VERSION "dbc-export 1 2025.20.8"

NS_ :

BS_:

BU_: ADSP APB APP APS APSB BB BMS CC CMP CMPD CP DAS DI DIF DIR DPB EPAS3P EPAS3S EPASTP EPASTS EPBL EPBR ESP GTW HVP IBST ICR IDB OCS1P ODIN PARK PCS PLG PM PMF PMR PTC RADC RCM RCM2 RCU SCCM SDCR TAS TCU TPMS TRCM UDS UI UIS UMC USM VC VCFRONT VCLEFT VCRIGHT VCSEC

BO_ 999 DPB_alertMatrix: 8 DPB
 SG_ DPB_matrixIndex M : 0|4@1+ (1,0) [0|15] "" Vector__XXX
 SG_ DPB_a001_pPlungerSensorOffsetHig m0 : 4|1@1+ (1,0) [0|1] "" Vector__XXX
 SG_ DPB_a002_pMC2SensorOffsetHigh m0 : 5|1@1+ (1,0) [0|1] "" Vector__XXX
 SG_ DPB_a003_AswEEPROMReadFailure m0 : 6|1@1+ (1,0) [0|1] "" Vector__XXX
 SG_ DPB_a004_assertionFault m0 : 7|1@1+ (1,0) [0|1] "" Vector__XXX
 SG_ DPB_a005_hardPedalChar m0 : 8|1@1+ (1,0) [0|1] "" Vector__XXX
 SG_ DPB_a006_hardPedalCharGoodCheck m0 : 9|1@1+ (1,0) [0|1] "" Vector__XXX
 SG_ DPB_a007_PMCLeakageDetected m0 : 10|1@1+ (1,0) [0|1] "" Vector__XXX
 SG_ DPB_a008_LiPSPts1Offset m0 : 11|1@1+ (1,0) [0|1] "" Vector__XXX
 SG_ DPB_a009_LiPSPts2Offset m0 : 12|1@1+ (1,0) [0|1] "" Vector__XXX
 SG_ DPB_a010_LiPSPtsConsistency m0 : 13|1@1+ (1,0) [0|1] "" Vector__XXX
 SG_ DPB_a011_PtsNonZeroStage1 m0 : 14|1@1+ (1,0) [0|1] "" Vector__XXX
 SG_ DPB_a012_PtsNonZeroStage2 m0 : 15|1@1+ (1,0) [0|1] "" Vector__XXX
 SG_ DPB_a013_softPedalChar m0 : 16|1@1+ (1,0) [0|1] "" Vector__XXX
 SG_ DPB_a014_CANControllerHWFault m0 : 17|1@1+ (1,0) [0|1] "" Vector__XXX
 SG_ DPB_a015_CAN1BusOff m0 : 18|1@1+ (1,0) [0|1] "" Vector__XXX
 SG_ DPB_a016_CAN2BusOff m0 : 19|1@1+ (1,0) [0|1] "" Vector__XXX
 SG_ DPB_a017_largeLeakageDetected m0 : 20|1@1+ (1,0) [0|1] "" Vector__XXX
 SG_ DPB_a018_largeLeakageDetectedGoo m0 : 21|1@1+ (1,0) [0|1] "" Vector__XXX
 SG_ DPB_a019_DETReportError m0 : 22|1@1+ (1,0) [0|1] "" Vector__XXX
 SG_ DPB_a020_ecuHuMismatch m0 : 23|1@1+ (1,0) [0|1] "" Vector__XXX
 SG_ DPB_a021_brakeSystemOverheatLvl1 m0 : 24|1@1+ (1,0) [0|1] "" Vector__XXX
 SG_ DPB_a022_brakeSystemOverheatLvl2 m0 : 25|1@1+ (1,0) [0|1] "" Vector__XXX
 SG_ DPB_a023_initialPlungerCheckFail m0 : 26|1@1+ (1,0) [0|1] "" Vector__XXX
 SG_ DPB_a024_ESPLDMFailure m0 : 27|1@1+ (1,0) [0|1] "" Vector__XXX
 SG_ DPB_a025_backupCircuitLeakage m0 : 28|1@1+ (1,0) [0|1] "" Vector__XXX
 SG_ DPB_a026_LiPSIDTimeout m0 : 29|1@1+ (1,0) [0|1] "" Vector__XXX
 SG_ DPB_a027_motorTempHighLevel1 m0 : 30|1@1+ (1,0) [0|1] "" Vector__XXX
 SG_ DPB_a028_motorTempHighLevel2 m0 : 31|1@1+ (1,0) [0|1] "" Vector__XXX
 SG_ DPB_a029_motorTestFault m0 : 32|1@1+ (1,0) [0|1] "" Vector__XXX
 SG_ DPB_a030_notShutDownRight m0 : 33|1@1+ (1,0) [0|1] "" Vector__XXX
 SG_ DPB_a031_HWParamReadFailed m0 : 34|1@1+ (1,0) [0|1] "" Vector__XXX
 SG_ DPB_a032_HWParamWriteFailed m0 : 35|1@1+ (1,0) [0|1] "" Vector__XXX
 SG_ DPB_a033_motorDynamicLimited m0 : 36|1@1+ (1,0) [0|1] "" Vector__XXX
 SG_ DPB_a034_lipsMemoryEmpty m0 : 37|1@1+ (1,0) [0|1] "" Vector__XXX
 SG_ DPB_a035_PDURouterinitialization m0 : 38|1@1+ (1,0) [0|1] "" Vector__XXX
 SG_ DPB_a036_lossOfPDUInstanceDetect m0 : 39|1@1+ (1,0) [0|1] "" Vector__XXX
 SG_ DPB_a037_plungerCircuitPressHigh m0 : 40|1@1+ (1,0) [0|1] "" Vector__XXX
 SG_ DPB_a038_plungerCircuitPressHigh m0 : 41|1@1+ (1,0) [0|1] "" Vector__XXX
 SG_ DPB_a039_plungerCircuitPressLow m0 : 42|1@1+ (1,0) [0|1] "" Vector__XXX
 SG_ DPB_a040_plungerCircuitPressLowG m0 : 43|1@1+ (1,0) [0|1] "" Vector__XXX
 SG_ DPB_a041_PSCGearRatioReadFault m0 : 44|1@1+ (1,0) [0|1] "" Vector__XXX
 SG_ DPB_a042_motorLoadPressImplausib m0 : 45|1@1+ (1,0) [0|1] "" Vector__XXX
 SG_ DPB_a043_PSCMotorSizeReadFault m0 : 46|1@1+ (1,0) [0|1] "" Vector__XXX
 SG_ DPB_a044_supplyOvervoltageLvl1 m0 : 47|1@1+ (1,0) [0|1] "" Vector__XXX
 SG_ DPB_a045_supplyOvervoltageLvl2 m0 : 48|1@1+ (1,0) [0|1] "" Vector__XXX
 SG_ DPB_a046_supplyOvervoltageLvl3 m0 : 49|1@1+ (1,0) [0|1] "" Vector__XXX
 SG_ DPB_a047_pPlungerPlausCheckFailu m0 : 50|1@1+ (1,0) [0|1] "" Vector__XXX
 SG_ DPB_a048_supplyUndervoltageLvl1 m0 : 51|1@1+ (1,0) [0|1] "" Vector__XXX
 SG_ DPB_a049_supplyUndervoltageLvl2 m0 : 52|1@1+ (1,0) [0|1] "" Vector__XXX
 SG_ DPB_a050_supplyUndervoltageLvl3 m0 : 53|1@1+ (1,0) [0|1] "" Vector__XXX
 SG_ DPB_a051_PSCVoltageImplausible m0 : 54|1@1+ (1,0) [0|1] "" Vector__XXX
 SG_ DPB_a052_PSIDTimeOut m0 : 55|1@1+ (1,0) [0|1] "" Vector__XXX
 SG_ DPB_a053_hydraulicAssemblyModeAc m0 : 56|1@1+ (1,0) [0|1] "" Vector__XXX
 SG_ DPB_a054_unsupportedHW m0 : 57|1@1+ (1,0) [0|1] "" Vector__XXX
 SG_ DPB_a055_unsupportedSeriesHWDete m0 : 58|1@1+ (1,0) [0|1] "" Vector__XXX
 SG_ DPB_a056_AdcPeripheralFault m0 : 59|1@1+ (1,0) [0|1] "" Vector__XXX
 SG_ DPB_a057_AdcPinTest m0 : 60|1@1+ (1,0) [0|1] "" Vector__XXX
 SG_ DPB_a058_AdcSelftestC5P m0 : 61|1@1+ (1,0) [0|1] "" Vector__XXX
 SG_ DPB_a059_factoryModeActive m0 : 62|1@1+ (1,0) [0|1] "" Vector__XXX
 SG_ DPB_a060_motorBridgeDriverFault m0 : 63|1@1+ (1,0) [0|1] "" Vector__XXX
 SG_ DPB_a061_bridgeSwitchInitError m1 : 4|1@1+ (1,0) [0|1] "" Vector__XXX
 SG_ DPB_a062_loadDumpOnFSLTest m1 : 5|1@1+ (1,0) [0|1] "" Vector__XXX
 SG_ DPB_a063_motorConfigMismatch m1 : 6|1@1+ (1,0) [0|1] "" Vector__XXX
 SG_ DPB_a064_current1OffsetHigh m1 : 7|1@1+ (1,0) [0|1] "" Vector__XXX
 SG_ DPB_a065_current1OffsetLow m1 : 8|1@1+ (1,0) [0|1] "" Vector__XXX
 SG_ DPB_a066_current2OffsetHigh m1 : 9|1@1+ (1,0) [0|1] "" Vector__XXX
 SG_ DPB_a067_current2OffsetLow m1 : 10|1@1+ (1,0) [0|1] "" Vector__XXX
 SG_ DPB_a068_BLMMuxerTimeoutError m1 : 11|1@1+ (1,0) [0|1] "" Vector__XXX
 SG_ DPB_a069_OBDCurrent1OORHigh m1 : 12|1@1+ (1,0) [0|1] "" Vector__XXX
 SG_ DPB_a070_OBDCurrent1OORLow m1 : 13|1@1+ (1,0) [0|1] "" Vector__XXX
 SG_ DPB_a071_OBDCurrent2OORHigh m1 : 14|1@1+ (1,0) [0|1] "" Vector__XXX
 SG_ DPB_a072_OBDCurrent2OORLow m1 : 15|1@1+ (1,0) [0|1] "" Vector__XXX
 SG_ DPB_a073_rotorCosOutOfRangeHigh m1 : 16|1@1+ (1,0) [0|1] "" Vector__XXX
 SG_ DPB_a074_rotorCosOutOfRangeLow m1 : 17|1@1+ (1,0) [0|1] "" Vector__XXX
 SG_ DPB_a075_rotorSinOutOfRangeHigh m1 : 18|1@1+ (1,0) [0|1] "" Vector__XXX
 SG_ DPB_a076_rotorSinOutOfRangeLow m1 : 19|1@1+ (1,0) [0|1] "" Vector__XXX
 SG_ DPB_a077_tempSens1ShortToSupply m1 : 20|1@1+ (1,0) [0|1] "" Vector__XXX
 SG_ DPB_a078_tempSens1ShortToGround m1 : 21|1@1+ (1,0) [0|1] "" Vector__XXX
 SG_ DPB_a079_tempSens2ShortToSupply m1 : 22|1@1+ (1,0) [0|1] "" Vector__XXX
 SG_ DPB_a080_tempSens2ShortToGround m1 : 23|1@1+ (1,0) [0|1] "" Vector__XXX
 SG_ DPB_a081_tempSensImplausVoltage m1 : 24|1@1+ (1,0) [0|1] "" Vector__XXX
 SG_ DPB_a082_chargePumpFault m1 : 25|1@1+ (1,0) [0|1] "" Vector__XXX
 SG_ DPB_a083_chargePumpUndervoltage m1 : 26|1@1+ (1,0) [0|1] "" Vector__XXX
 SG_ DPB_a084_RBCPUException m1 : 27|1@1+ (1,0) [0|1] "" Vector__XXX
 SG_ DPB_a085_infoFailureWrongCUBASHa m1 : 28|1@1+ (1,0) [0|1] "" Vector__XXX
 SG_ DPB_a086_diagHydProtectionPressF m1 : 29|1@1+ (1,0) [0|1] "" Vector__XXX
 SG_ DPB_a087_diagHydProtectionVlvFau m1 : 30|1@1+ (1,0) [0|1] "" Vector__XXX
 SG_ DPB_a088_DMATransferError m1 : 31|1@1+ (1,0) [0|1] "" Vector__XXX
 SG_ DPB_a089_ecuBandgap m1 : 32|1@1+ (1,0) [0|1] "" Vector__XXX
 SG_ DPB_a090_flashFault m1 : 33|1@1+ (1,0) [0|1] "" Vector__XXX
 SG_ DPB_a091_MRGPathTestFault m1 : 34|1@1+ (1,0) [0|1] "" Vector__XXX
 SG_ DPB_a092_decoupleBitTestFault m1 : 35|1@1+ (1,0) [0|1] "" Vector__XXX
 SG_ DPB_a093_ecuBistFaultCtrFault m1 : 36|1@1+ (1,0) [0|1] "" Vector__XXX
 SG_ DPB_a094_ecuClockTestFault m1 : 37|1@1+ (1,0) [0|1] "" Vector__XXX
 SG_ DPB_a095_ecuEnableElHighFault m1 : 38|1@1+ (1,0) [0|1] "" Vector__XXX
 SG_ DPB_a096_ecuEnableElLowFault m1 : 39|1@1+ (1,0) [0|1] "" Vector__XXX
 SG_ DPB_a097_ecuEnableHyHighFault m1 : 40|1@1+ (1,0) [0|1] "" Vector__XXX
 SG_ DPB_a098_ecuEnableHyLowFault m1 : 41|1@1+ (1,0) [0|1] "" Vector__XXX
 SG_ DPB_a099_ecuEnContinuousError m1 : 42|1@1+ (1,0) [0|1] "" Vector__XXX
 SG_ DPB_a100_ecuErrpinCounterFault m1 : 43|1@1+ (1,0) [0|1] "" Vector__XXX
 SG_ DPB_a101_ecuFastWdTestFault m1 : 44|1@1+ (1,0) [0|1] "" Vector__XXX
 SG_ DPB_a102_ecuVrOnWhileWdTimeout m1 : 45|1@1+ (1,0) [0|1] "" Vector__XXX
 SG_ DPB_a103_ecuVrViaSpiFails m1 : 46|1@1+ (1,0) [0|1] "" Vector__XXX
 SG_ DPB_a104_ecuWdStartuptestFault m1 : 47|1@1+ (1,0) [0|1] "" Vector__XXX
 SG_ DPB_a105_ecuWdSContinuousError m1 : 48|1@1+ (1,0) [0|1] "" Vector__XXX
 SG_ DPB_a106_ecuBistCmdTestFault m1 : 49|1@1+ (1,0) [0|1] "" Vector__XXX
 SG_ DPB_a107_vrOnFails m1 : 50|1@1+ (1,0) [0|1] "" Vector__XXX
 SG_ DPB_a108_GTMRefFrequencyError m1 : 51|1@1+ (1,0) [0|1] "" Vector__XXX
 SG_ DPB_a109_GTMTbuMonError m1 : 52|1@1+ (1,0) [0|1] "" Vector__XXX
 SG_ DPB_a110_HWBISTError m1 : 53|1@1+ (1,0) [0|1] "" Vector__XXX
 SG_ DPB_a111_hydraulicHardUndervolta m1 : 54|1@1+ (1,0) [0|1] "" Vector__XXX
 SG_ DPB_a112_hydraulicUndervoltage m1 : 55|1@1+ (1,0) [0|1] "" Vector__XXX
 SG_ DPB_a113_LiPS1SentLineHigh m1 : 56|1@1+ (1,0) [0|1] "" Vector__XXX
 SG_ DPB_a114_LiPS1SentLineLow m1 : 57|1@1+ (1,0) [0|1] "" Vector__XXX
 SG_ DPB_a115_LiPS1SentSensor m1 : 58|1@1+ (1,0) [0|1] "" Vector__XXX
 SG_ DPB_a116_LiPS1SentTransmission m1 : 59|1@1+ (1,0) [0|1] "" Vector__XXX
 SG_ DPB_a117_LiPS2PwmLineHigh m1 : 60|1@1+ (1,0) [0|1] "" Vector__XXX
 SG_ DPB_a118_LiPS2PwmLineLow m1 : 61|1@1+ (1,0) [0|1] "" Vector__XXX
 SG_ DPB_a119_LiPS2PwmTransmission m1 : 62|1@1+ (1,0) [0|1] "" Vector__XXX
 SG_ DPB_a120_LiPSOutOfRangeHigh m1 : 63|1@1+ (1,0) [0|1] "" Vector__XXX
 SG_ DPB_a121_LiPSOutOfRangeLow m2 : 4|1@1+ (1,0) [0|1] "" Vector__XXX
 SG_ DPB_a122_micAsicClkInError m2 : 5|1@1+ (1,0) [0|1] "" Vector__XXX
 SG_ DPB_a123_micAsicInitTestError m2 : 6|1@1+ (1,0) [0|1] "" Vector__XXX
 SG_ DPB_a124_asicOscillatorError m2 : 7|1@1+ (1,0) [0|1] "" Vector__XXX
 SG_ DPB_a125_B6AsicFault m2 : 8|1@1+ (1,0) [0|1] "" Vector__XXX
 SG_ DPB_a126_MICB6TransferError m2 : 9|1@1+ (1,0) [0|1] "" Vector__XXX
 SG_ DPB_a127_hydraulicAsicShortCircu m2 : 10|1@1+ (1,0) [0|1] "" Vector__XXX
 SG_ DPB_a128_micSpiTransferError m2 : 11|1@1+ (1,0) [0|1] "" Vector__XXX
 SG_ DPB_a129_AsicTrimmingNotComplete m2 : 12|1@1+ (1,0) [0|1] "" Vector__XXX
 SG_ DPB_a130_AsicMalfunctionDetected m2 : 13|1@1+ (1,0) [0|1] "" Vector__XXX
 SG_ DPB_a131_ASICOvercurrentOnGPIO25 m2 : 14|1@1+ (1,0) [0|1] "" Vector__XXX
 SG_ DPB_a132_ASICOvercurrentOnGPIO25 m2 : 15|1@1+ (1,0) [0|1] "" Vector__XXX
 SG_ DPB_a133_ASICOvercurrentOnGPIO50 m2 : 16|1@1+ (1,0) [0|1] "" Vector__XXX
 SG_ DPB_a134_ASICOvercurrentOnGPIO50 m2 : 17|1@1+ (1,0) [0|1] "" Vector__XXX
 SG_ DPB_a135_ASICOvercurrentOnGPIO50 m2 : 18|1@1+ (1,0) [0|1] "" Vector__XXX
 SG_ DPB_a136_ASICOvercurrentOnGPIO50 m2 : 19|1@1+ (1,0) [0|1] "" Vector__XXX
 SG_ DPB_a137_ASICOvercurrentOnWRHS m2 : 20|1@1+ (1,0) [0|1] "" Vector__XXX
 SG_ DPB_a138_DIchassisControlCounter m2 : 21|1@1+ (1,0) [0|1] "" Vector__XXX
 SG_ DPB_a139_DIchassisControlChecksu m2 : 22|1@1+ (1,0) [0|1] "" Vector__XXX
 SG_ DPB_a140_DIchassisControlDLC m2 : 23|1@1+ (1,0) [0|1] "" Vector__XXX
 SG_ DPB_a141_DIchassisControlTimeout m2 : 24|1@1+ (1,0) [0|1] "" Vector__XXX
 SG_ DPB_a142_DIsystemStatusCounter m2 : 25|1@1+ (1,0) [0|1] "" Vector__XXX
 SG_ DPB_a143_DIsystemStatusChecksum m2 : 26|1@1+ (1,0) [0|1] "" Vector__XXX
 SG_ DPB_a144_DIsystemStatusDLC m2 : 27|1@1+ (1,0) [0|1] "" Vector__XXX
 SG_ DPB_a145_DIsystemStatusTimeout m2 : 28|1@1+ (1,0) [0|1] "" Vector__XXX
 SG_ DPB_a146_DIFtorqueCounter m2 : 29|1@1+ (1,0) [0|1] "" Vector__XXX
 SG_ DPB_a147_DIFtorqueChecksum m2 : 30|1@1+ (1,0) [0|1] "" Vector__XXX
 SG_ DPB_a148_DIFtorqueDLC m2 : 31|1@1+ (1,0) [0|1] "" Vector__XXX
 SG_ DPB_a149_DIFtorqueTimeout m2 : 32|1@1+ (1,0) [0|1] "" Vector__XXX
 SG_ DPB_a150_DIRtorqueCounter m2 : 33|1@1+ (1,0) [0|1] "" Vector__XXX
 SG_ DPB_a151_DIRtorqueChecksum m2 : 34|1@1+ (1,0) [0|1] "" Vector__XXX
 SG_ DPB_a152_DIRtorqueDLC m2 : 35|1@1+ (1,0) [0|1] "" Vector__XXX
 SG_ DPB_a153_DIRtorqueTimeout m2 : 36|1@1+ (1,0) [0|1] "" Vector__XXX
 SG_ DPB_a154_EPBLstatusCounter m2 : 37|1@1+ (1,0) [0|1] "" Vector__XXX
 SG_ DPB_a155_EPBLstatusChecksum m2 : 38|1@1+ (1,0) [0|1] "" Vector__XXX
 SG_ DPB_a156_EPBLstatusDLC m2 : 39|1@1+ (1,0) [0|1] "" Vector__XXX
 SG_ DPB_a157_EPBLstatusTimeout m2 : 40|1@1+ (1,0) [0|1] "" Vector__XXX
 SG_ DPB_a158_EPBRstatusCounter m2 : 41|1@1+ (1,0) [0|1] "" Vector__XXX
 SG_ DPB_a159_EPBRstatusChecksum m2 : 42|1@1+ (1,0) [0|1] "" Vector__XXX
 SG_ DPB_a160_EPBRstatusDLC m2 : 43|1@1+ (1,0) [0|1] "" Vector__XXX
 SG_ DPB_a161_EPBRstatusTimeout m2 : 44|1@1+ (1,0) [0|1] "" Vector__XXX
 SG_ DPB_a162_ESP_modulator1Counter m2 : 45|1@1+ (1,0) [0|1] "" Vector__XXX
 SG_ DPB_a163_ESP_modulator1Checksum m2 : 46|1@1+ (1,0) [0|1] "" Vector__XXX
 SG_ DPB_a164_ESP_modulator1DLC m2 : 47|1@1+ (1,0) [0|1] "" Vector__XXX
 SG_ DPB_a165_ESP_modulator1Timeout m2 : 48|1@1+ (1,0) [0|1] "" Vector__XXX
 SG_ DPB_a166_ESP_chassis3Counter m2 : 49|1@1+ (1,0) [0|1] "" Vector__XXX
 SG_ DPB_a167_ESP_chassis3Checksum m2 : 50|1@1+ (1,0) [0|1] "" Vector__XXX
 SG_ DPB_a168_ESP_chassis3DLC m2 : 51|1@1+ (1,0) [0|1] "" Vector__XXX
 SG_ DPB_a169_ESP_chassis3Timeout m2 : 52|1@1+ (1,0) [0|1] "" Vector__XXX
 SG_ DPB_a170_ESP_modulator2Counter m2 : 53|1@1+ (1,0) [0|1] "" Vector__XXX
 SG_ DPB_a171_ESP_modulator2Checksum m2 : 54|1@1+ (1,0) [0|1] "" Vector__XXX
 SG_ DPB_a172_ESP_modulator2DLC m2 : 55|1@1+ (1,0) [0|1] "" Vector__XXX
 SG_ DPB_a173_ESP_modulator2Timeout m2 : 56|1@1+ (1,0) [0|1] "" Vector__XXX
 SG_ DPB_a174_ESP_modulator3Counter m2 : 57|1@1+ (1,0) [0|1] "" Vector__XXX
 SG_ DPB_a175_ESP_modulator3Checksum m2 : 58|1@1+ (1,0) [0|1] "" Vector__XXX
 SG_ DPB_a176_ESP_modulator3DLC m2 : 59|1@1+ (1,0) [0|1] "" Vector__XXX
 SG_ DPB_a177_ESP_modulator3Timeout m2 : 60|1@1+ (1,0) [0|1] "" Vector__XXX
 SG_ DPB_a178_PMstate2Counter m2 : 61|1@1+ (1,0) [0|1] "" Vector__XXX
 SG_ DPB_a179_PMstate2Checksum m2 : 62|1@1+ (1,0) [0|1] "" Vector__XXX
 SG_ DPB_a180_PMstate2DLC m2 : 63|1@1+ (1,0) [0|1] "" Vector__XXX
 SG_ DPB_a181_PMstate2Timeout m3 : 4|1@1+ (1,0) [0|1] "" Vector__XXX
 SG_ DPB_a182_RCMInertial2Counter m3 : 5|1@1+ (1,0) [0|1] "" Vector__XXX
 SG_ DPB_a183_RCMInertial2Checksum m3 : 6|1@1+ (1,0) [0|1] "" Vector__XXX
 SG_ DPB_a184_RCMInertial2DLC m3 : 7|1@1+ (1,0) [0|1] "" Vector__XXX
 SG_ DPB_a185_RCMInertial2Timeout m3 : 8|1@1+ (1,0) [0|1] "" Vector__XXX
 SG_ DPB_a186_LVPowerStateTimeout m3 : 9|1@1+ (1,0) [0|1] "" Vector__XXX
 SG_ DPB_a187_LVPowerStateChecksum m3 : 10|1@1+ (1,0) [0|1] "" Vector__XXX
 SG_ DPB_a188_LVPowerStateDLC m3 : 11|1@1+ (1,0) [0|1] "" Vector__XXX
 SG_ DPB_a189_LVPowerStateCounter m3 : 12|1@1+ (1,0) [0|1] "" Vector__XXX
 SG_ DPB_a190_VCLEFTepbmStatusCounter m3 : 13|1@1+ (1,0) [0|1] "" Vector__XXX
 SG_ DPB_a191_VCLEFTepbmStatusChecksu m3 : 14|1@1+ (1,0) [0|1] "" Vector__XXX
 SG_ DPB_a192_VCLEFTepbmStatusDLC m3 : 15|1@1+ (1,0) [0|1] "" Vector__XXX
 SG_ DPB_a193_VCLEFTepbmStatusTimeout m3 : 16|1@1+ (1,0) [0|1] "" Vector__XXX
 SG_ DPB_a194_VCRIGHTepbmStatusCounte m3 : 17|1@1+ (1,0) [0|1] "" Vector__XXX
 SG_ DPB_a195_VCRIGHTepbmStatusChecks m3 : 18|1@1+ (1,0) [0|1] "" Vector__XXX
 SG_ DPB_a196_VCRIGHTepbmStatusDLC m3 : 19|1@1+ (1,0) [0|1] "" Vector__XXX
 SG_ DPB_a197_VCRIGHTepbmStatusTimeou m3 : 20|1@1+ (1,0) [0|1] "" Vector__XXX
 SG_ DPB_a198_CANOvervoltage m3 : 21|1@1+ (1,0) [0|1] "" Vector__XXX
 SG_ DPB_a199_pMC1QFaulty m3 : 22|1@1+ (1,0) [0|1] "" Vector__XXX
 SG_ DPB_a200_ESPRunoutSupportNotAvai m3 : 23|1@1+ (1,0) [0|1] "" Vector__XXX
 SG_ DPB_a201_vehicleSpeedQFaulty m3 : 24|1@1+ (1,0) [0|1] "" Vector__XXX
 SG_ DPB_a202_vehicleStandstillQFault m3 : 25|1@1+ (1,0) [0|1] "" Vector__XXX
 SG_ DPB_a203_ABSNotAvailable m3 : 26|1@1+ (1,0) [0|1] "" Vector__XXX
 SG_ DPB_a204_CANUndervoltage m3 : 27|1@1+ (1,0) [0|1] "" Vector__XXX
 SG_ DPB_a205_NvMWriteCycleExceed m3 : 28|1@1+ (1,0) [0|1] "" Vector__XXX
 SG_ DPB_a206_OSTaskSchemeError m3 : 29|1@1+ (1,0) [0|1] "" Vector__XXX
 SG_ DPB_a207_hydraulicOvervoltage m3 : 30|1@1+ (1,0) [0|1] "" Vector__XXX
 SG_ DPB_a208_pressureSensor1Short m3 : 31|1@1+ (1,0) [0|1] "" Vector__XXX
 SG_ DPB_a209_pressureSensor1High m3 : 32|1@1+ (1,0) [0|1] "" Vector__XXX
 SG_ DPB_a210_pressureSensor1Low m3 : 33|1@1+ (1,0) [0|1] "" Vector__XXX
 SG_ DPB_a211_pressureSensor1Fault m3 : 34|1@1+ (1,0) [0|1] "" Vector__XXX
 SG_ DPB_a212_pressureSensor1Temp m3 : 35|1@1+ (1,0) [0|1] "" Vector__XXX
 SG_ DPB_a213_pressureSensor1Fault m3 : 36|1@1+ (1,0) [0|1] "" Vector__XXX
 SG_ DPB_a214_pressureSensor2Short m3 : 37|1@1+ (1,0) [0|1] "" Vector__XXX
 SG_ DPB_a215_pressureSensor2High m3 : 38|1@1+ (1,0) [0|1] "" Vector__XXX
 SG_ DPB_a216_pressureSensor2Low m3 : 39|1@1+ (1,0) [0|1] "" Vector__XXX
 SG_ DPB_a217_pressureSensor2Fault m3 : 40|1@1+ (1,0) [0|1] "" Vector__XXX
 SG_ DPB_a218_pressureSensor2Temp m3 : 41|1@1+ (1,0) [0|1] "" Vector__XXX
 SG_ DPB_a219_pressureSensor2Fault m3 : 42|1@1+ (1,0) [0|1] "" Vector__XXX
 SG_ DPB_a220_excessiveBoostWakeupsDe m3 : 43|1@1+ (1,0) [0|1] "" Vector__XXX
 SG_ DPB_a221_notShutdownRight m3 : 44|1@1+ (1,0) [0|1] "" Vector__XXX
 SG_ DPB_a222_excessiveEcuResetsDetec m3 : 45|1@1+ (1,0) [0|1] "" Vector__XXX
 SG_ DPB_a223_RAMFault m3 : 46|1@1+ (1,0) [0|1] "" Vector__XXX
 SG_ DPB_a224_brakeBoostLost m3 : 47|1@1+ (1,0) [0|1] "" Vector__XXX
 SG_ DPB_a225_U5VOutOfRange m3 : 48|1@1+ (1,0) [0|1] "" Vector__XXX
 SG_ DPB_a226_U5VTestFault m3 : 49|1@1+ (1,0) [0|1] "" Vector__XXX
 SG_ DPB_a227_brakeFluidLoss m3 : 50|1@1+ (1,0) [0|1] "" Vector__XXX
 SG_ DPB_a228_supplyASICInitFault m3 : 51|1@1+ (1,0) [0|1] "" Vector__XXX
 SG_ DPB_a229_IREFOutOfRange m3 : 52|1@1+ (1,0) [0|1] "" Vector__XXX
 SG_ DPB_a230_OSErrorHook m3 : 53|1@1+ (1,0) [0|1] "" Vector__XXX
 SG_ DPB_a231_stackOverUnderFlow m3 : 54|1@1+ (1,0) [0|1] "" Vector__XXX
 SG_ DPB_a232_systemErrorHook m3 : 55|1@1+ (1,0) [0|1] "" Vector__XXX
 SG_ DPB_a233_systemTaskJitter m3 : 56|1@1+ (1,0) [0|1] "" Vector__XXX
 SG_ DPB_a234_systemTaskOverRun m3 : 57|1@1+ (1,0) [0|1] "" Vector__XXX
 SG_ DPB_a235_UB6PlausiMonFault m3 : 58|1@1+ (1,0) [0|1] "" Vector__XXX
 SG_ DPB_a236_UB6SupplyPathFault m3 : 59|1@1+ (1,0) [0|1] "" Vector__XXX
 SG_ DPB_a237_uCVoltageDividerDrift m3 : 60|1@1+ (1,0) [0|1] "" Vector__XXX
 SG_ DPB_a238_microRegisterFault m3 : 61|1@1+ (1,0) [0|1] "" Vector__XXX
 SG_ DPB_a239_microSafetyFault m3 : 62|1@1+ (1,0) [0|1] "" Vector__XXX
 SG_ DPB_a240_microSafetyLogicFault m3 : 63|1@1+ (1,0) [0|1] "" Vector__XXX
 SG_ DPB_a241_uCSafetyNotification m4 : 4|1@1+ (1,0) [0|1] "" Vector__XXX
 SG_ DPB_a242_uCSafetyNotificationGRA m4 : 5|1@1+ (1,0) [0|1] "" Vector__XXX
 SG_ DPB_a243_microSupplyError m4 : 6|1@1+ (1,0) [0|1] "" Vector__XXX
 SG_ DPB_a244_valvesGenericFault m4 : 7|1@1+ (1,0) [0|1] "" Vector__XXX
 SG_ DPB_a245_valveMV0Fault m4 : 8|1@1+ (1,0) [0|1] "" Vector__XXX
 SG_ DPB_a246_valveMV5Fault m4 : 9|1@1+ (1,0) [0|1] "" Vector__XXX
 SG_ DPB_a247_valveMV6Fault m4 : 10|1@1+ (1,0) [0|1] "" Vector__XXX
 SG_ DPB_a248_valveMV61Fault m4 : 11|1@1+ (1,0) [0|1] "" Vector__XXX
 SG_ DPB_a249_valveMV62Fault m4 : 12|1@1+ (1,0) [0|1] "" Vector__XXX
 SG_ DPB_a250_valveMV7Fault m4 : 13|1@1+ (1,0) [0|1] "" Vector__XXX
 SG_ DPB_a251_valveMV8Fault m4 : 14|1@1+ (1,0) [0|1] "" Vector__XXX
 SG_ DPB_a252_valveMV81Fault m4 : 15|1@1+ (1,0) [0|1] "" Vector__XXX
 SG_ DPB_a253_valveMV82Fault m4 : 16|1@1+ (1,0) [0|1] "" Vector__XXX
 SG_ DPB_a254_valveMV9Fault m4 : 17|1@1+ (1,0) [0|1] "" Vector__XXX
 SG_ DPB_a255_valveRelayShort m4 : 18|1@1+ (1,0) [0|1] "" Vector__XXX
 SG_ DPB_a256_valveRelayActuationFaul m4 : 19|1@1+ (1,0) [0|1] "" Vector__XXX
 SG_ DPB_a257_valveRelayOnContinuous m4 : 20|1@1+ (1,0) [0|1] "" Vector__XXX
 SG_ DPB_a258_valveRelayOffContinuous m4 : 21|1@1+ (1,0) [0|1] "" Vector__XXX
 SG_ DPB_a259_valveRelayTestUndervolt m4 : 22|1@1+ (1,0) [0|1] "" Vector__XXX
 SG_ DPB_a260_valveRelaySafetySwitchF m4 : 23|1@1+ (1,0) [0|1] "" Vector__XXX
 SG_ DPB_a261_WdhAsicWdCmdMissing m4 : 24|1@1+ (1,0) [0|1] "" Vector__XXX
 SG_ DPB_a262_WdhAsicWdErrorCntLimit m4 : 25|1@1+ (1,0) [0|1] "" Vector__XXX
 SG_ DPB_a263_WdhAsicWdErrorCntStuck m4 : 26|1@1+ (1,0) [0|1] "" Vector__XXX
 SG_ DPB_a264_WdhSwBistConCnt m4 : 27|1@1+ (1,0) [0|1] "" Vector__XXX
 SG_ DPB_a265_WdhTaskMonConCnt m4 : 28|1@1+ (1,0) [0|1] "" Vector__XXX
 SG_ DPB_a266_RPSNvMReadFault m4 : 29|1@1+ (1,0) [0|1] "" Vector__XXX
 SG_ DPB_a267_RpsAngleImplausible m4 : 30|1@1+ (1,0) [0|1] "" Vector__XXX
 SG_ DPB_a268_RPSVectorOscillating m4 : 31|1@1+ (1,0) [0|1] "" Vector__XXX
 SG_ DPB_a269_RPSVectorRangeHigh m4 : 32|1@1+ (1,0) [0|1] "" Vector__XXX
 SG_ DPB_a270_RPSVectorRangeLow m4 : 33|1@1+ (1,0) [0|1] "" Vector__XXX
 SG_ DPB_a271_RPSWrongCalibData m4 : 34|1@1+ (1,0) [0|1] "" Vector__XXX
 SG_ DPB_a272_runtimeAssertionFault m4 : 35|1@1+ (1,0) [0|1] "" Vector__XXX
 SG_ DPB_a273_SMMOneRequestsInit m4 : 36|1@1+ (1,0) [0|1] "" Vector__XXX
 SG_ DPB_a274_AswSystemTimeOut m4 : 37|1@1+ (1,0) [0|1] "" Vector__XXX
 SG_ DPB_a275_Ps1Ps2PlausibilityFault m4 : 38|1@1+ (1,0) [0|1] "" Vector__XXX
 SG_ DPB_a276_VCFRONTsensorsCounter m4 : 39|1@1+ (1,0) [0|1] "" Vector__XXX
 SG_ DPB_a277_VCFRONTsensorsChecksum m4 : 40|1@1+ (1,0) [0|1] "" Vector__XXX
 SG_ DPB_a278_VCFRONTsensorsDLC m4 : 41|1@1+ (1,0) [0|1] "" Vector__XXX
 SG_ DPB_a279_VCFRONTsensorsTimeout m4 : 42|1@1+ (1,0) [0|1] "" Vector__XXX
 SG_ DPB_a280_LowBrakeFluid m4 : 43|1@1+ (1,0) [0|1] "" Vector__XXX
 SG_ DPB_a281_brakeFluidOORHigh m4 : 44|1@1+ (1,0) [0|1] "" Vector__XXX
 SG_ DPB_a282_DIbrakeCommandCounter m4 : 45|1@1+ (1,0) [0|1] "" Vector__XXX
 SG_ DPB_a283_DIbrakeCommandChecksum m4 : 46|1@1+ (1,0) [0|1] "" Vector__XXX
 SG_ DPB_a284_DIbrakeCommandDLC m4 : 47|1@1+ (1,0) [0|1] "" Vector__XXX
 SG_ DPB_a285_DIbrakeCommandTimeout m4 : 48|1@1+ (1,0) [0|1] "" Vector__XXX
 SG_ DPB_a286_ebrCmdStateInvalid m4 : 49|1@1+ (1,0) [0|1] "" Vector__XXX
 SG_ DPB_a287_brakeCmdStateInvalid m4 : 50|1@1+ (1,0) [0|1] "" Vector__XXX
 SG_ DPB_a288_PlantDegradedSW m4 : 51|1@1+ (1,0) [0|1] "" Vector__XXX
 SG_ DPB_a289_evacFillNotComplete m4 : 52|1@1+ (1,0) [0|1] "" Vector__XXX
 SG_ DPB_a290_securityInfo m4 : 53|1@1+ (1,0) [0|1] "" Vector__XXX
 SG_ DPB_a291_extDBRRequestTooLow m4 : 54|1@1+ (1,0) [0|1] "" Vector__XXX
 SG_ DPB_a292_CBDS_fillBufferThreshol m4 : 55|1@1+ (1,0) [0|1] "" Vector__XXX
 SG_ DPB_a293_CBDS_fmeInternalEvent m4 : 56|1@1+ (1,0) [0|1] "" Vector__XXX
 SG_ DPB_a294_hbaNormalModeActive m4 : 57|1@1+ (1,0) [0|1] "" Vector__XXX
 SG_ DPB_a295_hbaTrackModeActive m4 : 58|1@1+ (1,0) [0|1] "" Vector__XXX
 SG_ DPB_a296_StatInvalid_DI_FullSNA m4 : 59|1@1+ (1,0) [0|1] "" Vector__XXX
 SG_ DPB_a297_undefinedAlertDetected m4 : 60|1@1+ (1,0) [0|1] "" Vector__XXX
 SG_ DPB_a298_RunningActiveSystemTest m4 : 61|1@1+ (1,0) [0|1] "" Vector__XXX
 SG_ DPB_a299_PM_locStateCounter m4 : 62|1@1+ (1,0) [0|1] "" Vector__XXX
 SG_ DPB_a300_PM_locStateChecksum m4 : 63|1@1+ (1,0) [0|1] "" Vector__XXX
 SG_ DPB_a301_PM_locStateDLC m5 : 4|1@1+ (1,0) [0|1] "" Vector__XXX
 SG_ DPB_a302_PM_locStateTimeout m5 : 5|1@1+ (1,0) [0|1] "" Vector__XXX
 SG_ DPB_a303_actuatingDIFullTorqueCm m5 : 6|1@1+ (1,0) [0|1] "" Vector__XXX
 SG_ DPB_a304_actuatingDITorqueCmd m5 : 7|1@1+ (1,0) [0|1] "" Vector__XXX
 SG_ DPB_a305_DIbrakeTorqueCommandAnd m5 : 8|1@1+ (1,0) [0|1] "" Vector__XXX
 SG_ DPB_a306_actuatorFallbackBasicMa m5 : 9|1@1+ (1,0) [0|1] "" Vector__XXX
 SG_ DPB_a307_actuatorDegradedMap m5 : 10|1@1+ (1,0) [0|1] "" Vector__XXX
 SG_ DPB_a308_hydraulicPushthroughAct m5 : 11|1@1+ (1,0) [0|1] "" Vector__XXX
 SG_ DPB_a309_DIFAxleTorqueInvalid m5 : 12|1@1+ (1,0) [0|1] "" Vector__XXX
 SG_ DPB_a310_DIRAxleTorqueInvalid m5 : 13|1@1+ (1,0) [0|1] "" Vector__XXX
 SG_ DPB_a311_postrunDurationTooLong m5 : 14|1@1+ (1,0) [0|1] "" Vector__XXX
 SG_ DPB_a312_cyclicVolumeCheckDisabl m5 : 15|1@1+ (1,0) [0|1] "" Vector__XXX
 SG_ DPB_a313_qualifiedBrakeEventDete m5 : 16|1@1+ (1,0) [0|1] "" Vector__XXX

BO_ 1426 EPAS3P_alertLog: 8 EPAS3P
 SG_ EPAS3P_alertID M : 0|8@1+ (1,0) [0|255] "" Vector__XXX
 SG_ EPAS3P_alertState : 15|1@1+ (1,0) [0|1] "" Vector__XXX
 SG_ EPAS3P_a147_transitionReason m147 : 16|2@1+ (1,0) [0|3] "" Vector__XXX
 SG_ EPAS3P_a148_vehicleSpeed m148 : 16|10@1+ (0.5,0) [0|511.5] "kph" Vector__XXX
 SG_ EPAS3P_a149_pcbTemp m149 : 16|8@1- (1,60) [-68|187] "degC" Vector__XXX
 SG_ EPAS3P_a150_pcbTemp m150 : 16|8@1- (1,60) [-68|187] "degC" Vector__XXX
 SG_ EPAS3P_a150_phaUMainPathCalcDiff m150 : 24|15@1+ (1,0) [0|32767] "Counts" Vector__XXX
 SG_ EPAS3P_a150_phaVMainPathCalcDiff m150 : 39|15@1+ (1,0) [0|32767] "Counts" Vector__XXX
 SG_ EPAS3P_a150_otherECUAssistStatus m150 : 54|1@1+ (1,0) [0|1] "" Vector__XXX
 SG_ EPAS3P_a151_dcsVBridge m151 : 16|6@1+ (0.328,0) [0|20.664] "Volts" Vector__XXX
 SG_ EPAS3P_a151_dcsMainChannelA m151 : 22|10@1- (0.41,0) [-209.92|209.51] "Amps" Vector__XXX
 SG_ EPAS3P_a151_dcsMainChannelB m151 : 32|10@1- (0.41,0) [-209.92|209.51] "Amps" Vector__XXX
 SG_ EPAS3P_a151_dcsOffsetA m151 : 42|10@1- (1,0) [-512|511] "Counts" Vector__XXX
 SG_ EPAS3P_a151_dcsOffsetB m151 : 52|10@1- (1,0) [-512|511] "Counts" Vector__XXX
 SG_ EPAS3P_a151_dcsCBootA m151 : 62|1@1+ (1,0) [0|1] "" Vector__XXX
 SG_ EPAS3P_a151_dcsCBootB m151 : 63|1@1+ (1,0) [0|1] "" Vector__XXX
 SG_ EPAS3P_a152_dcsVBridge m152 : 16|6@1+ (0.328,0) [0|20.664] "Volts" Vector__XXX
 SG_ EPAS3P_a152_dcsModIndex m152 : 23|7@1+ (1,0) [0|127] "Counts" Vector__XXX
 SG_ EPAS3P_a152_dcsMainPathErrReg m152 : 30|11@1+ (1,0) [0|2047] "Counts" Vector__XXX
 SG_ EPAS3P_a152_dcsTubErrReg m152 : 41|6@1+ (1,0) [0|63] "Counts" Vector__XXX
 SG_ EPAS3P_a152_dcsErrSumReg m152 : 47|10@1+ (1,0) [0|1023] "Counts" Vector__XXX
 SG_ EPAS3P_a152_dcsVbusDiagPathErrRe m152 : 57|7@1+ (1,0) [0|127] "Counts" Vector__XXX
 SG_ EPAS3P_a154_vehicleSpeed m154 : 16|10@1+ (0.5,0) [0|511.5] "kph" Vector__XXX
 SG_ EPAS3P_a155_vehicleSpeed m155 : 16|10@1+ (0.5,0) [0|511.5] "kph" Vector__XXX
 SG_ EPAS3P_a156_vehicleSpeed m156 : 16|10@1+ (0.5,0) [0|511.5] "kph" Vector__XXX

BO_ 2036 EPAS3P_alertMatrix: 8 EPAS3P
 SG_ EPAS3P_matrixIndex M : 0|4@1+ (1,0) [0|15] "" Vector__XXX
 SG_ EPAS3P_a001_sent1Mia m0 : 4|1@1+ (1,0) [0|1] "" Vector__XXX
 SG_ EPAS3P_a002_sent1Error m0 : 5|1@1+ (1,0) [0|1] "" Vector__XXX
 SG_ EPAS3P_a003_trqSens1Supply m0 : 6|1@1+ (1,0) [0|1] "" Vector__XXX
 SG_ EPAS3P_a004_trqSens1Eeprom m0 : 7|1@1+ (1,0) [0|1] "" Vector__XXX
 SG_ EPAS3P_a005_sent2Mia m0 : 8|1@1+ (1,0) [0|1] "" Vector__XXX
 SG_ EPAS3P_a006_sent2Error m0 : 9|1@1+ (1,0) [0|1] "" Vector__XXX
 SG_ EPAS3P_a007_trqSens2Supply m0 : 10|1@1+ (1,0) [0|1] "" Vector__XXX
 SG_ EPAS3P_a008_trqSens2Eeprom m0 : 11|1@1+ (1,0) [0|1] "" Vector__XXX
 SG_ EPAS3P_a009_sentDiff m0 : 12|1@1+ (1,0) [0|1] "" Vector__XXX
 SG_ EPAS3P_a010_trqSensCalError m0 : 13|1@1+ (1,0) [0|1] "" Vector__XXX
 SG_ EPAS3P_a011_currentSensError m0 : 14|1@1+ (1,0) [0|1] "" Vector__XXX
 SG_ EPAS3P_a012_currentSensCalError m0 : 15|1@1+ (1,0) [0|1] "" Vector__XXX
 SG_ EPAS3P_a013_gateDriveError m0 : 16|1@1+ (1,0) [0|1] "" Vector__XXX
 SG_ EPAS3P_a014_gateDriveTxError m0 : 17|1@1+ (1,0) [0|1] "" Vector__XXX
 SG_ EPAS3P_a015_gateDriveEeprom m0 : 18|1@1+ (1,0) [0|1] "" Vector__XXX
 SG_ EPAS3P_a016_phaseUhighUv m0 : 19|1@1+ (1,0) [0|1] "" Vector__XXX
 SG_ EPAS3P_a017_phaseUlowUv m0 : 20|1@1+ (1,0) [0|1] "" Vector__XXX
 SG_ EPAS3P_a018_phaseVhighUv m0 : 21|1@1+ (1,0) [0|1] "" Vector__XXX
 SG_ EPAS3P_a019_phaseVlowUv m0 : 22|1@1+ (1,0) [0|1] "" Vector__XXX
 SG_ EPAS3P_a020_phaseWhighUv m0 : 23|1@1+ (1,0) [0|1] "" Vector__XXX
 SG_ EPAS3P_a021_phaseWlowUv m0 : 24|1@1+ (1,0) [0|1] "" Vector__XXX
 SG_ EPAS3P_a022_phaseUhighOv m0 : 25|1@1+ (1,0) [0|1] "" Vector__XXX
 SG_ EPAS3P_a023_phaseUlowOv m0 : 26|1@1+ (1,0) [0|1] "" Vector__XXX
 SG_ EPAS3P_a024_phaseVhighOv m0 : 27|1@1+ (1,0) [0|1] "" Vector__XXX
 SG_ EPAS3P_a025_phaseVlowOv m0 : 28|1@1+ (1,0) [0|1] "" Vector__XXX
 SG_ EPAS3P_a026_phaseWhighOv m0 : 29|1@1+ (1,0) [0|1] "" Vector__XXX
 SG_ EPAS3P_a027_phaseWlowOv m0 : 30|1@1+ (1,0) [0|1] "" Vector__XXX
 SG_ EPAS3P_a028_phaseUbootUv m0 : 31|1@1+ (1,0) [0|1] "" Vector__XXX
 SG_ EPAS3P_a029_phaseVbootUv m0 : 32|1@1+ (1,0) [0|1] "" Vector__XXX
 SG_ EPAS3P_a030_phaseWbootUv m0 : 33|1@1+ (1,0) [0|1] "" Vector__XXX
 SG_ EPAS3P_a031_abnormalShutdown m0 : 34|1@1+ (1,0) [0|1] "" Vector__XXX
 SG_ EPAS3P_a032_vRegOutputUv m0 : 35|1@1+ (1,0) [0|1] "" Vector__XXX
 SG_ EPAS3P_a033_vRegOutputOv m0 : 36|1@1+ (1,0) [0|1] "" Vector__XXX
 SG_ EPAS3P_a034_vRegError m0 : 37|1@1+ (1,0) [0|1] "" Vector__XXX
 SG_ EPAS3P_a035_vbbSupplyUv m0 : 38|1@1+ (1,0) [0|1] "" Vector__XXX
 SG_ EPAS3P_a036_vbbSupplyOv m0 : 39|1@1+ (1,0) [0|1] "" Vector__XXX
 SG_ EPAS3P_a037_motPos1ParityError m0 : 40|1@1+ (1,0) [0|1] "" Vector__XXX
 SG_ EPAS3P_a038_motPos1Uv m0 : 41|1@1+ (1,0) [0|1] "" Vector__XXX
 SG_ EPAS3P_a039_motPos1MagnetMia m0 : 42|1@1+ (1,0) [0|1] "" Vector__XXX
 SG_ EPAS3P_a040_motPos1LogicError m0 : 43|1@1+ (1,0) [0|1] "" Vector__XXX
 SG_ EPAS3P_a041_motPos1tempError m0 : 44|1@1+ (1,0) [0|1] "" Vector__XXX
 SG_ EPAS3P_a042_motPos2ParityError m0 : 45|1@1+ (1,0) [0|1] "" Vector__XXX
 SG_ EPAS3P_a043_motPos2Uv m0 : 46|1@1+ (1,0) [0|1] "" Vector__XXX
 SG_ EPAS3P_a044_motPos2MagnetMia m0 : 47|1@1+ (1,0) [0|1] "" Vector__XXX
 SG_ EPAS3P_a045_motPos2LogicError m0 : 48|1@1+ (1,0) [0|1] "" Vector__XXX
 SG_ EPAS3P_a046_motPos2tempError m0 : 49|1@1+ (1,0) [0|1] "" Vector__XXX
 SG_ EPAS3P_a047_motPosCorrError m0 : 50|1@1+ (1,0) [0|1] "" Vector__XXX
 SG_ EPAS3P_a048_motPosCalError m0 : 51|1@1+ (1,0) [0|1] "" Vector__XXX
 SG_ EPAS3P_a049_piCtrlError m0 : 52|1@1+ (1,0) [0|1] "" Vector__XXX
 SG_ EPAS3P_a050_mcuSmuError m0 : 53|1@1+ (1,0) [0|1] "" Vector__XXX
 SG_ EPAS3P_a051_mcuSupError m0 : 54|1@1+ (1,0) [0|1] "" Vector__XXX
 SG_ EPAS3P_a052_intWatchdogError m0 : 55|1@1+ (1,0) [0|1] "" Vector__XXX
 SG_ EPAS3P_a053_extWatchdogError m0 : 56|1@1+ (1,0) [0|1] "" Vector__XXX
 SG_ EPAS3P_a054_memoryProtectError m0 : 57|1@1+ (1,0) [0|1] "" Vector__XXX
 SG_ EPAS3P_a055_floatPointError m0 : 58|1@1+ (1,0) [0|1] "" Vector__XXX
 SG_ EPAS3P_a056_battUv m0 : 59|1@1+ (1,0) [0|1] "" Vector__XXX
 SG_ EPAS3P_a057_battUvReduced m0 : 60|1@1+ (1,0) [0|1] "" Vector__XXX
 SG_ EPAS3P_a058_battOv m0 : 61|1@1+ (1,0) [0|1] "" Vector__XXX
 SG_ EPAS3P_a059_battOvReduced m0 : 62|1@1+ (1,0) [0|1] "" Vector__XXX
 SG_ EPAS3P_a060_battBridgeDiff m0 : 63|1@1+ (1,0) [0|1] "" Vector__XXX
 SG_ EPAS3P_a061_bridgeUv m1 : 4|1@1+ (1,0) [0|1] "" Vector__XXX
 SG_ EPAS3P_a062_assistCorrError m1 : 5|1@1+ (1,0) [0|1] "" Vector__XXX
 SG_ EPAS3P_a063_dampCorrError m1 : 6|1@1+ (1,0) [0|1] "" Vector__XXX
 SG_ EPAS3P_a064_phaseCompCorrError m1 : 7|1@1+ (1,0) [0|1] "" Vector__XXX
 SG_ EPAS3P_a065_trqTarCorrError m1 : 8|1@1+ (1,0) [0|1] "" Vector__XXX
 SG_ EPAS3P_a066_returnCorrError m1 : 9|1@1+ (1,0) [0|1] "" Vector__XXX
 SG_ EPAS3P_a067_yawDampCorrError m1 : 10|1@1+ (1,0) [0|1] "" Vector__XXX
 SG_ EPAS3P_a068_hystCorrError m1 : 11|1@1+ (1,0) [0|1] "" Vector__XXX
 SG_ EPAS3P_a069_eacCorrError m1 : 12|1@1+ (1,0) [0|1] "" Vector__XXX
 SG_ EPAS3P_a070_hodCorrError m1 : 13|1@1+ (1,0) [0|1] "" Vector__XXX
 SG_ EPAS3P_a071_vehSpdCorrError m1 : 14|1@1+ (1,0) [0|1] "" Vector__XXX
 SG_ EPAS3P_a072_motFeedFwdError m1 : 15|1@1+ (1,0) [0|1] "" Vector__XXX
 SG_ EPAS3P_a073_motParEstError m1 : 16|1@1+ (1,0) [0|1] "" Vector__XXX
 SG_ EPAS3P_a074_overHeatProtect m1 : 17|1@1+ (1,0) [0|1] "" Vector__XXX
 SG_ EPAS3P_a075_fspPwrCut m1 : 18|1@1+ (1,0) [0|1] "" Vector__XXX
 SG_ EPAS3P_a076_tempSensOutofRange m1 : 19|1@1+ (1,0) [0|1] "" Vector__XXX
 SG_ EPAS3P_a077_highSideFetError m1 : 20|1@1+ (1,0) [0|1] "" Vector__XXX
 SG_ EPAS3P_a078_phaseDisconnectError m1 : 21|1@1+ (1,0) [0|1] "" Vector__XXX
 SG_ EPAS3P_a079_backupCurrentPlaus m1 : 22|1@1+ (1,0) [0|1] "" Vector__XXX
 SG_ EPAS3P_a080_ecuInitArbError m1 : 23|1@1+ (1,0) [0|1] "" Vector__XXX
 SG_ EPAS3P_a081_coggCompError m1 : 24|1@1+ (1,0) [0|1] "" Vector__XXX
 SG_ EPAS3P_a082_polarityCalError m1 : 25|1@1+ (1,0) [0|1] "" Vector__XXX
 SG_ EPAS3P_a083_crcMismatch m1 : 26|1@1+ (1,0) [0|1] "" Vector__XXX
 SG_ EPAS3P_a084_eacCancelled m1 : 27|1@1+ (1,0) [0|1] "" Vector__XXX
 SG_ EPAS3P_a085_canBusOff m1 : 28|1@1+ (1,0) [0|1] "" Vector__XXX
 SG_ EPAS3P_a086_dasMia m1 : 29|1@1+ (1,0) [0|1] "" Vector__XXX
 SG_ EPAS3P_a087_dasCntError m1 : 30|1@1+ (1,0) [0|1] "" Vector__XXX
 SG_ EPAS3P_a088_dasCsError m1 : 31|1@1+ (1,0) [0|1] "" Vector__XXX
 SG_ EPAS3P_a089_espWsMia m1 : 32|1@1+ (1,0) [0|1] "" Vector__XXX
 SG_ EPAS3P_a090_espWsCntError m1 : 33|1@1+ (1,0) [0|1] "" Vector__XXX
 SG_ EPAS3P_a091_espWsCsError m1 : 34|1@1+ (1,0) [0|1] "" Vector__XXX
 SG_ EPAS3P_a092_espWrMia m1 : 35|1@1+ (1,0) [0|1] "" Vector__XXX
 SG_ EPAS3P_a093_espWrCntError m1 : 36|1@1+ (1,0) [0|1] "" Vector__XXX
 SG_ EPAS3P_a094_espWrCsError m1 : 37|1@1+ (1,0) [0|1] "" Vector__XXX
 SG_ EPAS3P_a095_espWsStatus m1 : 38|1@1+ (1,0) [0|1] "" Vector__XXX
 SG_ EPAS3P_a096_rcmMia m1 : 39|1@1+ (1,0) [0|1] "" Vector__XXX
 SG_ EPAS3P_a097_rcmCntError m1 : 40|1@1+ (1,0) [0|1] "" Vector__XXX
 SG_ EPAS3P_a098_rcmCsError m1 : 41|1@1+ (1,0) [0|1] "" Vector__XXX
 SG_ EPAS3P_a099_yawRateStatus m1 : 42|1@1+ (1,0) [0|1] "" Vector__XXX
 SG_ EPAS3P_a100_diMia m1 : 43|1@1+ (1,0) [0|1] "" Vector__XXX
 SG_ EPAS3P_a101_diCntError m1 : 44|1@1+ (1,0) [0|1] "" Vector__XXX
 SG_ EPAS3P_a102_diCsError m1 : 45|1@1+ (1,0) [0|1] "" Vector__XXX
 SG_ EPAS3P_a103_vcFrontMia m1 : 46|1@1+ (1,0) [0|1] "" Vector__XXX
 SG_ EPAS3P_a104_vcFrontCntError m1 : 47|1@1+ (1,0) [0|1] "" Vector__XXX
 SG_ EPAS3P_a105_vcFrontCsError m1 : 48|1@1+ (1,0) [0|1] "" Vector__XXX
 SG_ EPAS3P_a106_vcFrontTempMia m1 : 49|1@1+ (1,0) [0|1] "" Vector__XXX
 SG_ EPAS3P_a107_uiTuneReqMia m1 : 50|1@1+ (1,0) [0|1] "" Vector__XXX
 SG_ EPAS3P_a108_uiTuneReqCntError m1 : 51|1@1+ (1,0) [0|1] "" Vector__XXX
 SG_ EPAS3P_a109_uiTuneReqCsError m1 : 52|1@1+ (1,0) [0|1] "" Vector__XXX
 SG_ EPAS3P_a110_sasMia m1 : 53|1@1+ (1,0) [0|1] "" Vector__XXX
 SG_ EPAS3P_a111_sasCntError m1 : 54|1@1+ (1,0) [0|1] "" Vector__XXX
 SG_ EPAS3P_a112_sasCsError m1 : 55|1@1+ (1,0) [0|1] "" Vector__XXX
 SG_ EPAS3P_a113_sasStatusError m1 : 56|1@1+ (1,0) [0|1] "" Vector__XXX
 SG_ EPAS3P_a114_gtwConfigMia m1 : 57|1@1+ (1,0) [0|1] "" Vector__XXX
 SG_ EPAS3P_a115_ecuStatMia m1 : 58|1@1+ (1,0) [0|1] "" Vector__XXX
 SG_ EPAS3P_a116_ecuStatCntError m1 : 59|1@1+ (1,0) [0|1] "" Vector__XXX
 SG_ EPAS3P_a117_ecuStatCrcError m1 : 60|1@1+ (1,0) [0|1] "" Vector__XXX
 SG_ EPAS3P_a118_privateBusOff m1 : 61|1@1+ (1,0) [0|1] "" Vector__XXX
 SG_ EPAS3P_a119_pvtEcuStatMia m1 : 62|1@1+ (1,0) [0|1] "" Vector__XXX
 SG_ EPAS3P_a120_pvtEcuStatCntError m1 : 63|1@1+ (1,0) [0|1] "" Vector__XXX
 SG_ EPAS3P_a121_pvtEcuStatCrcError m2 : 4|1@1+ (1,0) [0|1] "" Vector__XXX
 SG_ EPAS3P_a122_olpActive m2 : 5|1@1+ (1,0) [0|1] "" Vector__XXX
 SG_ EPAS3P_a123_combEcu2StatFail m2 : 6|1@1+ (1,0) [0|1] "" Vector__XXX
 SG_ EPAS3P_a124_tempSensStuckInRange m2 : 7|1@1+ (1,0) [0|1] "" Vector__XXX
 SG_ EPAS3P_a125_trqSensTrimOutRange m2 : 8|1@1+ (1,0) [0|1] "" Vector__XXX
 SG_ EPAS3P_a126_apsMia m2 : 9|1@1+ (1,0) [0|1] "" Vector__XXX
 SG_ EPAS3P_a127_apsCntError m2 : 10|1@1+ (1,0) [0|1] "" Vector__XXX
 SG_ EPAS3P_a128_apsCsError m2 : 11|1@1+ (1,0) [0|1] "" Vector__XXX
 SG_ EPAS3P_a129_combEcu1StatFail m2 : 12|1@1+ (1,0) [0|1] "" Vector__XXX
 SG_ EPAS3P_a130_sasOffsetNotCal m2 : 13|1@1+ (1,0) [0|1] "" Vector__XXX
 SG_ EPAS3P_a131_phaseFeedbackError m2 : 14|1@1+ (1,0) [0|1] "" Vector__XXX
 SG_ EPAS3P_a132_motFeedFwdCounter25 m2 : 15|1@1+ (1,0) [0|1] "" Vector__XXX
 SG_ EPAS3P_a133_motFeedFwdCounter50 m2 : 16|1@1+ (1,0) [0|1] "" Vector__XXX
 SG_ EPAS3P_a134_motFeedFwdCounter85 m2 : 17|1@1+ (1,0) [0|1] "" Vector__XXX
 SG_ EPAS3P_a135_piCtrlCounter25 m2 : 18|1@1+ (1,0) [0|1] "" Vector__XXX
 SG_ EPAS3P_a136_piCtrlCounter50 m2 : 19|1@1+ (1,0) [0|1] "" Vector__XXX
 SG_ EPAS3P_a137_piCtrlCounter85 m2 : 20|1@1+ (1,0) [0|1] "" Vector__XXX
 SG_ EPAS3P_a144_diSpdMia m2 : 21|1@1+ (1,0) [0|1] "" Vector__XXX
 SG_ EPAS3P_a145_diSpdCntError m2 : 22|1@1+ (1,0) [0|1] "" Vector__XXX
 SG_ EPAS3P_a146_diSpdCsError m2 : 23|1@1+ (1,0) [0|1] "" Vector__XXX
 SG_ EPAS3P_a147_backupVehSpeed m2 : 24|1@1+ (1,0) [0|1] "" Vector__XXX
 SG_ EPAS3P_a148_vMaxAssist m2 : 25|1@1+ (1,0) [0|1] "" Vector__XXX
 SG_ EPAS3P_a149_currentSensPathSwitc m2 : 26|1@1+ (1,0) [0|1] "" Vector__XXX
 SG_ EPAS3P_a150_currentSensOffsetDet m2 : 27|1@1+ (1,0) [0|1] "" Vector__XXX
 SG_ EPAS3P_a151_dcsCboot m2 : 28|1@1+ (1,0) [0|1] "" Vector__XXX
 SG_ EPAS3P_a152_dcsDiagReg m2 : 29|1@1+ (1,0) [0|1] "" Vector__XXX
 SG_ EPAS3P_a153_dcsInitOffset m2 : 30|1@1+ (1,0) [0|1] "" Vector__XXX
 SG_ EPAS3P_a154_assistTorqueDisabled m2 : 31|1@1+ (1,0) [0|1] "" Vector__XXX
 SG_ EPAS3P_a155_backupEacActive m2 : 32|1@1+ (1,0) [0|1] "" Vector__XXX
 SG_ EPAS3P_a156_angleSensorDivergenc m2 : 33|1@1+ (1,0) [0|1] "" Vector__XXX

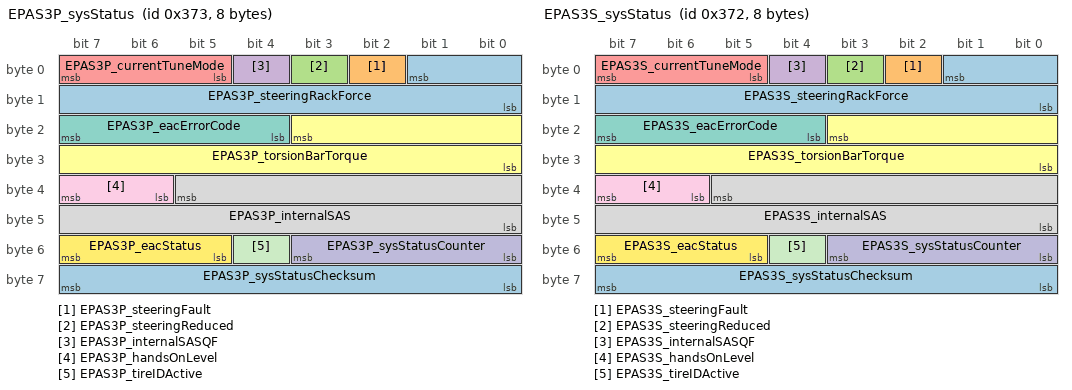
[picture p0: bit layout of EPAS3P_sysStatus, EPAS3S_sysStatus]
BO_ 883 EPAS3P_sysStatus: 8 EPAS3P
 SG_ EPAS3P_steeringRackForce : 1|10@0+ (50,-25575) [-25575|25525] "N" Vector__XXX
 SG_ EPAS3P_steeringFault : 2|1@1+ (1,0) [0|1] "" Vector__XXX
 SG_ EPAS3P_steeringReduced : 3|1@1+ (1,0) [0|1] "" Vector__XXX
 SG_ EPAS3P_internalSASQF : 4|1@1+ (1,0) [0|1] "" Vector__XXX
 SG_ EPAS3P_currentTuneMode : 5|3@1+ (1,0) [0|7] "" Vector__XXX
 SG_ EPAS3P_torsionBarTorque : 19|12@0+ (0.01,-20.5) [-20.5|20.44] "Nm" Vector__XXX
 SG_ EPAS3P_eacErrorCode : 20|4@1+ (1,0) [0|14] "" Vector__XXX
 SG_ EPAS3P_internalSAS : 37|14@0+ (0.1,-819.2) [-819.2|819] "deg" Vector__XXX
 SG_ EPAS3P_handsOnLevel : 38|2@1+ (1,0) [0|3] "" Vector__XXX
 SG_ EPAS3P_sysStatusCounter : 48|4@1+ (1,0) [0|15] "" Vector__XXX
 SG_ EPAS3P_tireIDActive : 52|1@1+ (1,0) [0|1] "" Vector__XXX
 SG_ EPAS3P_eacStatus : 53|3@1+ (1,0) [0|7] "" Vector__XXX
 SG_ EPAS3P_sysStatusChecksum : 56|8@1+ (1,0) [0|255] "" Vector__XXX

BO_ 1592 EPAS3P_udsResponseCH: 8 EPAS3P
 SG_ EPAS3P_udsResponseDataCH : 7|64@0+ (1,0) [0|1.84467440737e+19] "" Vector__XXX

BO_ 1425 EPAS3S_alertLog: 8 EPAS3S
 SG_ EPAS3S_alertID M : 0|8@1+ (1,0) [0|255] "" Vector__XXX
 SG_ EPAS3S_alertState : 15|1@1+ (1,0) [0|1] "" Vector__XXX
 SG_ EPAS3S_a147_transitionReason m147 : 16|2@1+ (1,0) [0|3] "" Vector__XXX
 SG_ EPAS3S_a148_vehicleSpeed m148 : 16|10@1+ (0.5,0) [0|511.5] "kph" Vector__XXX
 SG_ EPAS3S_a149_pcbTemp m149 : 16|8@1- (1,60) [-68|187] "degC" Vector__XXX
 SG_ EPAS3S_a150_pcbTemp m150 : 16|8@1- (1,60) [-68|187] "degC" Vector__XXX
 SG_ EPAS3S_a150_phaUMainPathCalcDiff m150 : 24|15@1+ (1,0) [0|32767] "Counts" Vector__XXX
 SG_ EPAS3S_a150_phaVMainPathCalcDiff m150 : 39|15@1+ (1,0) [0|32767] "Counts" Vector__XXX
 SG_ EPAS3S_a150_otherECUAssistStatus m150 : 54|1@1+ (1,0) [0|1] "" Vector__XXX
 SG_ EPAS3S_a151_dcsVBridge m151 : 16|6@1+ (0.328,0) [0|20.664] "Volts" Vector__XXX
 SG_ EPAS3S_a151_dcsMainChannelA m151 : 22|10@1- (0.41,0) [-209.92|209.51] "Amps" Vector__XXX
 SG_ EPAS3S_a151_dcsMainChannelB m151 : 32|10@1- (0.41,0) [-209.92|209.51] "Amps" Vector__XXX
 SG_ EPAS3S_a151_dcsOffsetA m151 : 42|10@1- (1,0) [-512|511] "Counts" Vector__XXX
 SG_ EPAS3S_a151_dcsOffsetB m151 : 52|10@1- (1,0) [-512|511] "Counts" Vector__XXX
 SG_ EPAS3S_a151_dcsCBootA m151 : 62|1@1+ (1,0) [0|1] "" Vector__XXX
 SG_ EPAS3S_a151_dcsCBootB m151 : 63|1@1+ (1,0) [0|1] "" Vector__XXX
 SG_ EPAS3S_a152_dcsVBridge m152 : 16|6@1+ (0.328,0) [0|20.664] "Volts" Vector__XXX
 SG_ EPAS3S_a152_dcsModIndex m152 : 23|7@1+ (1,0) [0|127] "Counts" Vector__XXX
 SG_ EPAS3S_a152_dcsMainPathErrReg m152 : 30|11@1+ (1,0) [0|2047] "Counts" Vector__XXX
 SG_ EPAS3S_a152_dcsTubErrReg m152 : 41|6@1+ (1,0) [0|63] "Counts" Vector__XXX
 SG_ EPAS3S_a152_dcsErrSumReg m152 : 47|10@1+ (1,0) [0|1023] "Counts" Vector__XXX
 SG_ EPAS3S_a152_dcsVbusDiagPathErrRe m152 : 57|7@1+ (1,0) [0|127] "Counts" Vector__XXX
 SG_ EPAS3S_a154_vehicleSpeed m154 : 16|10@1+ (0.5,0) [0|511.5] "kph" Vector__XXX
 SG_ EPAS3S_a155_vehicleSpeed m155 : 16|10@1+ (0.5,0) [0|511.5] "kph" Vector__XXX
 SG_ EPAS3S_a156_vehicleSpeed m156 : 16|10@1+ (0.5,0) [0|511.5] "kph" Vector__XXX

BO_ 913 EPAS3S_alertMatrix: 8 EPAS3S
 SG_ EPAS3S_matrixIndex M : 0|4@1+ (1,0) [0|15] "" Vector__XXX
 SG_ EPAS3S_a001_sent1Mia m0 : 4|1@1+ (1,0) [0|1] "" Vector__XXX
 SG_ EPAS3S_a002_sent1Error m0 : 5|1@1+ (1,0) [0|1] "" Vector__XXX
 SG_ EPAS3S_a003_trqSens1Supply m0 : 6|1@1+ (1,0) [0|1] "" Vector__XXX
 SG_ EPAS3S_a004_trqSens1Eeprom m0 : 7|1@1+ (1,0) [0|1] "" Vector__XXX
 SG_ EPAS3S_a005_sent2Mia m0 : 8|1@1+ (1,0) [0|1] "" Vector__XXX
 SG_ EPAS3S_a006_sent2Error m0 : 9|1@1+ (1,0) [0|1] "" Vector__XXX
 SG_ EPAS3S_a007_trqSens2Supply m0 : 10|1@1+ (1,0) [0|1] "" Vector__XXX
 SG_ EPAS3S_a008_trqSens2Eeprom m0 : 11|1@1+ (1,0) [0|1] "" Vector__XXX
 SG_ EPAS3S_a009_sentDiff m0 : 12|1@1+ (1,0) [0|1] "" Vector__XXX
 SG_ EPAS3S_a010_trqSensCalError m0 : 13|1@1+ (1,0) [0|1] "" Vector__XXX
 SG_ EPAS3S_a011_currentSensError m0 : 14|1@1+ (1,0) [0|1] "" Vector__XXX
 SG_ EPAS3S_a012_currentSensCalError m0 : 15|1@1+ (1,0) [0|1] "" Vector__XXX
 SG_ EPAS3S_a013_gateDriveError m0 : 16|1@1+ (1,0) [0|1] "" Vector__XXX
 SG_ EPAS3S_a014_gateDriveTxError m0 : 17|1@1+ (1,0) [0|1] "" Vector__XXX
 SG_ EPAS3S_a015_gateDriveEeprom m0 : 18|1@1+ (1,0) [0|1] "" Vector__XXX
 SG_ EPAS3S_a016_phaseUhighUv m0 : 19|1@1+ (1,0) [0|1] "" Vector__XXX
 SG_ EPAS3S_a017_phaseUlowUv m0 : 20|1@1+ (1,0) [0|1] "" Vector__XXX
 SG_ EPAS3S_a018_phaseVhighUv m0 : 21|1@1+ (1,0) [0|1] "" Vector__XXX
 SG_ EPAS3S_a019_phaseVlowUv m0 : 22|1@1+ (1,0) [0|1] "" Vector__XXX
 SG_ EPAS3S_a020_phaseWhighUv m0 : 23|1@1+ (1,0) [0|1] "" Vector__XXX
 SG_ EPAS3S_a021_phaseWlowUv m0 : 24|1@1+ (1,0) [0|1] "" Vector__XXX
 SG_ EPAS3S_a022_phaseUhighOv m0 : 25|1@1+ (1,0) [0|1] "" Vector__XXX
 SG_ EPAS3S_a023_phaseUlowOv m0 : 26|1@1+ (1,0) [0|1] "" Vector__XXX
 SG_ EPAS3S_a024_phaseVhighOv m0 : 27|1@1+ (1,0) [0|1] "" Vector__XXX
 SG_ EPAS3S_a025_phaseVlowOv m0 : 28|1@1+ (1,0) [0|1] "" Vector__XXX
 SG_ EPAS3S_a026_phaseWhighOv m0 : 29|1@1+ (1,0) [0|1] "" Vector__XXX
 SG_ EPAS3S_a027_phaseWlowOv m0 : 30|1@1+ (1,0) [0|1] "" Vector__XXX
 SG_ EPAS3S_a028_phaseUbootUv m0 : 31|1@1+ (1,0) [0|1] "" Vector__XXX
 SG_ EPAS3S_a029_phaseVbootUv m0 : 32|1@1+ (1,0) [0|1] "" Vector__XXX
 SG_ EPAS3S_a030_phaseWbootUv m0 : 33|1@1+ (1,0) [0|1] "" Vector__XXX
 SG_ EPAS3S_a031_abnormalShutdown m0 : 34|1@1+ (1,0) [0|1] "" Vector__XXX
 SG_ EPAS3S_a032_vRegOutputUv m0 : 35|1@1+ (1,0) [0|1] "" Vector__XXX
 SG_ EPAS3S_a033_vRegOutputOv m0 : 36|1@1+ (1,0) [0|1] "" Vector__XXX
 SG_ EPAS3S_a034_vRegError m0 : 37|1@1+ (1,0) [0|1] "" Vector__XXX
 SG_ EPAS3S_a035_vbbSupplyUv m0 : 38|1@1+ (1,0) [0|1] "" Vector__XXX
 SG_ EPAS3S_a036_vbbSupplyOv m0 : 39|1@1+ (1,0) [0|1] "" Vector__XXX
 SG_ EPAS3S_a037_motPos1ParityError m0 : 40|1@1+ (1,0) [0|1] "" Vector__XXX
 SG_ EPAS3S_a038_motPos1Uv m0 : 41|1@1+ (1,0) [0|1] "" Vector__XXX
 SG_ EPAS3S_a039_motPos1MagnetMia m0 : 42|1@1+ (1,0) [0|1] "" Vector__XXX
 SG_ EPAS3S_a040_motPos1LogicError m0 : 43|1@1+ (1,0) [0|1] "" Vector__XXX
 SG_ EPAS3S_a041_motPos1tempError m0 : 44|1@1+ (1,0) [0|1] "" Vector__XXX
 SG_ EPAS3S_a042_motPos2ParityError m0 : 45|1@1+ (1,0) [0|1] "" Vector__XXX
 SG_ EPAS3S_a043_motPos2Uv m0 : 46|1@1+ (1,0) [0|1] "" Vector__XXX
 SG_ EPAS3S_a044_motPos2MagnetMia m0 : 47|1@1+ (1,0) [0|1] "" Vector__XXX
 SG_ EPAS3S_a045_motPos2LogicError m0 : 48|1@1+ (1,0) [0|1] "" Vector__XXX
 SG_ EPAS3S_a046_motPos2tempError m0 : 49|1@1+ (1,0) [0|1] "" Vector__XXX
 SG_ EPAS3S_a047_motPosCorrError m0 : 50|1@1+ (1,0) [0|1] "" Vector__XXX
 SG_ EPAS3S_a048_motPosCalError m0 : 51|1@1+ (1,0) [0|1] "" Vector__XXX
 SG_ EPAS3S_a049_piCtrlError m0 : 52|1@1+ (1,0) [0|1] "" Vector__XXX
 SG_ EPAS3S_a050_mcuSmuError m0 : 53|1@1+ (1,0) [0|1] "" Vector__XXX
 SG_ EPAS3S_a051_mcuSupError m0 : 54|1@1+ (1,0) [0|1] "" Vector__XXX
 SG_ EPAS3S_a052_intWatchdogError m0 : 55|1@1+ (1,0) [0|1] "" Vector__XXX
 SG_ EPAS3S_a053_extWatchdogError m0 : 56|1@1+ (1,0) [0|1] "" Vector__XXX
 SG_ EPAS3S_a054_memoryProtectError m0 : 57|1@1+ (1,0) [0|1] "" Vector__XXX
 SG_ EPAS3S_a055_floatPointError m0 : 58|1@1+ (1,0) [0|1] "" Vector__XXX
 SG_ EPAS3S_a056_battUv m0 : 59|1@1+ (1,0) [0|1] "" Vector__XXX
 SG_ EPAS3S_a057_battUvReduced m0 : 60|1@1+ (1,0) [0|1] "" Vector__XXX
 SG_ EPAS3S_a058_battOv m0 : 61|1@1+ (1,0) [0|1] "" Vector__XXX
 SG_ EPAS3S_a059_battOvReduced m0 : 62|1@1+ (1,0) [0|1] "" Vector__XXX
 SG_ EPAS3S_a060_battBridgeDiff m0 : 63|1@1+ (1,0) [0|1] "" Vector__XXX
 SG_ EPAS3S_a061_bridgeUv m1 : 4|1@1+ (1,0) [0|1] "" Vector__XXX
 SG_ EPAS3S_a062_assistCorrError m1 : 5|1@1+ (1,0) [0|1] "" Vector__XXX
 SG_ EPAS3S_a063_dampCorrError m1 : 6|1@1+ (1,0) [0|1] "" Vector__XXX
 SG_ EPAS3S_a064_phaseCompCorrError m1 : 7|1@1+ (1,0) [0|1] "" Vector__XXX
 SG_ EPAS3S_a065_trqTarCorrError m1 : 8|1@1+ (1,0) [0|1] "" Vector__XXX
 SG_ EPAS3S_a066_returnCorrError m1 : 9|1@1+ (1,0) [0|1] "" Vector__XXX
 SG_ EPAS3S_a067_yawDampCorrError m1 : 10|1@1+ (1,0) [0|1] "" Vector__XXX
 SG_ EPAS3S_a068_hystCorrError m1 : 11|1@1+ (1,0) [0|1] "" Vector__XXX
 SG_ EPAS3S_a069_eacCorrError m1 : 12|1@1+ (1,0) [0|1] "" Vector__XXX
 SG_ EPAS3S_a070_hodCorrError m1 : 13|1@1+ (1,0) [0|1] "" Vector__XXX
 SG_ EPAS3S_a071_vehSpdCorrError m1 : 14|1@1+ (1,0) [0|1] "" Vector__XXX
 SG_ EPAS3S_a072_motFeedFwdError m1 : 15|1@1+ (1,0) [0|1] "" Vector__XXX
 SG_ EPAS3S_a073_motParEstError m1 : 16|1@1+ (1,0) [0|1] "" Vector__XXX
 SG_ EPAS3S_a074_overHeatProtect m1 : 17|1@1+ (1,0) [0|1] "" Vector__XXX
 SG_ EPAS3S_a075_fspPwrCut m1 : 18|1@1+ (1,0) [0|1] "" Vector__XXX
 SG_ EPAS3S_a076_tempSensOutofRange m1 : 19|1@1+ (1,0) [0|1] "" Vector__XXX
 SG_ EPAS3S_a077_highSideFetError m1 : 20|1@1+ (1,0) [0|1] "" Vector__XXX
 SG_ EPAS3S_a078_phaseDisconnectError m1 : 21|1@1+ (1,0) [0|1] "" Vector__XXX
 SG_ EPAS3S_a079_backupCurrentPlaus m1 : 22|1@1+ (1,0) [0|1] "" Vector__XXX
 SG_ EPAS3S_a080_ecuInitArbError m1 : 23|1@1+ (1,0) [0|1] "" Vector__XXX
 SG_ EPAS3S_a081_coggCompError m1 : 24|1@1+ (1,0) [0|1] "" Vector__XXX
 SG_ EPAS3S_a082_polarityCalError m1 : 25|1@1+ (1,0) [0|1] "" Vector__XXX
 SG_ EPAS3S_a083_crcMismatch m1 : 26|1@1+ (1,0) [0|1] "" Vector__XXX
 SG_ EPAS3S_a084_eacCancelled m1 : 27|1@1+ (1,0) [0|1] "" Vector__XXX
 SG_ EPAS3S_a085_canBusOff m1 : 28|1@1+ (1,0) [0|1] "" Vector__XXX
 SG_ EPAS3S_a086_dasMia m1 : 29|1@1+ (1,0) [0|1] "" Vector__XXX
 SG_ EPAS3S_a087_dasCntError m1 : 30|1@1+ (1,0) [0|1] "" Vector__XXX
 SG_ EPAS3S_a088_dasCsError m1 : 31|1@1+ (1,0) [0|1] "" Vector__XXX
 SG_ EPAS3S_a089_espWsMia m1 : 32|1@1+ (1,0) [0|1] "" Vector__XXX
 SG_ EPAS3S_a090_espWsCntError m1 : 33|1@1+ (1,0) [0|1] "" Vector__XXX
 SG_ EPAS3S_a091_espWsCsError m1 : 34|1@1+ (1,0) [0|1] "" Vector__XXX
 SG_ EPAS3S_a092_espWrMia m1 : 35|1@1+ (1,0) [0|1] "" Vector__XXX
 SG_ EPAS3S_a093_espWrCntError m1 : 36|1@1+ (1,0) [0|1] "" Vector__XXX
 SG_ EPAS3S_a094_espWrCsError m1 : 37|1@1+ (1,0) [0|1] "" Vector__XXX
 SG_ EPAS3S_a095_espWsStatus m1 : 38|1@1+ (1,0) [0|1] "" Vector__XXX
 SG_ EPAS3S_a096_rcmMia m1 : 39|1@1+ (1,0) [0|1] "" Vector__XXX
 SG_ EPAS3S_a097_rcmCntError m1 : 40|1@1+ (1,0) [0|1] "" Vector__XXX
 SG_ EPAS3S_a098_rcmCsError m1 : 41|1@1+ (1,0) [0|1] "" Vector__XXX
 SG_ EPAS3S_a099_yawRateStatus m1 : 42|1@1+ (1,0) [0|1] "" Vector__XXX
 SG_ EPAS3S_a100_diMia m1 : 43|1@1+ (1,0) [0|1] "" Vector__XXX
 SG_ EPAS3S_a101_diCntError m1 : 44|1@1+ (1,0) [0|1] "" Vector__XXX
 SG_ EPAS3S_a102_diCsError m1 : 45|1@1+ (1,0) [0|1] "" Vector__XXX
 SG_ EPAS3S_a103_vcFrontMia m1 : 46|1@1+ (1,0) [0|1] "" Vector__XXX
 SG_ EPAS3S_a104_vcFrontCntError m1 : 47|1@1+ (1,0) [0|1] "" Vector__XXX
 SG_ EPAS3S_a105_vcFrontCsError m1 : 48|1@1+ (1,0) [0|1] "" Vector__XXX
 SG_ EPAS3S_a106_vcFrontTempMia m1 : 49|1@1+ (1,0) [0|1] "" Vector__XXX
 SG_ EPAS3S_a107_uiTuneReqMia m1 : 50|1@1+ (1,0) [0|1] "" Vector__XXX
 SG_ EPAS3S_a108_uiTuneReqCntError m1 : 51|1@1+ (1,0) [0|1] "" Vector__XXX
 SG_ EPAS3S_a109_uiTuneReqCsError m1 : 52|1@1+ (1,0) [0|1] "" Vector__XXX
 SG_ EPAS3S_a110_sasMia m1 : 53|1@1+ (1,0) [0|1] "" Vector__XXX
 SG_ EPAS3S_a111_sasCntError m1 : 54|1@1+ (1,0) [0|1] "" Vector__XXX
 SG_ EPAS3S_a112_sasCsError m1 : 55|1@1+ (1,0) [0|1] "" Vector__XXX
 SG_ EPAS3S_a113_sasStatusError m1 : 56|1@1+ (1,0) [0|1] "" Vector__XXX
 SG_ EPAS3S_a114_gtwConfigMia m1 : 57|1@1+ (1,0) [0|1] "" Vector__XXX
 SG_ EPAS3S_a115_ecuStatMia m1 : 58|1@1+ (1,0) [0|1] "" Vector__XXX
 SG_ EPAS3S_a116_ecuStatCntError m1 : 59|1@1+ (1,0) [0|1] "" Vector__XXX
 SG_ EPAS3S_a117_ecuStatCrcError m1 : 60|1@1+ (1,0) [0|1] "" Vector__XXX
 SG_ EPAS3S_a118_privateBusOff m1 : 61|1@1+ (1,0) [0|1] "" Vector__XXX
 SG_ EPAS3S_a119_pvtEcuStatMia m1 : 62|1@1+ (1,0) [0|1] "" Vector__XXX
 SG_ EPAS3S_a120_pvtEcuStatCntError m1 : 63|1@1+ (1,0) [0|1] "" Vector__XXX
 SG_ EPAS3S_a121_pvtEcuStatCrcError m2 : 4|1@1+ (1,0) [0|1] "" Vector__XXX
 SG_ EPAS3S_a122_olpActive m2 : 5|1@1+ (1,0) [0|1] "" Vector__XXX
 SG_ EPAS3S_a123_combEcu2StatFail m2 : 6|1@1+ (1,0) [0|1] "" Vector__XXX
 SG_ EPAS3S_a124_tempSensStuckInRange m2 : 7|1@1+ (1,0) [0|1] "" Vector__XXX
 SG_ EPAS3S_a125_trqSensTrimOutRange m2 : 8|1@1+ (1,0) [0|1] "" Vector__XXX
 SG_ EPAS3S_a126_apsMia m2 : 9|1@1+ (1,0) [0|1] "" Vector__XXX
 SG_ EPAS3S_a127_apsCntError m2 : 10|1@1+ (1,0) [0|1] "" Vector__XXX
 SG_ EPAS3S_a128_apsCsError m2 : 11|1@1+ (1,0) [0|1] "" Vector__XXX
 SG_ EPAS3S_a129_combEcu1StatFail m2 : 12|1@1+ (1,0) [0|1] "" Vector__XXX
 SG_ EPAS3S_a130_sasOffsetNotCal m2 : 13|1@1+ (1,0) [0|1] "" Vector__XXX
 SG_ EPAS3S_a131_phaseFeedbackError m2 : 14|1@1+ (1,0) [0|1] "" Vector__XXX
 SG_ EPAS3S_a132_motFeedFwdCounter25 m2 : 15|1@1+ (1,0) [0|1] "" Vector__XXX
 SG_ EPAS3S_a133_motFeedFwdCounter50 m2 : 16|1@1+ (1,0) [0|1] "" Vector__XXX
 SG_ EPAS3S_a134_motFeedFwdCounter85 m2 : 17|1@1+ (1,0) [0|1] "" Vector__XXX
 SG_ EPAS3S_a135_piCtrlCounter25 m2 : 18|1@1+ (1,0) [0|1] "" Vector__XXX
 SG_ EPAS3S_a136_piCtrlCounter50 m2 : 19|1@1+ (1,0) [0|1] "" Vector__XXX
 SG_ EPAS3S_a137_piCtrlCounter85 m2 : 20|1@1+ (1,0) [0|1] "" Vector__XXX
 SG_ EPAS3S_a144_diSpdMia m2 : 21|1@1+ (1,0) [0|1] "" Vector__XXX
 SG_ EPAS3S_a145_diSpdCntError m2 : 22|1@1+ (1,0) [0|1] "" Vector__XXX
 SG_ EPAS3S_a146_diSpdCsError m2 : 23|1@1+ (1,0) [0|1] "" Vector__XXX
 SG_ EPAS3S_a147_backupVehSpeed m2 : 24|1@1+ (1,0) [0|1] "" Vector__XXX
 SG_ EPAS3S_a148_vMaxAssist m2 : 25|1@1+ (1,0) [0|1] "" Vector__XXX
 SG_ EPAS3S_a149_currentSensPathSwitc m2 : 26|1@1+ (1,0) [0|1] "" Vector__XXX
 SG_ EPAS3S_a150_currentSensOffsetDet m2 : 27|1@1+ (1,0) [0|1] "" Vector__XXX
 SG_ EPAS3S_a151_dcsCboot m2 : 28|1@1+ (1,0) [0|1] "" Vector__XXX
 SG_ EPAS3S_a152_dcsDiagReg m2 : 29|1@1+ (1,0) [0|1] "" Vector__XXX
 SG_ EPAS3S_a153_dcsInitOffset m2 : 30|1@1+ (1,0) [0|1] "" Vector__XXX
 SG_ EPAS3S_a154_assistTorqueDisabled m2 : 31|1@1+ (1,0) [0|1] "" Vector__XXX
 SG_ EPAS3S_a155_backupEacActive m2 : 32|1@1+ (1,0) [0|1] "" Vector__XXX
 SG_ EPAS3S_a156_angleSensorDivergenc m2 : 33|1@1+ (1,0) [0|1] "" Vector__XXX

BO_ 882 EPAS3S_sysStatus: 8 EPAS3S
 SG_ EPAS3S_steeringRackForce : 1|10@0+ (50,-25575) [-25575|25525] "N" Vector__XXX
 SG_ EPAS3S_steeringFault : 2|1@1+ (1,0) [0|1] "" Vector__XXX
 SG_ EPAS3S_steeringReduced : 3|1@1+ (1,0) [0|1] "" Vector__XXX
 SG_ EPAS3S_internalSASQF : 4|1@1+ (1,0) [0|1] "" Vector__XXX
 SG_ EPAS3S_currentTuneMode : 5|3@1+ (1,0) [0|7] "" Vector__XXX
 SG_ EPAS3S_torsionBarTorque : 19|12@0+ (0.01,-20.5) [-20.5|20.44] "Nm" Vector__XXX
 SG_ EPAS3S_eacErrorCode : 20|4@1+ (1,0) [0|14] "" Vector__XXX
 SG_ EPAS3S_internalSAS : 37|14@0+ (0.1,-819.2) [-819.2|819] "deg" Vector__XXX
 SG_ EPAS3S_handsOnLevel : 38|2@1+ (1,0) [0|3] "" Vector__XXX
 SG_ EPAS3S_sysStatusCounter : 48|4@1+ (1,0) [0|15] "" Vector__XXX
 SG_ EPAS3S_tireIDActive : 52|1@1+ (1,0) [0|1] "" Vector__XXX
 SG_ EPAS3S_eacStatus : 53|3@1+ (1,0) [0|7] "" Vector__XXX
 SG_ EPAS3S_sysStatusChecksum : 56|8@1+ (1,0) [0|255] "" Vector__XXX

BO_ 1848 EPAS3S_udsResponse: 8 EPAS3S
 SG_ EPAS3S_udsResponseData : 7|64@0+ (1,0) [0|1.84467440737e+19] "" Vector__XXX

BO_ 1427 EPASTP_alertLog: 8 EPASTP
 SG_ EPASTP_alertID M : 0|9@1+ (1,0) [0|511] "" Vector__XXX
 SG_ EPASTP_alertState : 15|1@1+ (1,0) [0|1] "" Vector__XXX
 SG_ EPASTP_a001_debugInfo m1 : 16|48@1+ (1,0) [0|281474976710655] "" Vector__XXX
 SG_ EPASTP_a002_debugInfo m2 : 16|48@1+ (1,0) [0|281474976710655] "" Vector__XXX
 SG_ EPASTP_a003_debugInfo m3 : 16|48@1+ (1,0) [0|281474976710655] "" Vector__XXX
 SG_ EPASTP_a004_debugInfo m4 : 16|48@1+ (1,0) [0|281474976710655] "" Vector__XXX
 SG_ EPASTP_a005_debugInfo m5 : 16|48@1+ (1,0) [0|281474976710655] "" Vector__XXX
 SG_ EPASTP_a006_debugInfo m6 : 16|48@1+ (1,0) [0|281474976710655] "" Vector__XXX
 SG_ EPASTP_a007_debugInfo m7 : 16|48@1+ (1,0) [0|281474976710655] "" Vector__XXX
 SG_ EPASTP_a009_debugInfo m9 : 16|48@1+ (1,0) [0|281474976710655] "" Vector__XXX
 SG_ EPASTP_a010_debugInfo m10 : 16|48@1+ (1,0) [0|281474976710655] "" Vector__XXX
 SG_ EPASTP_a011_debugInfo m11 : 16|48@1+ (1,0) [0|281474976710655] "" Vector__XXX
 SG_ EPASTP_a012_debugInfo m12 : 16|48@1+ (1,0) [0|281474976710655] "" Vector__XXX
 SG_ EPASTP_a013_debugInfo m13 : 16|48@1+ (1,0) [0|281474976710655] "" Vector__XXX
 SG_ EPASTP_a014_debugInfo m14 : 16|48@1+ (1,0) [0|281474976710655] "" Vector__XXX
 SG_ EPASTP_a015_debugInfo m15 : 16|48@1+ (1,0) [0|281474976710655] "" Vector__XXX
 SG_ EPASTP_a016_debugInfo m16 : 16|48@1+ (1,0) [0|281474976710655] "" Vector__XXX
 SG_ EPASTP_a017_debugInfo m17 : 16|48@1+ (1,0) [0|281474976710655] "" Vector__XXX
 SG_ EPASTP_a018_debugInfo m18 : 16|48@1+ (1,0) [0|281474976710655] "" Vector__XXX
 SG_ EPASTP_a019_debugInfo m19 : 16|48@1+ (1,0) [0|281474976710655] "" Vector__XXX
 SG_ EPASTP_a020_debugInfo m20 : 16|48@1+ (1,0) [0|281474976710655] "" Vector__XXX
 SG_ EPASTP_a021_debugInfo m21 : 16|48@1+ (1,0) [0|281474976710655] "" Vector__XXX
 SG_ EPASTP_a022_debugInfo m22 : 16|48@1+ (1,0) [0|281474976710655] "" Vector__XXX
 SG_ EPASTP_a023_debugInfo m23 : 16|48@1+ (1,0) [0|281474976710655] "" Vector__XXX
 SG_ EPASTP_a024_debugInfo m24 : 16|48@1+ (1,0) [0|281474976710655] "" Vector__XXX
 SG_ EPASTP_a025_debugInfo m25 : 16|48@1+ (1,0) [0|281474976710655] "" Vector__XXX
 SG_ EPASTP_a026_debugInfo m26 : 16|48@1+ (1,0) [0|281474976710655] "" Vector__XXX
 SG_ EPASTP_a027_debugInfo m27 : 16|48@1+ (1,0) [0|281474976710655] "" Vector__XXX
 SG_ EPASTP_a028_debugInfo m28 : 16|48@1+ (1,0) [0|281474976710655] "" Vector__XXX
 SG_ EPASTP_a029_debugInfo m29 : 16|48@1+ (1,0) [0|281474976710655] "" Vector__XXX
 SG_ EPASTP_a030_debugInfo m30 : 16|48@1+ (1,0) [0|281474976710655] "" Vector__XXX
 SG_ EPASTP_a031_debugInfo m31 : 16|48@1+ (1,0) [0|281474976710655] "" Vector__XXX
 SG_ EPASTP_a032_debugInfo m32 : 16|48@1+ (1,0) [0|281474976710655] "" Vector__XXX
 SG_ EPASTP_a033_debugInfo m33 : 16|48@1+ (1,0) [0|281474976710655] "" Vector__XXX
 SG_ EPASTP_a034_debugInfo m34 : 16|48@1+ (1,0) [0|281474976710655] "" Vector__XXX
 SG_ EPASTP_a035_debugInfo m35 : 16|48@1+ (1,0) [0|281474976710655] "" Vector__XXX
 SG_ EPASTP_a036_debugInfo m36 : 16|48@1+ (1,0) [0|281474976710655] "" Vector__XXX
 SG_ EPASTP_a037_debugInfo m37 : 16|48@1+ (1,0) [0|281474976710655] "" Vector__XXX
 SG_ EPASTP_a038_debugInfo m38 : 16|48@1+ (1,0) [0|281474976710655] "" Vector__XXX
 SG_ EPASTP_a039_debugInfo m39 : 16|48@1+ (1,0) [0|281474976710655] "" Vector__XXX
 SG_ EPASTP_a040_debugInfo m40 : 16|48@1+ (1,0) [0|281474976710655] "" Vector__XXX
 SG_ EPASTP_a041_debugInfo m41 : 16|48@1+ (1,0) [0|281474976710655] "" Vector__XXX
 SG_ EPASTP_a042_debugInfo m42 : 16|48@1+ (1,0) [0|281474976710655] "" Vector__XXX
 SG_ EPASTP_a043_debugInfo m43 : 16|48@1+ (1,0) [0|281474976710655] "" Vector__XXX
 SG_ EPASTP_a044_debugInfo m44 : 16|48@1+ (1,0) [0|281474976710655] "" Vector__XXX
 SG_ EPASTP_a045_debugInfo m45 : 16|48@1+ (1,0) [0|281474976710655] "" Vector__XXX
 SG_ EPASTP_a046_debugInfo m46 : 16|48@1+ (1,0) [0|281474976710655] "" Vector__XXX
 SG_ EPASTP_a047_debugInfo m47 : 16|48@1+ (1,0) [0|281474976710655] "" Vector__XXX
 SG_ EPASTP_a048_debugInfo m48 : 16|48@1+ (1,0) [0|281474976710655] "" Vector__XXX
 SG_ EPASTP_a049_debugInfo m49 : 16|48@1+ (1,0) [0|281474976710655] "" Vector__XXX
 SG_ EPASTP_a050_debugInfo m50 : 16|48@1+ (1,0) [0|281474976710655] "" Vector__XXX
 SG_ EPASTP_a051_debugInfo m51 : 16|48@1+ (1,0) [0|281474976710655] "" Vector__XXX
 SG_ EPASTP_a052_debugInfo m52 : 16|48@1+ (1,0) [0|281474976710655] "" Vector__XXX
 SG_ EPASTP_a053_debugInfo m53 : 16|48@1+ (1,0) [0|281474976710655] "" Vector__XXX
 SG_ EPASTP_a054_debugInfo m54 : 16|48@1+ (1,0) [0|281474976710655] "" Vector__XXX
 SG_ EPASTP_a055_debugInfo m55 : 16|48@1+ (1,0) [0|281474976710655] "" Vector__XXX
 SG_ EPASTP_a056_debugInfo m56 : 16|48@1+ (1,0) [0|281474976710655] "" Vector__XXX
 SG_ EPASTP_a057_debugInfo m57 : 16|48@1+ (1,0) [0|281474976710655] "" Vector__XXX
 SG_ EPASTP_a058_debugInfo m58 : 16|48@1+ (1,0) [0|281474976710655] "" Vector__XXX
 SG_ EPASTP_a059_debugInfo m59 : 16|48@1+ (1,0) [0|281474976710655] "" Vector__XXX
 SG_ EPASTP_a060_debugInfo m60 : 16|48@1+ (1,0) [0|281474976710655] "" Vector__XXX
 SG_ EPASTP_a061_debugInfo m61 : 16|48@1+ (1,0) [0|281474976710655] "" Vector__XXX
 SG_ EPASTP_a062_debugInfo m62 : 16|48@1+ (1,0) [0|281474976710655] "" Vector__XXX
 SG_ EPASTP_a063_debugInfo m63 : 16|48@1+ (1,0) [0|281474976710655] "" Vector__XXX
 SG_ EPASTP_a064_debugInfo m64 : 16|48@1+ (1,0) [0|281474976710655] "" Vector__XXX
 SG_ EPASTP_a065_debugInfo m65 : 16|48@1+ (1,0) [0|281474976710655] "" Vector__XXX
 SG_ EPASTP_a066_debugInfo m66 : 16|48@1+ (1,0) [0|281474976710655] "" Vector__XXX
 SG_ EPASTP_a067_debugInfo m67 : 16|48@1+ (1,0) [0|281474976710655] "" Vector__XXX
 SG_ EPASTP_a068_debugInfo m68 : 16|48@1+ (1,0) [0|281474976710655] "" Vector__XXX
 SG_ EPASTP_a069_debugInfo m69 : 16|48@1+ (1,0) [0|281474976710655] "" Vector__XXX
 SG_ EPASTP_a070_debugInfo m70 : 16|48@1+ (1,0) [0|281474976710655] "" Vector__XXX
 SG_ EPASTP_a071_debugInfo m71 : 16|48@1+ (1,0) [0|281474976710655] "" Vector__XXX
 SG_ EPASTP_a072_debugInfo m72 : 16|48@1+ (1,0) [0|281474976710655] "" Vector__XXX
 SG_ EPASTP_a073_debugInfo m73 : 16|48@1+ (1,0) [0|281474976710655] "" Vector__XXX
 SG_ EPASTP_a074_debugInfo m74 : 16|48@1+ (1,0) [0|281474976710655] "" Vector__XXX
 SG_ EPASTP_a075_debugInfo m75 : 16|48@1+ (1,0) [0|281474976710655] "" Vector__XXX
 SG_ EPASTP_a076_debugInfo m76 : 16|48@1+ (1,0) [0|281474976710655] "" Vector__XXX
 SG_ EPASTP_a077_debugInfo m77 : 16|48@1+ (1,0) [0|281474976710655] "" Vector__XXX
 SG_ EPASTP_a078_debugInfo m78 : 16|48@1+ (1,0) [0|281474976710655] "" Vector__XXX
 SG_ EPASTP_a079_debugInfo m79 : 16|48@1+ (1,0) [0|281474976710655] "" Vector__XXX
 SG_ EPASTP_a080_debugInfo m80 : 16|48@1+ (1,0) [0|281474976710655] "" Vector__XXX
 SG_ EPASTP_a081_debugInfo m81 : 16|48@1+ (1,0) [0|281474976710655] "" Vector__XXX
 SG_ EPASTP_a082_debugInfo m82 : 16|48@1+ (1,0) [0|281474976710655] "" Vector__XXX
 SG_ EPASTP_a083_debugInfo m83 : 16|48@1+ (1,0) [0|281474976710655] "" Vector__XXX
 SG_ EPASTP_a084_debugInfo m84 : 16|48@1+ (1,0) [0|281474976710655] "" Vector__XXX
 SG_ EPASTP_a085_debugInfo m85 : 16|48@1+ (1,0) [0|281474976710655] "" Vector__XXX
 SG_ EPASTP_a086_debugInfo m86 : 16|48@1+ (1,0) [0|281474976710655] "" Vector__XXX
 SG_ EPASTP_a087_debugInfo m87 : 16|48@1+ (1,0) [0|281474976710655] "" Vector__XXX
 SG_ EPASTP_a088_debugInfo m88 : 16|48@1+ (1,0) [0|281474976710655] "" Vector__XXX
 SG_ EPASTP_a089_debugInfo m89 : 16|48@1+ (1,0) [0|281474976710655] "" Vector__XXX
 SG_ EPASTP_a090_debugInfo m90 : 16|48@1+ (1,0) [0|281474976710655] "" Vector__XXX
 SG_ EPASTP_a091_debugInfo m91 : 16|48@1+ (1,0) [0|281474976710655] "" Vector__XXX
 SG_ EPASTP_a092_debugInfo m92 : 16|48@1+ (1,0) [0|281474976710655] "" Vector__XXX
 SG_ EPASTP_a093_debugInfo m93 : 16|48@1+ (1,0) [0|281474976710655] "" Vector__XXX
 SG_ EPASTP_a094_debugInfo m94 : 16|48@1+ (1,0) [0|281474976710655] "" Vector__XXX
 SG_ EPASTP_a095_debugInfo m95 : 16|48@1+ (1,0) [0|281474976710655] "" Vector__XXX
 SG_ EPASTP_a096_debugInfo m96 : 16|48@1+ (1,0) [0|281474976710655] "" Vector__XXX
 SG_ EPASTP_a097_debugInfo m97 : 16|48@1+ (1,0) [0|281474976710655] "" Vector__XXX
 SG_ EPASTP_a098_debugInfo m98 : 16|48@1+ (1,0) [0|281474976710655] "" Vector__XXX
 SG_ EPASTP_a099_debugInfo m99 : 16|48@1+ (1,0) [0|281474976710655] "" Vector__XXX
 SG_ EPASTP_a100_debugInfo m100 : 16|48@1+ (1,0) [0|281474976710655] "" Vector__XXX
 SG_ EPASTP_a101_debugInfo m101 : 16|48@1+ (1,0) [0|281474976710655] "" Vector__XXX
 SG_ EPASTP_a102_debugInfo m102 : 16|48@1+ (1,0) [0|281474976710655] "" Vector__XXX
 SG_ EPASTP_a103_debugInfo m103 : 16|48@1+ (1,0) [0|281474976710655] "" Vector__XXX
 SG_ EPASTP_a104_debugInfo m104 : 16|48@1+ (1,0) [0|281474976710655] "" Vector__XXX
 SG_ EPASTP_a105_debugInfo m105 : 16|48@1+ (1,0) [0|281474976710655] "" Vector__XXX
 SG_ EPASTP_a106_debugInfo m106 : 16|48@1+ (1,0) [0|281474976710655] "" Vector__XXX
 SG_ EPASTP_a107_debugInfo m107 : 16|48@1+ (1,0) [0|281474976710655] "" Vector__XXX
 SG_ EPASTP_a108_debugInfo m108 : 16|48@1+ (1,0) [0|281474976710655] "" Vector__XXX
 SG_ EPASTP_a109_debugInfo m109 : 16|48@1+ (1,0) [0|281474976710655] "" Vector__XXX
 SG_ EPASTP_a110_debugInfo m110 : 16|48@1+ (1,0) [0|281474976710655] "" Vector__XXX
 SG_ EPASTP_a111_debugInfo m111 : 16|48@1+ (1,0) [0|281474976710655] "" Vector__XXX
 SG_ EPASTP_a112_debugInfo m112 : 16|48@1+ (1,0) [0|281474976710655] "" Vector__XXX
 SG_ EPASTP_a113_debugInfo m113 : 16|48@1+ (1,0) [0|281474976710655] "" Vector__XXX
 SG_ EPASTP_a114_debugInfo m114 : 16|48@1+ (1,0) [0|281474976710655] "" Vector__XXX
 SG_ EPASTP_a115_debugInfo m115 : 16|48@1+ (1,0) [0|281474976710655] "" Vector__XXX
 SG_ EPASTP_a116_debugInfo m116 : 16|48@1+ (1,0) [0|281474976710655] "" Vector__XXX
 SG_ EPASTP_a117_debugInfo m117 : 16|48@1+ (1,0) [0|281474976710655] "" Vector__XXX
 SG_ EPASTP_a118_debugInfo m118 : 16|48@1+ (1,0) [0|281474976710655] "" Vector__XXX
 SG_ EPASTP_a119_debugInfo m119 : 16|48@1+ (1,0) [0|281474976710655] "" Vector__XXX
 SG_ EPASTP_a120_debugInfo m120 : 16|48@1+ (1,0) [0|281474976710655] "" Vector__XXX
 SG_ EPASTP_a121_debugInfo m121 : 16|48@1+ (1,0) [0|281474976710655] "" Vector__XXX
 SG_ EPASTP_a122_debugInfo m122 : 16|48@1+ (1,0) [0|281474976710655] "" Vector__XXX
 SG_ EPASTP_a123_debugInfo m123 : 16|48@1+ (1,0) [0|281474976710655] "" Vector__XXX
 SG_ EPASTP_a124_debugInfo m124 : 16|48@1+ (1,0) [0|281474976710655] "" Vector__XXX
 SG_ EPASTP_a125_debugInfo m125 : 16|48@1+ (1,0) [0|281474976710655] "" Vector__XXX
 SG_ EPASTP_a126_debugInfo m126 : 16|48@1+ (1,0) [0|281474976710655] "" Vector__XXX
 SG_ EPASTP_a127_debugInfo m127 : 16|48@1+ (1,0) [0|281474976710655] "" Vector__XXX
 SG_ EPASTP_a128_debugInfo m128 : 16|48@1+ (1,0) [0|281474976710655] "" Vector__XXX
 SG_ EPASTP_a129_debugInfo m129 : 16|48@1+ (1,0) [0|281474976710655] "" Vector__XXX
 SG_ EPASTP_a130_debugInfo m130 : 16|48@1+ (1,0) [0|281474976710655] "" Vector__XXX
 SG_ EPASTP_a131_debugInfo m131 : 16|48@1+ (1,0) [0|281474976710655] "" Vector__XXX
 SG_ EPASTP_a132_debugInfo m132 : 16|48@1+ (1,0) [0|281474976710655] "" Vector__XXX
 SG_ EPASTP_a133_debugInfo m133 : 16|48@1+ (1,0) [0|281474976710655] "" Vector__XXX
 SG_ EPASTP_a134_debugInfo m134 : 16|48@1+ (1,0) [0|281474976710655] "" Vector__XXX
 SG_ EPASTP_a135_debugInfo m135 : 16|48@1+ (1,0) [0|281474976710655] "" Vector__XXX
 SG_ EPASTP_a136_debugInfo m136 : 16|48@1+ (1,0) [0|281474976710655] "" Vector__XXX
 SG_ EPASTP_a137_debugInfo m137 : 16|48@1+ (1,0) [0|281474976710655] "" Vector__XXX
 SG_ EPASTP_a138_debugInfo m138 : 16|48@1+ (1,0) [0|281474976710655] "" Vector__XXX
 SG_ EPASTP_a139_debugInfo m139 : 16|48@1+ (1,0) [0|281474976710655] "" Vector__XXX
 SG_ EPASTP_a140_debugInfo m140 : 16|48@1+ (1,0) [0|281474976710655] "" Vector__XXX
 SG_ EPASTP_a141_debugInfo m141 : 16|48@1+ (1,0) [0|281474976710655] "" Vector__XXX
 SG_ EPASTP_a142_debugInfo m142 : 16|48@1+ (1,0) [0|281474976710655] "" Vector__XXX
 SG_ EPASTP_a143_debugInfo m143 : 16|48@1+ (1,0) [0|281474976710655] "" Vector__XXX
 SG_ EPASTP_a144_debugInfo m144 : 16|48@1+ (1,0) [0|281474976710655] "" Vector__XXX
 SG_ EPASTP_a145_debugInfo m145 : 16|48@1+ (1,0) [0|281474976710655] "" Vector__XXX
 SG_ EPASTP_a146_debugInfo m146 : 16|48@1+ (1,0) [0|281474976710655] "" Vector__XXX
 SG_ EPASTP_a147_debugInfo m147 : 16|48@1+ (1,0) [0|281474976710655] "" Vector__XXX
 SG_ EPASTP_a148_debugInfo m148 : 16|48@1+ (1,0) [0|281474976710655] "" Vector__XXX
 SG_ EPASTP_a149_debugInfo m149 : 16|48@1+ (1,0) [0|281474976710655] "" Vector__XXX
 SG_ EPASTP_a150_debugInfo m150 : 16|48@1+ (1,0) [0|281474976710655] "" Vector__XXX
 SG_ EPASTP_a152_debugInfo m152 : 16|48@1+ (1,0) [0|281474976710655] "" Vector__XXX
 SG_ EPASTP_a153_debugInfo m153 : 16|48@1+ (1,0) [0|281474976710655] "" Vector__XXX
 SG_ EPASTP_a154_debugInfo m154 : 16|48@1+ (1,0) [0|281474976710655] "" Vector__XXX
 SG_ EPASTP_a155_debugInfo m155 : 16|48@1+ (1,0) [0|281474976710655] "" Vector__XXX
 SG_ EPASTP_a156_debugInfo m156 : 16|48@1+ (1,0) [0|281474976710655] "" Vector__XXX
 SG_ EPASTP_a157_debugInfo m157 : 16|48@1+ (1,0) [0|281474976710655] "" Vector__XXX
 SG_ EPASTP_a158_debugInfo m158 : 16|48@1+ (1,0) [0|281474976710655] "" Vector__XXX
 SG_ EPASTP_a159_debugInfo m159 : 16|48@1+ (1,0) [0|281474976710655] "" Vector__XXX
 SG_ EPASTP_a160_debugInfo m160 : 16|48@1+ (1,0) [0|281474976710655] "" Vector__XXX
 SG_ EPASTP_a161_debugInfo m161 : 16|48@1+ (1,0) [0|281474976710655] "" Vector__XXX
 SG_ EPASTP_a162_debugInfo m162 : 16|48@1+ (1,0) [0|281474976710655] "" Vector__XXX
 SG_ EPASTP_a163_debugInfo m163 : 16|48@1+ (1,0) [0|281474976710655] "" Vector__XXX
 SG_ EPASTP_a164_debugInfo m164 : 16|48@1+ (1,0) [0|281474976710655] "" Vector__XXX
 SG_ EPASTP_a165_debugInfo m165 : 16|48@1+ (1,0) [0|281474976710655] "" Vector__XXX
 SG_ EPASTP_a166_debugInfo m166 : 16|48@1+ (1,0) [0|281474976710655] "" Vector__XXX
 SG_ EPASTP_a167_debugInfo m167 : 16|48@1+ (1,0) [0|281474976710655] "" Vector__XXX
 SG_ EPASTP_a168_debugInfo m168 : 16|48@1+ (1,0) [0|281474976710655] "" Vector__XXX
 SG_ EPASTP_a169_debugInfo m169 : 16|48@1+ (1,0) [0|281474976710655] "" Vector__XXX
 SG_ EPASTP_a170_debugInfo m170 : 16|48@1+ (1,0) [0|281474976710655] "" Vector__XXX
 SG_ EPASTP_a171_debugInfo m171 : 16|48@1+ (1,0) [0|281474976710655] "" Vector__XXX
 SG_ EPASTP_a172_debugInfo m172 : 16|48@1+ (1,0) [0|281474976710655] "" Vector__XXX
 SG_ EPASTP_a173_debugInfo m173 : 16|48@1+ (1,0) [0|281474976710655] "" Vector__XXX
 SG_ EPASTP_a174_debugInfo m174 : 16|48@1+ (1,0) [0|281474976710655] "" Vector__XXX
 SG_ EPASTP_a175_debugInfo m175 : 16|48@1+ (1,0) [0|281474976710655] "" Vector__XXX
 SG_ EPASTP_a176_debugInfo m176 : 16|48@1+ (1,0) [0|281474976710655] "" Vector__XXX
 SG_ EPASTP_a177_debugInfo m177 : 16|48@1+ (1,0) [0|281474976710655] "" Vector__XXX
 SG_ EPASTP_a178_debugInfo m178 : 16|48@1+ (1,0) [0|281474976710655] "" Vector__XXX
 SG_ EPASTP_a179_debugInfo m179 : 16|48@1+ (1,0) [0|281474976710655] "" Vector__XXX
 SG_ EPASTP_a180_debugInfo m180 : 16|48@1+ (1,0) [0|281474976710655] "" Vector__XXX
 SG_ EPASTP_a181_debugInfo m181 : 16|48@1+ (1,0) [0|281474976710655] "" Vector__XXX
 SG_ EPASTP_a182_debugInfo m182 : 16|48@1+ (1,0) [0|281474976710655] "" Vector__XXX
 SG_ EPASTP_a183_debugInfo m183 : 16|48@1+ (1,0) [0|281474976710655] "" Vector__XXX
 SG_ EPASTP_a184_debugInfo m184 : 16|48@1+ (1,0) [0|281474976710655] "" Vector__XXX
 SG_ EPASTP_a185_debugInfo m185 : 16|48@1+ (1,0) [0|281474976710655] "" Vector__XXX
 SG_ EPASTP_a186_debugInfo m186 : 16|48@1+ (1,0) [0|281474976710655] "" Vector__XXX
 SG_ EPASTP_a188_debugInfo m188 : 16|48@1+ (1,0) [0|281474976710655] "" Vector__XXX
 SG_ EPASTP_a189_debugInfo m189 : 16|48@1+ (1,0) [0|281474976710655] "" Vector__XXX
 SG_ EPASTP_a190_debugInfo m190 : 16|48@1+ (1,0) [0|281474976710655] "" Vector__XXX
 SG_ EPASTP_a191_debugInfo m191 : 16|48@1+ (1,0) [0|281474976710655] "" Vector__XXX
 SG_ EPASTP_a192_debugInfo m192 : 16|48@1+ (1,0) [0|281474976710655] "" Vector__XXX
 SG_ EPASTP_a193_debugInfo m193 : 16|48@1+ (1,0) [0|281474976710655] "" Vector__XXX
 SG_ EPASTP_a194_debugInfo m194 : 16|48@1+ (1,0) [0|281474976710655] "" Vector__XXX
 SG_ EPASTP_a195_debugInfo m195 : 16|48@1+ (1,0) [0|281474976710655] "" Vector__XXX
 SG_ EPASTP_a196_debugInfo m196 : 16|48@1+ (1,0) [0|281474976710655] "" Vector__XXX
 SG_ EPASTP_a197_debugInfo m197 : 16|48@1+ (1,0) [0|281474976710655] "" Vector__XXX
 SG_ EPASTP_a198_debugInfo m198 : 16|48@1+ (1,0) [0|281474976710655] "" Vector__XXX
 SG_ EPASTP_a199_debugInfo m199 : 16|48@1+ (1,0) [0|281474976710655] "" Vector__XXX
 SG_ EPASTP_a200_debugInfo m200 : 16|48@1+ (1,0) [0|281474976710655] "" Vector__XXX
 SG_ EPASTP_a201_debugInfo m201 : 16|48@1+ (1,0) [0|281474976710655] "" Vector__XXX
 SG_ EPASTP_a202_debugInfo m202 : 16|48@1+ (1,0) [0|281474976710655] "" Vector__XXX
 SG_ EPASTP_a203_debugInfo m203 : 16|48@1+ (1,0) [0|281474976710655] "" Vector__XXX
 SG_ EPASTP_a204_debugInfo m204 : 16|48@1+ (1,0) [0|281474976710655] "" Vector__XXX
 SG_ EPASTP_a205_debugInfo m205 : 16|48@1+ (1,0) [0|281474976710655] "" Vector__XXX
 SG_ EPASTP_a206_debugInfo m206 : 16|48@1+ (1,0) [0|281474976710655] "" Vector__XXX
 SG_ EPASTP_a207_debugInfo m207 : 16|48@1+ (1,0) [0|281474976710655] "" Vector__XXX
 SG_ EPASTP_a208_debugInfo m208 : 16|48@1+ (1,0) [0|281474976710655] "" Vector__XXX
 SG_ EPASTP_a209_debugInfo m209 : 16|48@1+ (1,0) [0|281474976710655] "" Vector__XXX
 SG_ EPASTP_a210_debugInfo m210 : 16|48@1+ (1,0) [0|281474976710655] "" Vector__XXX
 SG_ EPASTP_a211_debugInfo m211 : 16|48@1+ (1,0) [0|281474976710655] "" Vector__XXX
 SG_ EPASTP_a212_debugInfo m212 : 16|48@1+ (1,0) [0|281474976710655] "" Vector__XXX
 SG_ EPASTP_a213_debugInfo m213 : 16|48@1+ (1,0) [0|281474976710655] "" Vector__XXX
 SG_ EPASTP_a214_debugInfo m214 : 16|48@1+ (1,0) [0|281474976710655] "" Vector__XXX
 SG_ EPASTP_a215_debugInfo m215 : 16|48@1+ (1,0) [0|281474976710655] "" Vector__XXX
 SG_ EPASTP_a216_debugInfo m216 : 16|48@1+ (1,0) [0|281474976710655] "" Vector__XXX
 SG_ EPASTP_a217_debugInfo m217 : 16|48@1+ (1,0) [0|281474976710655] "" Vector__XXX
 SG_ EPASTP_a218_debugInfo m218 : 16|48@1+ (1,0) [0|281474976710655] "" Vector__XXX
 SG_ EPASTP_a219_debugInfo m219 : 16|48@1+ (1,0) [0|281474976710655] "" Vector__XXX
 SG_ EPASTP_a221_debugInfo m221 : 16|48@1+ (1,0) [0|281474976710655] "" Vector__XXX
 SG_ EPASTP_a222_debugInfo m222 : 16|48@1+ (1,0) [0|281474976710655] "" Vector__XXX
 SG_ EPASTP_a223_debugInfo m223 : 16|48@1+ (1,0) [0|281474976710655] "" Vector__XXX
 SG_ EPASTP_a224_debugInfo m224 : 16|48@1+ (1,0) [0|281474976710655] "" Vector__XXX
 SG_ EPASTP_a225_debugInfo m225 : 16|48@1+ (1,0) [0|281474976710655] "" Vector__XXX
 SG_ EPASTP_a226_debugInfo m226 : 16|48@1+ (1,0) [0|281474976710655] "" Vector__XXX
 SG_ EPASTP_a227_debugInfo m227 : 16|48@1+ (1,0) [0|281474976710655] "" Vector__XXX
 SG_ EPASTP_a228_debugInfo m228 : 16|48@1+ (1,0) [0|281474976710655] "" Vector__XXX
 SG_ EPASTP_a229_debugInfo m229 : 16|48@1+ (1,0) [0|281474976710655] "" Vector__XXX
 SG_ EPASTP_a230_debugInfo m230 : 16|48@1+ (1,0) [0|281474976710655] "" Vector__XXX
 SG_ EPASTP_a231_debugInfo m231 : 16|48@1+ (1,0) [0|281474976710655] "" Vector__XXX
 SG_ EPASTP_a232_debugInfo m232 : 16|48@1+ (1,0) [0|281474976710655] "" Vector__XXX
 SG_ EPASTP_a233_debugInfo m233 : 16|48@1+ (1,0) [0|281474976710655] "" Vector__XXX
 SG_ EPASTP_a234_debugInfo m234 : 16|48@1+ (1,0) [0|281474976710655] "" Vector__XXX
 SG_ EPASTP_a235_debugInfo m235 : 16|48@1+ (1,0) [0|281474976710655] "" Vector__XXX
 SG_ EPASTP_a236_debugInfo m236 : 16|48@1+ (1,0) [0|281474976710655] "" Vector__XXX
 SG_ EPASTP_a237_debugInfo m237 : 16|48@1+ (1,0) [0|281474976710655] "" Vector__XXX
 SG_ EPASTP_a238_debugInfo m238 : 16|48@1+ (1,0) [0|281474976710655] "" Vector__XXX
 SG_ EPASTP_a239_debugInfo m239 : 16|48@1+ (1,0) [0|281474976710655] "" Vector__XXX
 SG_ EPASTP_a240_debugInfo m240 : 16|48@1+ (1,0) [0|281474976710655] "" Vector__XXX
 SG_ EPASTP_a241_debugInfo m241 : 16|48@1+ (1,0) [0|281474976710655] "" Vector__XXX
 SG_ EPASTP_a242_debugInfo m242 : 16|48@1+ (1,0) [0|281474976710655] "" Vector__XXX
 SG_ EPASTP_a243_debugInfo m243 : 16|48@1+ (1,0) [0|281474976710655] "" Vector__XXX
 SG_ EPASTP_a244_debugInfo m244 : 16|48@1+ (1,0) [0|281474976710655] "" Vector__XXX
 SG_ EPASTP_a245_debugInfo m245 : 16|48@1+ (1,0) [0|281474976710655] "" Vector__XXX
 SG_ EPASTP_a246_debugInfo m246 : 16|48@1+ (1,0) [0|281474976710655] "" Vector__XXX
 SG_ EPASTP_a247_debugInfo m247 : 16|48@1+ (1,0) [0|281474976710655] "" Vector__XXX
 SG_ EPASTP_a248_debugInfo m248 : 16|48@1+ (1,0) [0|281474976710655] "" Vector__XXX
 SG_ EPASTP_a249_debugInfo m249 : 16|48@1+ (1,0) [0|281474976710655] "" Vector__XXX
 SG_ EPASTP_a250_debugInfo m250 : 16|48@1+ (1,0) [0|281474976710655] "" Vector__XXX
 SG_ EPASTP_a251_debugInfo m251 : 16|48@1+ (1,0) [0|281474976710655] "" Vector__XXX
 SG_ EPASTP_a252_debugInfo m252 : 16|48@1+ (1,0) [0|281474976710655] "" Vector__XXX
 SG_ EPASTP_a253_debugInfo m253 : 16|48@1+ (1,0) [0|281474976710655] "" Vector__XXX
 SG_ EPASTP_a254_debugInfo m254 : 16|48@1+ (1,0) [0|281474976710655] "" Vector__XXX
 SG_ EPASTP_a255_debugInfo m255 : 16|48@1+ (1,0) [0|281474976710655] "" Vector__XXX
 SG_ EPASTP_a256_debugInfo m256 : 16|48@1+ (1,0) [0|281474976710655] "" Vector__XXX
 SG_ EPASTP_a257_debugInfo m257 : 16|48@1+ (1,0) [0|281474976710655] "" Vector__XXX
 SG_ EPASTP_a258_debugInfo m258 : 16|48@1+ (1,0) [0|281474976710655] "" Vector__XXX
 SG_ EPASTP_a259_debugInfo m259 : 16|48@1+ (1,0) [0|281474976710655] "" Vector__XXX
 SG_ EPASTP_a260_debugInfo m260 : 16|48@1+ (1,0) [0|281474976710655] "" Vector__XXX
 SG_ EPASTP_a261_debugInfo m261 : 16|48@1+ (1,0) [0|281474976710655] "" Vector__XXX
 SG_ EPASTP_a262_debugInfo m262 : 16|48@1+ (1,0) [0|281474976710655] "" Vector__XXX
 SG_ EPASTP_a263_debugInfo m263 : 16|48@1+ (1,0) [0|281474976710655] "" Vector__XXX
 SG_ EPASTP_a264_degradedECU m264 : 16|8@1+ (1,0) [0|255] "" Vector__XXX
 SG_ EPASTP_a264_vehicleSpeed m264 : 24|16@1+ (0.1,0) [0|6553.5] "kph" Vector__XXX
 SG_ EPASTP_a264_powerRatio m264 : 40|8@1+ (1,0) [0|255] "percent" Vector__XXX
 SG_ EPASTP_a264_ownSideDegradationRe m264 : 48|8@1+ (1,0) [0|255] "" Vector__XXX
 SG_ EPASTP_a264_otherSideDegradation m264 : 56|8@1+ (1,0) [0|255] "" Vector__XXX
 SG_ EPASTP_a265_degradedECU m265 : 16|8@1+ (1,0) [0|255] "" Vector__XXX
 SG_ EPASTP_a265_vehicleSpeed m265 : 24|16@1+ (0.1,0) [0|6553.5] "kph" Vector__XXX
 SG_ EPASTP_a265_rawMcuTemperature m265 : 40|16@1+ (1,-100) [-100|65435] "C" Vector__XXX
 SG_ EPASTP_a265_degradedCurrentLimit m265 : 56|8@1+ (1,0) [0|255] "A" Vector__XXX
 SG_ EPASTP_a266_cdpAssistFactor m266 : 16|8@1+ (1,0) [0|255] "percent" Vector__XXX
 SG_ EPASTP_a266_vehicleSpeed m266 : 24|16@1+ (0.1,0) [0|6553.5] "kph" Vector__XXX
 SG_ EPASTP_a267_vehicleSpeed m267 : 16|16@1+ (0.1,0) [0|6553.5] "kph" Vector__XXX
 SG_ EPASTP_a267_velocityEstimatorSta m267 : 32|8@1+ (1,0) [0|255] "" Vector__XXX
 SG_ EPASTP_a269_vehicleSpeed m269 : 16|16@1+ (0.1,0) [0|6553.5] "kph" Vector__XXX
 SG_ EPASTP_a270_debugInfo m270 : 16|48@1+ (1,0) [0|281474976710655] "" Vector__XXX

BO_TX_BU_ 999 : DPB;
BO_TX_BU_ 1426 : EPAS3P;
BO_TX_BU_ 2036 : EPAS3P;
BO_TX_BU_ 883 : EPAS3P;
BO_TX_BU_ 1592 : EPAS3P;
BO_TX_BU_ 1425 : EPAS3S;
BO_TX_BU_ 913 : EPAS3S;
BO_TX_BU_ 882 : EPAS3S;
BO_TX_BU_ 1848 : EPAS3S;
BO_TX_BU_ 1427 : EPASTP;
CM_ BO_ 999 "DPB ECU message: alert matrix";
CM_ SG_ 999 DPB_matrixIndex "DPB ECU: matrix index";
CM_ SG_ 999 DPB_a001_pPlungerSensorOffsetHig "DPB ECU: a001 p plunger sensor offset high";
CM_ SG_ 999 DPB_a002_pMC2SensorOffsetHigh "DPB ECU: a002 p MC2 sensor offset high";
CM_ SG_ 999 DPB_a003_AswEEPROMReadFailure "DPB ECU: a003 asw EEPROM read failure";
CM_ SG_ 999 DPB_a004_assertionFault "DPB ECU: a004 assertion fault";
CM_ SG_ 999 DPB_a005_hardPedalChar "DPB ECU: a005 hard pedal char";
CM_ SG_ 999 DPB_a006_hardPedalCharGoodCheck "DPB ECU: a006 hard pedal char good check";
CM_ SG_ 999 DPB_a007_PMCLeakageDetected "DPB ECU: a007 PMC leakage detected";
CM_ SG_ 999 DPB_a008_LiPSPts1Offset "DPB ECU: a008 li PS pts1 offset";
CM_ SG_ 999 DPB_a009_LiPSPts2Offset "DPB ECU: a009 li PS pts2 offset";
CM_ SG_ 999 DPB_a010_LiPSPtsConsistency "DPB ECU: a010 li PS pts consistency";
CM_ SG_ 999 DPB_a011_PtsNonZeroStage1 "DPB ECU: a011 pts non zero stage1";
CM_ SG_ 999 DPB_a012_PtsNonZeroStage2 "DPB ECU: a012 pts non zero stage2";
CM_ SG_ 999 DPB_a013_softPedalChar "DPB ECU: a013 soft pedal char";
CM_ SG_ 999 DPB_a014_CANControllerHWFault "DPB ECU: a014 CAN controller HW fault";
CM_ SG_ 999 DPB_a015_CAN1BusOff "DPB ECU: a015 CAN1 bus off";
CM_ SG_ 999 DPB_a016_CAN2BusOff "DPB ECU: a016 CAN2 bus off";
CM_ SG_ 999 DPB_a017_largeLeakageDetected "DPB ECU: a017 large leakage detected";
CM_ SG_ 999 DPB_a018_largeLeakageDetectedGoo "DPB ECU: a018 large leakage detected good check";
CM_ SG_ 999 DPB_a019_DETReportError "DPB ECU: a019 DET report error";
CM_ SG_ 999 DPB_a020_ecuHuMismatch "DPB ECU: a020 ecu hu mismatch";
CM_ SG_ 999 DPB_a021_brakeSystemOverheatLvl1 "DPB ECU: a021 brake system overheat lvl1";
CM_ SG_ 999 DPB_a022_brakeSystemOverheatLvl2 "DPB ECU: a022 brake system overheat lvl2";
CM_ SG_ 999 DPB_a023_initialPlungerCheckFail "DPB ECU: a023 initial plunger check failed";
CM_ SG_ 999 DPB_a024_ESPLDMFailure "DPB ECU: a024 ESPLDM failure";
CM_ SG_ 999 DPB_a025_backupCircuitLeakage "DPB ECU: a025 backup circuit leakage";
CM_ SG_ 999 DPB_a026_LiPSIDTimeout "DPB ECU: a026 li PSID timeout";
CM_ SG_ 999 DPB_a027_motorTempHighLevel1 "DPB ECU: a027 motor temp high level1";
CM_ SG_ 999 DPB_a028_motorTempHighLevel2 "DPB ECU: a028 motor temp high level2";
CM_ SG_ 999 DPB_a029_motorTestFault "DPB ECU: a029 motor test fault";
CM_ SG_ 999 DPB_a030_notShutDownRight "DPB ECU: a030 not shut down right";
CM_ SG_ 999 DPB_a031_HWParamReadFailed "DPB ECU: a031 HW param read failed";
CM_ SG_ 999 DPB_a032_HWParamWriteFailed "DPB ECU: a032 HW param write failed";
CM_ SG_ 999 DPB_a033_motorDynamicLimited "DPB ECU: a033 motor dynamic limited";
CM_ SG_ 999 DPB_a034_lipsMemoryEmpty "DPB ECU: a034 lips memory empty";
CM_ SG_ 999 DPB_a035_PDURouterinitialization "DPB ECU: a035 PDU routerinitialization failed";
CM_ SG_ 999 DPB_a036_lossOfPDUInstanceDetect "DPB ECU: a036 loss of PDU instance detected";
CM_ SG_ 999 DPB_a037_plungerCircuitPressHigh "DPB ECU: a037 plunger circuit press high";
CM_ SG_ 999 DPB_a038_plungerCircuitPressHigh "DPB ECU: a038 plunger circuit press high good check";
CM_ SG_ 999 DPB_a039_plungerCircuitPressLow "DPB ECU: a039 plunger circuit press low";
CM_ SG_ 999 DPB_a040_plungerCircuitPressLowG "DPB ECU: a040 plunger circuit press low good check";
CM_ SG_ 999 DPB_a041_PSCGearRatioReadFault "DPB ECU: a041 PSC gear ratio read fault";
CM_ SG_ 999 DPB_a042_motorLoadPressImplausib "DPB ECU: a042 motor load press implausible";
CM_ SG_ 999 DPB_a043_PSCMotorSizeReadFault "DPB ECU: a043 PSC motor size read fault";
CM_ SG_ 999 DPB_a044_supplyOvervoltageLvl1 "DPB ECU: a044 supply overvoltage lvl1";
CM_ SG_ 999 DPB_a045_supplyOvervoltageLvl2 "DPB ECU: a045 supply overvoltage lvl2";
CM_ SG_ 999 DPB_a046_supplyOvervoltageLvl3 "DPB ECU: a046 supply overvoltage lvl3";
CM_ SG_ 999 DPB_a047_pPlungerPlausCheckFailu "DPB ECU: a047 p plunger plaus check failure";
CM_ SG_ 999 DPB_a048_supplyUndervoltageLvl1 "DPB ECU: a048 supply undervoltage lvl1";
CM_ SG_ 999 DPB_a049_supplyUndervoltageLvl2 "DPB ECU: a049 supply undervoltage lvl2";
CM_ SG_ 999 DPB_a050_supplyUndervoltageLvl3 "DPB ECU: a050 supply undervoltage lvl3";
CM_ SG_ 999 DPB_a051_PSCVoltageImplausible "DPB ECU: a051 PSC voltage implausible";
CM_ SG_ 999 DPB_a052_PSIDTimeOut "DPB ECU: a052 PSID time out";
CM_ SG_ 999 DPB_a053_hydraulicAssemblyModeAc "DPB ECU: a053 hydraulic assembly mode active";
CM_ SG_ 999 DPB_a054_unsupportedHW "DPB ECU: a054 unsupported HW";
CM_ SG_ 999 DPB_a055_unsupportedSeriesHWDete "DPB ECU: a055 unsupported series HW detected";
CM_ SG_ 999 DPB_a056_AdcPeripheralFault "DPB ECU: a056 adc peripheral fault";
CM_ SG_ 999 DPB_a057_AdcPinTest "DPB ECU: a057 adc pin test";
CM_ SG_ 999 DPB_a058_AdcSelftestC5P "DPB ECU: a058 adc selftest C5 p";
CM_ SG_ 999 DPB_a059_factoryModeActive "DPB ECU: a059 factory mode active";
CM_ SG_ 999 DPB_a060_motorBridgeDriverFault "DPB ECU: a060 motor bridge driver fault";
CM_ SG_ 999 DPB_a061_bridgeSwitchInitError "DPB ECU: a061 bridge switch init error";
CM_ SG_ 999 DPB_a062_loadDumpOnFSLTest "DPB ECU: a062 load dump on FSL test";
CM_ SG_ 999 DPB_a063_motorConfigMismatch "DPB ECU: a063 motor config mismatch";
CM_ SG_ 999 DPB_a064_current1OffsetHigh "DPB ECU: a064 current1 offset high";
CM_ SG_ 999 DPB_a065_current1OffsetLow "DPB ECU: a065 current1 offset low";
CM_ SG_ 999 DPB_a066_current2OffsetHigh "DPB ECU: a066 current2 offset high";
CM_ SG_ 999 DPB_a067_current2OffsetLow "DPB ECU: a067 current2 offset low";
CM_ SG_ 999 DPB_a068_BLMMuxerTimeoutError "DPB ECU: a068 BLM muxer timeout error";
CM_ SG_ 999 DPB_a069_OBDCurrent1OORHigh "DPB ECU: a069 OBD current1 OOR high";
CM_ SG_ 999 DPB_a070_OBDCurrent1OORLow "DPB ECU: a070 OBD current1 OOR low";
CM_ SG_ 999 DPB_a071_OBDCurrent2OORHigh "DPB ECU: a071 OBD current2 OOR high";
CM_ SG_ 999 DPB_a072_OBDCurrent2OORLow "DPB ECU: a072 OBD current2 OOR low";
CM_ SG_ 999 DPB_a073_rotorCosOutOfRangeHigh "DPB ECU: a073 rotor cos out of range high";
CM_ SG_ 999 DPB_a074_rotorCosOutOfRangeLow "DPB ECU: a074 rotor cos out of range low";
CM_ SG_ 999 DPB_a075_rotorSinOutOfRangeHigh "DPB ECU: a075 rotor sin out of range high";
CM_ SG_ 999 DPB_a076_rotorSinOutOfRangeLow "DPB ECU: a076 rotor sin out of range low";
CM_ SG_ 999 DPB_a077_tempSens1ShortToSupply "DPB ECU: a077 temp sens1 short to supply";
CM_ SG_ 999 DPB_a078_tempSens1ShortToGround "DPB ECU: a078 temp sens1 short to ground";
CM_ SG_ 999 DPB_a079_tempSens2ShortToSupply "DPB ECU: a079 temp sens2 short to supply";
CM_ SG_ 999 DPB_a080_tempSens2ShortToGround "DPB ECU: a080 temp sens2 short to ground";
CM_ SG_ 999 DPB_a081_tempSensImplausVoltage "DPB ECU: a081 temp sens implaus voltage";
CM_ SG_ 999 DPB_a082_chargePumpFault "DPB ECU: a082 charge pump fault";
CM_ SG_ 999 DPB_a083_chargePumpUndervoltage "DPB ECU: a083 charge pump undervoltage";
CM_ SG_ 999 DPB_a084_RBCPUException "DPB ECU: a084 RBCPU exception";
CM_ SG_ 999 DPB_a085_infoFailureWrongCUBASHa "DPB ECU: a085 info failure wrong CUBAS handling detected";
CM_ SG_ 999 DPB_a086_diagHydProtectionPressF "DPB ECU: a086 diag hyd protection press fault";
CM_ SG_ 999 DPB_a087_diagHydProtectionVlvFau "DPB ECU: a087 diag hyd protection vlv fault";
CM_ SG_ 999 DPB_a088_DMATransferError "DPB ECU: a088 DMA transfer error";
CM_ SG_ 999 DPB_a089_ecuBandgap "DPB ECU: a089 ecu bandgap";
CM_ SG_ 999 DPB_a090_flashFault "DPB ECU: a090 flash fault";
CM_ SG_ 999 DPB_a091_MRGPathTestFault "DPB ECU: a091 MRG path test fault";
CM_ SG_ 999 DPB_a092_decoupleBitTestFault "DPB ECU: a092 decouple bit test fault";
CM_ SG_ 999 DPB_a093_ecuBistFaultCtrFault "DPB ECU: a093 ecu bist fault ctr fault";
CM_ SG_ 999 DPB_a094_ecuClockTestFault "DPB ECU: a094 ecu clock test fault";
CM_ SG_ 999 DPB_a095_ecuEnableElHighFault "DPB ECU: a095 ecu enable el high fault";
CM_ SG_ 999 DPB_a096_ecuEnableElLowFault "DPB ECU: a096 ecu enable el low fault";
CM_ SG_ 999 DPB_a097_ecuEnableHyHighFault "DPB ECU: a097 ecu enable hy high fault";
CM_ SG_ 999 DPB_a098_ecuEnableHyLowFault "DPB ECU: a098 ecu enable hy low fault";
CM_ SG_ 999 DPB_a099_ecuEnContinuousError "DPB ECU: a099 ecu en continuous error";
CM_ SG_ 999 DPB_a100_ecuErrpinCounterFault "DPB ECU: a100 ecu errpin counter fault";
CM_ SG_ 999 DPB_a101_ecuFastWdTestFault "DPB ECU: a101 ecu fast wd test fault";
CM_ SG_ 999 DPB_a102_ecuVrOnWhileWdTimeout "DPB ECU: a102 ecu vr on while wd timeout";
CM_ SG_ 999 DPB_a103_ecuVrViaSpiFails "DPB ECU: a103 ecu vr via spi fails";
CM_ SG_ 999 DPB_a104_ecuWdStartuptestFault "DPB ECU: a104 ecu wd startuptest fault";
CM_ SG_ 999 DPB_a105_ecuWdSContinuousError "DPB ECU: a105 ecu wd s continuous error";
CM_ SG_ 999 DPB_a106_ecuBistCmdTestFault "DPB ECU: a106 ecu bist cmd test fault";
CM_ SG_ 999 DPB_a107_vrOnFails "DPB ECU: a107 vr on fails";
CM_ SG_ 999 DPB_a108_GTMRefFrequencyError "DPB ECU: a108 GTM ref frequency error";
CM_ SG_ 999 DPB_a109_GTMTbuMonError "DPB ECU: a109 GTM tbu mon error";
CM_ SG_ 999 DPB_a110_HWBISTError "DPB ECU: a110 HWBIST error";
CM_ SG_ 999 DPB_a111_hydraulicHardUndervolta "DPB ECU: a111 hydraulic hard undervoltage";
CM_ SG_ 999 DPB_a112_hydraulicUndervoltage "DPB ECU: a112 hydraulic undervoltage";
CM_ SG_ 999 DPB_a113_LiPS1SentLineHigh "DPB ECU: a113 li PS1 sent line high";
CM_ SG_ 999 DPB_a114_LiPS1SentLineLow "DPB ECU: a114 li PS1 sent line low";
CM_ SG_ 999 DPB_a115_LiPS1SentSensor "DPB ECU: a115 li PS1 sent sensor";
CM_ SG_ 999 DPB_a116_LiPS1SentTransmission "DPB ECU: a116 li PS1 sent transmission";
CM_ SG_ 999 DPB_a117_LiPS2PwmLineHigh "DPB ECU: a117 li PS2 pwm line high";
CM_ SG_ 999 DPB_a118_LiPS2PwmLineLow "DPB ECU: a118 li PS2 pwm line low";
CM_ SG_ 999 DPB_a119_LiPS2PwmTransmission "DPB ECU: a119 li PS2 pwm transmission";
CM_ SG_ 999 DPB_a120_LiPSOutOfRangeHigh "DPB ECU: a120 li PS out of range high";
CM_ SG_ 999 DPB_a121_LiPSOutOfRangeLow "DPB ECU: a121 li PS out of range low";
CM_ SG_ 999 DPB_a122_micAsicClkInError "DPB ECU: a122 mic asic clk in error";
CM_ SG_ 999 DPB_a123_micAsicInitTestError "DPB ECU: a123 mic asic init test error";
CM_ SG_ 999 DPB_a124_asicOscillatorError "DPB ECU: a124 asic oscillator error";
CM_ SG_ 999 DPB_a125_B6AsicFault "DPB ECU: a125 B6 asic fault";
CM_ SG_ 999 DPB_a126_MICB6TransferError "DPB ECU: a126 MICB6 transfer error";
CM_ SG_ 999 DPB_a127_hydraulicAsicShortCircu "DPB ECU: a127 hydraulic asic short circuit";
CM_ SG_ 999 DPB_a128_micSpiTransferError "DPB ECU: a128 mic spi transfer error";
CM_ SG_ 999 DPB_a129_AsicTrimmingNotComplete "DPB ECU: a129 asic trimming not completed";
CM_ SG_ 999 DPB_a130_AsicMalfunctionDetected "DPB ECU: a130 asic malfunction detected";
CM_ SG_ 999 DPB_a131_ASICOvercurrentOnGPIO25 "DPB ECU: a131 ASIC overcurrent on GPIO250 1";
CM_ SG_ 999 DPB_a132_ASICOvercurrentOnGPIO25 "DPB ECU: a132 ASIC overcurrent on GPIO250 2";
CM_ SG_ 999 DPB_a133_ASICOvercurrentOnGPIO50 "DPB ECU: a133 ASIC overcurrent on GPIO50 1";
CM_ SG_ 999 DPB_a134_ASICOvercurrentOnGPIO50 "DPB ECU: a134 ASIC overcurrent on GPIO50 2";
CM_ SG_ 999 DPB_a135_ASICOvercurrentOnGPIO50 "DPB ECU: a135 ASIC overcurrent on GPIO50 3";
CM_ SG_ 999 DPB_a136_ASICOvercurrentOnGPIO50 "DPB ECU: a136 ASIC overcurrent on GPIO50 4";
CM_ SG_ 999 DPB_a137_ASICOvercurrentOnWRHS "DPB ECU: a137 ASIC overcurrent on WRHS";
CM_ SG_ 999 DPB_a138_DIchassisControlCounter "DPB ECU: a138 d ichassis control counter";
CM_ SG_ 999 DPB_a139_DIchassisControlChecksu "DPB ECU: a139 d ichassis control checksum";
CM_ SG_ 999 DPB_a140_DIchassisControlDLC "DPB ECU: a140 d ichassis control DLC";
CM_ SG_ 999 DPB_a141_DIchassisControlTimeout "DPB ECU: a141 d ichassis control timeout";
CM_ SG_ 999 DPB_a142_DIsystemStatusCounter "DPB ECU: a142 d isystem status counter";
CM_ SG_ 999 DPB_a143_DIsystemStatusChecksum "DPB ECU: a143 d isystem status checksum";
CM_ SG_ 999 DPB_a144_DIsystemStatusDLC "DPB ECU: a144 d isystem status DLC";
CM_ SG_ 999 DPB_a145_DIsystemStatusTimeout "DPB ECU: a145 d isystem status timeout";
CM_ SG_ 999 DPB_a146_DIFtorqueCounter "DPB ECU: a146 DI ftorque counter";
CM_ SG_ 999 DPB_a147_DIFtorqueChecksum "DPB ECU: a147 DI ftorque checksum";
CM_ SG_ 999 DPB_a148_DIFtorqueDLC "DPB ECU: a148 DI ftorque DLC";
CM_ SG_ 999 DPB_a149_DIFtorqueTimeout "DPB ECU: a149 DI ftorque timeout";
CM_ SG_ 999 DPB_a150_DIRtorqueCounter "DPB ECU: a150 DI rtorque counter";
CM_ SG_ 999 DPB_a151_DIRtorqueChecksum "DPB ECU: a151 DI rtorque checksum";
CM_ SG_ 999 DPB_a152_DIRtorqueDLC "DPB ECU: a152 DI rtorque DLC";
CM_ SG_ 999 DPB_a153_DIRtorqueTimeout "DPB ECU: a153 DI rtorque timeout";
CM_ SG_ 999 DPB_a154_EPBLstatusCounter "DPB ECU: a154 EPB lstatus counter";
CM_ SG_ 999 DPB_a155_EPBLstatusChecksum "DPB ECU: a155 EPB lstatus checksum";
CM_ SG_ 999 DPB_a156_EPBLstatusDLC "DPB ECU: a156 EPB lstatus DLC";
CM_ SG_ 999 DPB_a157_EPBLstatusTimeout "DPB ECU: a157 EPB lstatus timeout";
CM_ SG_ 999 DPB_a158_EPBRstatusCounter "DPB ECU: a158 EPB rstatus counter";
CM_ SG_ 999 DPB_a159_EPBRstatusChecksum "DPB ECU: a159 EPB rstatus checksum";
CM_ SG_ 999 DPB_a160_EPBRstatusDLC "DPB ECU: a160 EPB rstatus DLC";
CM_ SG_ 999 DPB_a161_EPBRstatusTimeout "DPB ECU: a161 EPB rstatus timeout";
CM_ SG_ 999 DPB_a162_ESP_modulator1Counter "DPB ECU: a162 ESP modulator1 counter";
CM_ SG_ 999 DPB_a163_ESP_modulator1Checksum "DPB ECU: a163 ESP modulator1 checksum";
CM_ SG_ 999 DPB_a164_ESP_modulator1DLC "DPB ECU: a164 ESP modulator1 DLC";
CM_ SG_ 999 DPB_a165_ESP_modulator1Timeout "DPB ECU: a165 ESP modulator1 timeout";
CM_ SG_ 999 DPB_a166_ESP_chassis3Counter "DPB ECU: a166 ESP chassis3 counter";
CM_ SG_ 999 DPB_a167_ESP_chassis3Checksum "DPB ECU: a167 ESP chassis3 checksum";
CM_ SG_ 999 DPB_a168_ESP_chassis3DLC "DPB ECU: a168 ESP chassis3 DLC";
CM_ SG_ 999 DPB_a169_ESP_chassis3Timeout "DPB ECU: a169 ESP chassis3 timeout";
CM_ SG_ 999 DPB_a170_ESP_modulator2Counter "DPB ECU: a170 ESP modulator2 counter";
CM_ SG_ 999 DPB_a171_ESP_modulator2Checksum "DPB ECU: a171 ESP modulator2 checksum";
CM_ SG_ 999 DPB_a172_ESP_modulator2DLC "DPB ECU: a172 ESP modulator2 DLC";
CM_ SG_ 999 DPB_a173_ESP_modulator2Timeout "DPB ECU: a173 ESP modulator2 timeout";
CM_ SG_ 999 DPB_a174_ESP_modulator3Counter "DPB ECU: a174 ESP modulator3 counter";
CM_ SG_ 999 DPB_a175_ESP_modulator3Checksum "DPB ECU: a175 ESP modulator3 checksum";
CM_ SG_ 999 DPB_a176_ESP_modulator3DLC "DPB ECU: a176 ESP modulator3 DLC";
CM_ SG_ 999 DPB_a177_ESP_modulator3Timeout "DPB ECU: a177 ESP modulator3 timeout";
CM_ SG_ 999 DPB_a178_PMstate2Counter "DPB ECU: a178 p mstate2 counter";
CM_ SG_ 999 DPB_a179_PMstate2Checksum "DPB ECU: a179 p mstate2 checksum";
CM_ SG_ 999 DPB_a180_PMstate2DLC "DPB ECU: a180 p mstate2 DLC";
CM_ SG_ 999 DPB_a181_PMstate2Timeout "DPB ECU: a181 p mstate2 timeout";
CM_ SG_ 999 DPB_a182_RCMInertial2Counter "DPB ECU: a182 RCM inertial2 counter";
CM_ SG_ 999 DPB_a183_RCMInertial2Checksum "DPB ECU: a183 RCM inertial2 checksum";
CM_ SG_ 999 DPB_a184_RCMInertial2DLC "DPB ECU: a184 RCM inertial2 DLC";
CM_ SG_ 999 DPB_a185_RCMInertial2Timeout "DPB ECU: a185 RCM inertial2 timeout";
CM_ SG_ 999 DPB_a186_LVPowerStateTimeout "DPB ECU: a186 LV power state timeout";
CM_ SG_ 999 DPB_a187_LVPowerStateChecksum "DPB ECU: a187 LV power state checksum";
CM_ SG_ 999 DPB_a188_LVPowerStateDLC "DPB ECU: a188 LV power state DLC";
CM_ SG_ 999 DPB_a189_LVPowerStateCounter "DPB ECU: a189 LV power state counter";
CM_ SG_ 999 DPB_a190_VCLEFTepbmStatusCounter "DPB ECU: a190 VCLEF tepbm status counter";
CM_ SG_ 999 DPB_a191_VCLEFTepbmStatusChecksu "DPB ECU: a191 VCLEF tepbm status checksum";
CM_ SG_ 999 DPB_a192_VCLEFTepbmStatusDLC "DPB ECU: a192 VCLEF tepbm status DLC";
CM_ SG_ 999 DPB_a193_VCLEFTepbmStatusTimeout "DPB ECU: a193 VCLEF tepbm status timeout";
CM_ SG_ 999 DPB_a194_VCRIGHTepbmStatusCounte "DPB ECU: a194 VCRIGH tepbm status counter";
CM_ SG_ 999 DPB_a195_VCRIGHTepbmStatusChecks "DPB ECU: a195 VCRIGH tepbm status checksum";
CM_ SG_ 999 DPB_a196_VCRIGHTepbmStatusDLC "DPB ECU: a196 VCRIGH tepbm status DLC";
CM_ SG_ 999 DPB_a197_VCRIGHTepbmStatusTimeou "DPB ECU: a197 VCRIGH tepbm status timeout";
CM_ SG_ 999 DPB_a198_CANOvervoltage "DPB ECU: a198 CAN overvoltage";
CM_ SG_ 999 DPB_a199_pMC1QFaulty "DPB ECU: a199 p MC1 q faulty";
CM_ SG_ 999 DPB_a200_ESPRunoutSupportNotAvai "DPB ECU: a200 ESP runout support not available";
CM_ SG_ 999 DPB_a201_vehicleSpeedQFaulty "DPB ECU: a201 vehicle speed q faulty";
CM_ SG_ 999 DPB_a202_vehicleStandstillQFault "DPB ECU: a202 vehicle standstill q faulty";
CM_ SG_ 999 DPB_a203_ABSNotAvailable "DPB ECU: a203 ABS not available";
CM_ SG_ 999 DPB_a204_CANUndervoltage "DPB ECU: a204 CAN undervoltage";
CM_ SG_ 999 DPB_a205_NvMWriteCycleExceed "DPB ECU: a205 nv m write cycle exceed";
CM_ SG_ 999 DPB_a206_OSTaskSchemeError "DPB ECU: a206 OS task scheme error";
CM_ SG_ 999 DPB_a207_hydraulicOvervoltage "DPB ECU: a207 hydraulic overvoltage";
CM_ SG_ 999 DPB_a208_pressureSensor1Short "DPB ECU: a208 pressure sensor1 short";
CM_ SG_ 999 DPB_a209_pressureSensor1High "DPB ECU: a209 pressure sensor1 high";
CM_ SG_ 999 DPB_a210_pressureSensor1Low "DPB ECU: a210 pressure sensor1 low";
CM_ SG_ 999 DPB_a211_pressureSensor1Fault "DPB ECU: a211 pressure sensor1 fault";
CM_ SG_ 999 DPB_a212_pressureSensor1Temp "DPB ECU: a212 pressure sensor1 temp";
CM_ SG_ 999 DPB_a213_pressureSensor1Fault "DPB ECU: a213 pressure sensor1 fault";
CM_ SG_ 999 DPB_a214_pressureSensor2Short "DPB ECU: a214 pressure sensor2 short";
CM_ SG_ 999 DPB_a215_pressureSensor2High "DPB ECU: a215 pressure sensor2 high";
CM_ SG_ 999 DPB_a216_pressureSensor2Low "DPB ECU: a216 pressure sensor2 low";
CM_ SG_ 999 DPB_a217_pressureSensor2Fault "DPB ECU: a217 pressure sensor2 fault";
CM_ SG_ 999 DPB_a218_pressureSensor2Temp "DPB ECU: a218 pressure sensor2 temp";
CM_ SG_ 999 DPB_a219_pressureSensor2Fault "DPB ECU: a219 pressure sensor2 fault";
CM_ SG_ 999 DPB_a220_excessiveBoostWakeupsDe "DPB ECU: a220 excessive boost wakeups detected";
CM_ SG_ 999 DPB_a221_notShutdownRight "DPB ECU: a221 not shutdown right";
CM_ SG_ 999 DPB_a222_excessiveEcuResetsDetec "DPB ECU: a222 excessive ecu resets detected";
CM_ SG_ 999 DPB_a223_RAMFault "DPB ECU: a223 RAM fault";
CM_ SG_ 999 DPB_a224_brakeBoostLost "DPB ECU: a224 brake boost lost";
CM_ SG_ 999 DPB_a225_U5VOutOfRange "DPB ECU: a225 U5 v out of range";
CM_ SG_ 999 DPB_a226_U5VTestFault "DPB ECU: a226 U5 v test fault";
CM_ SG_ 999 DPB_a227_brakeFluidLoss "DPB ECU: a227 brake fluid loss";
CM_ SG_ 999 DPB_a228_supplyASICInitFault "DPB ECU: a228 supply ASIC init fault";
CM_ SG_ 999 DPB_a229_IREFOutOfRange "DPB ECU: a229 IREF out of range";
CM_ SG_ 999 DPB_a230_OSErrorHook "DPB ECU: a230 OS error hook";
CM_ SG_ 999 DPB_a231_stackOverUnderFlow "DPB ECU: a231 stack over under flow";
CM_ SG_ 999 DPB_a232_systemErrorHook "DPB ECU: a232 system error hook";
CM_ SG_ 999 DPB_a233_systemTaskJitter "DPB ECU: a233 system task jitter";
CM_ SG_ 999 DPB_a234_systemTaskOverRun "DPB ECU: a234 system task over run";
CM_ SG_ 999 DPB_a235_UB6PlausiMonFault "DPB ECU: a235 UB6 plausi mon fault";
CM_ SG_ 999 DPB_a236_UB6SupplyPathFault "DPB ECU: a236 UB6 supply path fault";
CM_ SG_ 999 DPB_a237_uCVoltageDividerDrift "DPB ECU: a237 u c voltage divider drift";
CM_ SG_ 999 DPB_a238_microRegisterFault "DPB ECU: a238 micro register fault";
CM_ SG_ 999 DPB_a239_microSafetyFault "DPB ECU: a239 micro safety fault";
CM_ SG_ 999 DPB_a240_microSafetyLogicFault "DPB ECU: a240 micro safety logic fault";
CM_ SG_ 999 DPB_a241_uCSafetyNotification "DPB ECU: a241 u c safety notification";
CM_ SG_ 999 DPB_a242_uCSafetyNotificationGRA "DPB ECU: a242 u c safety notification GRAM";
CM_ SG_ 999 DPB_a243_microSupplyError "DPB ECU: a243 micro supply error";
CM_ SG_ 999 DPB_a244_valvesGenericFault "DPB ECU: a244 valves generic fault";
CM_ SG_ 999 DPB_a245_valveMV0Fault "DPB ECU: a245 valve MV0 fault";
CM_ SG_ 999 DPB_a246_valveMV5Fault "DPB ECU: a246 valve MV5 fault";
CM_ SG_ 999 DPB_a247_valveMV6Fault "DPB ECU: a247 valve MV6 fault";
CM_ SG_ 999 DPB_a248_valveMV61Fault "DPB ECU: a248 valve MV61 fault";
CM_ SG_ 999 DPB_a249_valveMV62Fault "DPB ECU: a249 valve MV62 fault";
CM_ SG_ 999 DPB_a250_valveMV7Fault "DPB ECU: a250 valve MV7 fault";
CM_ SG_ 999 DPB_a251_valveMV8Fault "DPB ECU: a251 valve MV8 fault";
CM_ SG_ 999 DPB_a252_valveMV81Fault "DPB ECU: a252 valve MV81 fault";
CM_ SG_ 999 DPB_a253_valveMV82Fault "DPB ECU: a253 valve MV82 fault";
CM_ SG_ 999 DPB_a254_valveMV9Fault "DPB ECU: a254 valve MV9 fault";
CM_ SG_ 999 DPB_a255_valveRelayShort "DPB ECU: a255 valve relay short";
CM_ SG_ 999 DPB_a256_valveRelayActuationFaul "DPB ECU: a256 valve relay actuation fault";
CM_ SG_ 999 DPB_a257_valveRelayOnContinuous "DPB ECU: a257 valve relay on continuous";
CM_ SG_ 999 DPB_a258_valveRelayOffContinuous "DPB ECU: a258 valve relay off continuous";
CM_ SG_ 999 DPB_a259_valveRelayTestUndervolt "DPB ECU: a259 valve relay test undervoltage";
CM_ SG_ 999 DPB_a260_valveRelaySafetySwitchF "DPB ECU: a260 valve relay safety switch fault";
CM_ SG_ 999 DPB_a261_WdhAsicWdCmdMissing "DPB ECU: a261 wdh asic wd cmd missing";
CM_ SG_ 999 DPB_a262_WdhAsicWdErrorCntLimit "DPB ECU: a262 wdh asic wd error cnt limit";
CM_ SG_ 999 DPB_a263_WdhAsicWdErrorCntStuck "DPB ECU: a263 wdh asic wd error cnt stuck";
CM_ SG_ 999 DPB_a264_WdhSwBistConCnt "DPB ECU: a264 wdh sw bist con cnt";
CM_ SG_ 999 DPB_a265_WdhTaskMonConCnt "DPB ECU: a265 wdh task mon con cnt";
CM_ SG_ 999 DPB_a266_RPSNvMReadFault "DPB ECU: a266 RPS nv m read fault";
CM_ SG_ 999 DPB_a267_RpsAngleImplausible "DPB ECU: a267 rps angle implausible";
CM_ SG_ 999 DPB_a268_RPSVectorOscillating "DPB ECU: a268 RPS vector oscillating";
CM_ SG_ 999 DPB_a269_RPSVectorRangeHigh "DPB ECU: a269 RPS vector range high";
CM_ SG_ 999 DPB_a270_RPSVectorRangeLow "DPB ECU: a270 RPS vector range low";
CM_ SG_ 999 DPB_a271_RPSWrongCalibData "DPB ECU: a271 RPS wrong calib data";
CM_ SG_ 999 DPB_a272_runtimeAssertionFault "DPB ECU: a272 runtime assertion fault";
CM_ SG_ 999 DPB_a273_SMMOneRequestsInit "DPB ECU: a273 SMM one requests init";
CM_ SG_ 999 DPB_a274_AswSystemTimeOut "DPB ECU: a274 asw system time out";
CM_ SG_ 999 DPB_a275_Ps1Ps2PlausibilityFault "DPB ECU: a275 ps1 ps2 plausibility fault";
CM_ SG_ 999 DPB_a276_VCFRONTsensorsCounter "DPB ECU: a276 VCFRON tsensors counter";
CM_ SG_ 999 DPB_a277_VCFRONTsensorsChecksum "DPB ECU: a277 VCFRON tsensors checksum";
CM_ SG_ 999 DPB_a278_VCFRONTsensorsDLC "DPB ECU: a278 VCFRON tsensors DLC";
CM_ SG_ 999 DPB_a279_VCFRONTsensorsTimeout "DPB ECU: a279 VCFRON tsensors timeout";
CM_ SG_ 999 DPB_a280_LowBrakeFluid "DPB ECU: a280 low brake fluid";
CM_ SG_ 999 DPB_a281_brakeFluidOORHigh "DPB ECU: a281 brake fluid OOR high";
CM_ SG_ 999 DPB_a282_DIbrakeCommandCounter "DPB ECU: a282 d ibrake command counter";
CM_ SG_ 999 DPB_a283_DIbrakeCommandChecksum "DPB ECU: a283 d ibrake command checksum";
CM_ SG_ 999 DPB_a284_DIbrakeCommandDLC "DPB ECU: a284 d ibrake command DLC";
CM_ SG_ 999 DPB_a285_DIbrakeCommandTimeout "DPB ECU: a285 d ibrake command timeout";
CM_ SG_ 999 DPB_a286_ebrCmdStateInvalid "DPB ECU: a286 ebr cmd state invalid";
CM_ SG_ 999 DPB_a287_brakeCmdStateInvalid "DPB ECU: a287 brake cmd state invalid";
CM_ SG_ 999 DPB_a288_PlantDegradedSW "DPB ECU: a288 plant degraded SW";
CM_ SG_ 999 DPB_a289_evacFillNotComplete "DPB ECU: a289 evac fill not complete";
CM_ SG_ 999 DPB_a290_securityInfo "DPB ECU: a290 security info";
CM_ SG_ 999 DPB_a291_extDBRRequestTooLow "DPB ECU: a291 ext DBR request too low";
CM_ SG_ 999 DPB_a292_CBDS_fillBufferThreshol "DPB ECU: a292 CBDS fill buffer threshold";
CM_ SG_ 999 DPB_a293_CBDS_fmeInternalEvent "DPB ECU: a293 CBDS fme internal event";
CM_ SG_ 999 DPB_a294_hbaNormalModeActive "DPB ECU: a294 hba normal mode active";
CM_ SG_ 999 DPB_a295_hbaTrackModeActive "DPB ECU: a295 hba track mode active";
CM_ SG_ 999 DPB_a296_StatInvalid_DI_FullSNA "DPB ECU: a296 stat invalid DI full SNA";
CM_ SG_ 999 DPB_a297_undefinedAlertDetected "DPB ECU: a297 undefined alert detected";
CM_ SG_ 999 DPB_a298_RunningActiveSystemTest "DPB ECU: a298 running active system tests";
CM_ SG_ 999 DPB_a299_PM_locStateCounter "DPB ECU: a299 PM loc state counter";
CM_ SG_ 999 DPB_a300_PM_locStateChecksum "DPB ECU: a300 PM loc state checksum";
CM_ SG_ 999 DPB_a301_PM_locStateDLC "DPB ECU: a301 PM loc state DLC";
CM_ SG_ 999 DPB_a302_PM_locStateTimeout "DPB ECU: a302 PM loc state timeout";
CM_ SG_ 999 DPB_a303_actuatingDIFullTorqueCm "DPB ECU: a303 actuating DI full torque cmd";
CM_ SG_ 999 DPB_a304_actuatingDITorqueCmd "DPB ECU: a304 actuating DI torque cmd";
CM_ SG_ 999 DPB_a305_DIbrakeTorqueCommandAnd "DPB ECU: a305 d ibrake torque command and flag mismatch";
CM_ SG_ 999 DPB_a306_actuatorFallbackBasicMa "DPB ECU: a306 actuator fallback basic map";
CM_ SG_ 999 DPB_a307_actuatorDegradedMap "DPB ECU: a307 actuator degraded map";
CM_ SG_ 999 DPB_a308_hydraulicPushthroughAct "DPB ECU: a308 hydraulic pushthrough active";
CM_ SG_ 999 DPB_a309_DIFAxleTorqueInvalid "DPB ECU: a309 DIF axle torque invalid";
CM_ SG_ 999 DPB_a310_DIRAxleTorqueInvalid "DPB ECU: a310 DIR axle torque invalid";
CM_ SG_ 999 DPB_a311_postrunDurationTooLong "DPB ECU: a311 postrun duration too long";
CM_ SG_ 999 DPB_a312_cyclicVolumeCheckDisabl "DPB ECU: a312 cyclic volume check disabled";
CM_ SG_ 999 DPB_a313_qualifiedBrakeEventDete "DPB ECU: a313 qualified brake event detected";
CM_ BO_ 1426 "Electric power steering (primary) message: alert log";
CM_ SG_ 1426 EPAS3P_alertID "Electric power steering (primary): alert ID";
CM_ SG_ 1426 EPAS3P_alertState "Electric power steering (primary): alert state";
CM_ SG_ 1426 EPAS3P_a147_transitionReason "Electric power steering (primary): a147 transition reason";
CM_ SG_ 1426 EPAS3P_a148_vehicleSpeed "Electric power steering (primary): a148 vehicle speed";
CM_ SG_ 1426 EPAS3P_a149_pcbTemp "Electric power steering (primary): a149 pcb temp";
CM_ SG_ 1426 EPAS3P_a150_pcbTemp "Electric power steering (primary): a150 pcb temp";
CM_ SG_ 1426 EPAS3P_a150_phaUMainPathCalcDiff "Electric power steering (primary): a150 pha u main path calc diff";
CM_ SG_ 1426 EPAS3P_a150_phaVMainPathCalcDiff "Electric power steering (primary): a150 pha v main path calc diff";
CM_ SG_ 1426 EPAS3P_a150_otherECUAssistStatus "Electric power steering (primary): a150 other ECU assist status flag";
CM_ SG_ 1426 EPAS3P_a151_dcsVBridge "Electric power steering (primary): a151 dcs v bridge";
CM_ SG_ 1426 EPAS3P_a151_dcsMainChannelA "Electric power steering (primary): a151 dcs main channel a";
CM_ SG_ 1426 EPAS3P_a151_dcsMainChannelB "Electric power steering (primary): a151 dcs main channel b";
CM_ SG_ 1426 EPAS3P_a151_dcsOffsetA "Electric power steering (primary): a151 dcs offset a";
CM_ SG_ 1426 EPAS3P_a151_dcsOffsetB "Electric power steering (primary): a151 dcs offset b";
CM_ SG_ 1426 EPAS3P_a151_dcsCBootA "Electric power steering (primary): a151 dcs c boot a";
CM_ SG_ 1426 EPAS3P_a151_dcsCBootB "Electric power steering (primary): a151 dcs c boot b";
CM_ SG_ 1426 EPAS3P_a152_dcsVBridge "Electric power steering (primary): a152 dcs v bridge";
CM_ SG_ 1426 EPAS3P_a152_dcsModIndex "Electric power steering (primary): a152 dcs mod index";
CM_ SG_ 1426 EPAS3P_a152_dcsMainPathErrReg "Electric power steering (primary): a152 dcs main path err reg";
CM_ SG_ 1426 EPAS3P_a152_dcsTubErrReg "Electric power steering (primary): a152 dcs tub err reg";
CM_ SG_ 1426 EPAS3P_a152_dcsErrSumReg "Electric power steering (primary): a152 dcs err sum reg";
CM_ SG_ 1426 EPAS3P_a152_dcsVbusDiagPathErrRe "Electric power steering (primary): a152 dcs vbus diag path err reg";
CM_ SG_ 1426 EPAS3P_a154_vehicleSpeed "Electric power steering (primary): a154 vehicle speed";
CM_ SG_ 1426 EPAS3P_a155_vehicleSpeed "Electric power steering (primary): a155 vehicle speed";
CM_ SG_ 1426 EPAS3P_a156_vehicleSpeed "Electric power steering (primary): a156 vehicle speed";
CM_ BO_ 2036 "Electric power steering (primary) message: alert matrix";
CM_ SG_ 2036 EPAS3P_matrixIndex "Electric power steering (primary): matrix index";
CM_ SG_ 2036 EPAS3P_a001_sent1Mia "Electric power steering (primary): a001 sent1 mia";
CM_ SG_ 2036 EPAS3P_a002_sent1Error "Electric power steering (primary): a002 sent1 error";
CM_ SG_ 2036 EPAS3P_a003_trqSens1Supply "Electric power steering (primary): a003 trq sens1 supply";
CM_ SG_ 2036 EPAS3P_a004_trqSens1Eeprom "Electric power steering (primary): a004 trq sens1 eeprom";
CM_ SG_ 2036 EPAS3P_a005_sent2Mia "Electric power steering (primary): a005 sent2 mia";
CM_ SG_ 2036 EPAS3P_a006_sent2Error "Electric power steering (primary): a006 sent2 error";
CM_ SG_ 2036 EPAS3P_a007_trqSens2Supply "Electric power steering (primary): a007 trq sens2 supply";
CM_ SG_ 2036 EPAS3P_a008_trqSens2Eeprom "Electric power steering (primary): a008 trq sens2 eeprom";
CM_ SG_ 2036 EPAS3P_a009_sentDiff "Electric power steering (primary): a009 sent diff";
CM_ SG_ 2036 EPAS3P_a010_trqSensCalError "Electric power steering (primary): a010 trq sens cal error";
CM_ SG_ 2036 EPAS3P_a011_currentSensError "Electric power steering (primary): a011 current sens error";
CM_ SG_ 2036 EPAS3P_a012_currentSensCalError "Electric power steering (primary): a012 current sens cal error";
CM_ SG_ 2036 EPAS3P_a013_gateDriveError "Electric power steering (primary): a013 gate drive error";
CM_ SG_ 2036 EPAS3P_a014_gateDriveTxError "Electric power steering (primary): a014 gate drive tx error";
CM_ SG_ 2036 EPAS3P_a015_gateDriveEeprom "Electric power steering (primary): a015 gate drive eeprom";
CM_ SG_ 2036 EPAS3P_a016_phaseUhighUv "Electric power steering (primary): a016 phase uhigh uv";
CM_ SG_ 2036 EPAS3P_a017_phaseUlowUv "Electric power steering (primary): a017 phase ulow uv";
CM_ SG_ 2036 EPAS3P_a018_phaseVhighUv "Electric power steering (primary): a018 phase vhigh uv";
CM_ SG_ 2036 EPAS3P_a019_phaseVlowUv "Electric power steering (primary): a019 phase vlow uv";
CM_ SG_ 2036 EPAS3P_a020_phaseWhighUv "Electric power steering (primary): a020 phase whigh uv";
CM_ SG_ 2036 EPAS3P_a021_phaseWlowUv "Electric power steering (primary): a021 phase wlow uv";
CM_ SG_ 2036 EPAS3P_a022_phaseUhighOv "Electric power steering (primary): a022 phase uhigh ov";
CM_ SG_ 2036 EPAS3P_a023_phaseUlowOv "Electric power steering (primary): a023 phase ulow ov";
CM_ SG_ 2036 EPAS3P_a024_phaseVhighOv "Electric power steering (primary): a024 phase vhigh ov";
CM_ SG_ 2036 EPAS3P_a025_phaseVlowOv "Electric power steering (primary): a025 phase vlow ov";
CM_ SG_ 2036 EPAS3P_a026_phaseWhighOv "Electric power steering (primary): a026 phase whigh ov";
CM_ SG_ 2036 EPAS3P_a027_phaseWlowOv "Electric power steering (primary): a027 phase wlow ov";
CM_ SG_ 2036 EPAS3P_a028_phaseUbootUv "Electric power steering (primary): a028 phase uboot uv";
CM_ SG_ 2036 EPAS3P_a029_phaseVbootUv "Electric power steering (primary): a029 phase vboot uv";
CM_ SG_ 2036 EPAS3P_a030_phaseWbootUv "Electric power steering (primary): a030 phase wboot uv";
CM_ SG_ 2036 EPAS3P_a031_abnormalShutdown "Electric power steering (primary): a031 abnormal shutdown";
CM_ SG_ 2036 EPAS3P_a032_vRegOutputUv "Electric power steering (primary): a032 v reg output uv";
CM_ SG_ 2036 EPAS3P_a033_vRegOutputOv "Electric power steering (primary): a033 v reg output ov";
CM_ SG_ 2036 EPAS3P_a034_vRegError "Electric power steering (primary): a034 v reg error";
CM_ SG_ 2036 EPAS3P_a035_vbbSupplyUv "Electric power steering (primary): a035 vbb supply uv";
CM_ SG_ 2036 EPAS3P_a036_vbbSupplyOv "Electric power steering (primary): a036 vbb supply ov";
CM_ SG_ 2036 EPAS3P_a037_motPos1ParityError "Electric power steering (primary): a037 mot pos1 parity error";
CM_ SG_ 2036 EPAS3P_a038_motPos1Uv "Electric power steering (primary): a038 mot pos1 uv";
CM_ SG_ 2036 EPAS3P_a039_motPos1MagnetMia "Electric power steering (primary): a039 mot pos1 magnet mia";
CM_ SG_ 2036 EPAS3P_a040_motPos1LogicError "Electric power steering (primary): a040 mot pos1 logic error";
CM_ SG_ 2036 EPAS3P_a041_motPos1tempError "Electric power steering (primary): a041 mot pos1temp error";
CM_ SG_ 2036 EPAS3P_a042_motPos2ParityError "Electric power steering (primary): a042 mot pos2 parity error";
CM_ SG_ 2036 EPAS3P_a043_motPos2Uv "Electric power steering (primary): a043 mot pos2 uv";
CM_ SG_ 2036 EPAS3P_a044_motPos2MagnetMia "Electric power steering (primary): a044 mot pos2 magnet mia";
CM_ SG_ 2036 EPAS3P_a045_motPos2LogicError "Electric power steering (primary): a045 mot pos2 logic error";
CM_ SG_ 2036 EPAS3P_a046_motPos2tempError "Electric power steering (primary): a046 mot pos2temp error";
CM_ SG_ 2036 EPAS3P_a047_motPosCorrError "Electric power steering (primary): a047 mot pos corr error";
CM_ SG_ 2036 EPAS3P_a048_motPosCalError "Electric power steering (primary): a048 mot pos cal error";
CM_ SG_ 2036 EPAS3P_a049_piCtrlError "Electric power steering (primary): a049 pi ctrl error";
CM_ SG_ 2036 EPAS3P_a050_mcuSmuError "Electric power steering (primary): a050 mcu smu error";
CM_ SG_ 2036 EPAS3P_a051_mcuSupError "Electric power steering (primary): a051 mcu sup error";
CM_ SG_ 2036 EPAS3P_a052_intWatchdogError "Electric power steering (primary): a052 int watchdog error";
CM_ SG_ 2036 EPAS3P_a053_extWatchdogError "Electric power steering (primary): a053 ext watchdog error";
CM_ SG_ 2036 EPAS3P_a054_memoryProtectError "Electric power steering (primary): a054 memory protect error";
CM_ SG_ 2036 EPAS3P_a055_floatPointError "Electric power steering (primary): a055 float point error";
CM_ SG_ 2036 EPAS3P_a056_battUv "Electric power steering (primary): a056 batt uv";
CM_ SG_ 2036 EPAS3P_a057_battUvReduced "Electric power steering (primary): a057 batt uv reduced";
CM_ SG_ 2036 EPAS3P_a058_battOv "Electric power steering (primary): a058 batt ov";
CM_ SG_ 2036 EPAS3P_a059_battOvReduced "Electric power steering (primary): a059 batt ov reduced";
CM_ SG_ 2036 EPAS3P_a060_battBridgeDiff "Electric power steering (primary): a060 batt bridge diff";
CM_ SG_ 2036 EPAS3P_a061_bridgeUv "Electric power steering (primary): a061 bridge uv";
CM_ SG_ 2036 EPAS3P_a062_assistCorrError "Electric power steering (primary): a062 assist corr error";
CM_ SG_ 2036 EPAS3P_a063_dampCorrError "Electric power steering (primary): a063 damp corr error";
CM_ SG_ 2036 EPAS3P_a064_phaseCompCorrError "Electric power steering (primary): a064 phase comp corr error";
CM_ SG_ 2036 EPAS3P_a065_trqTarCorrError "Electric power steering (primary): a065 trq tar corr error";
CM_ SG_ 2036 EPAS3P_a066_returnCorrError "Electric power steering (primary): a066 return corr error";
CM_ SG_ 2036 EPAS3P_a067_yawDampCorrError "Electric power steering (primary): a067 yaw damp corr error";
CM_ SG_ 2036 EPAS3P_a068_hystCorrError "Electric power steering (primary): a068 hyst corr error";
CM_ SG_ 2036 EPAS3P_a069_eacCorrError "Electric power steering (primary): a069 eac corr error";
CM_ SG_ 2036 EPAS3P_a070_hodCorrError "Electric power steering (primary): a070 hod corr error";
CM_ SG_ 2036 EPAS3P_a071_vehSpdCorrError "Electric power steering (primary): a071 veh spd corr error";
CM_ SG_ 2036 EPAS3P_a072_motFeedFwdError "Electric power steering (primary): a072 mot feed fwd error";
CM_ SG_ 2036 EPAS3P_a073_motParEstError "Electric power steering (primary): a073 mot par est error";
CM_ SG_ 2036 EPAS3P_a074_overHeatProtect "Electric power steering (primary): a074 over heat protect";
CM_ SG_ 2036 EPAS3P_a075_fspPwrCut "Electric power steering (primary): a075 fsp pwr cut";
CM_ SG_ 2036 EPAS3P_a076_tempSensOutofRange "Electric power steering (primary): a076 temp sens outof range";
CM_ SG_ 2036 EPAS3P_a077_highSideFetError "Electric power steering (primary): a077 high side fet error";
CM_ SG_ 2036 EPAS3P_a078_phaseDisconnectError "Electric power steering (primary): a078 phase disconnect error";
CM_ SG_ 2036 EPAS3P_a079_backupCurrentPlaus "Electric power steering (primary): a079 backup current plaus";
CM_ SG_ 2036 EPAS3P_a080_ecuInitArbError "Electric power steering (primary): a080 ecu init arb error";
CM_ SG_ 2036 EPAS3P_a081_coggCompError "Electric power steering (primary): a081 cogg comp error";
CM_ SG_ 2036 EPAS3P_a082_polarityCalError "Electric power steering (primary): a082 polarity cal error";
CM_ SG_ 2036 EPAS3P_a083_crcMismatch "Electric power steering (primary): a083 crc mismatch";
CM_ SG_ 2036 EPAS3P_a084_eacCancelled "Electric power steering (primary): a084 eac cancelled";
CM_ SG_ 2036 EPAS3P_a085_canBusOff "Electric power steering (primary): a085 can bus off";
CM_ SG_ 2036 EPAS3P_a086_dasMia "Electric power steering (primary): a086 das mia";
CM_ SG_ 2036 EPAS3P_a087_dasCntError "Electric power steering (primary): a087 das cnt error";
CM_ SG_ 2036 EPAS3P_a088_dasCsError "Electric power steering (primary): a088 das cs error";
CM_ SG_ 2036 EPAS3P_a089_espWsMia "Electric power steering (primary): a089 esp ws mia";
CM_ SG_ 2036 EPAS3P_a090_espWsCntError "Electric power steering (primary): a090 esp ws cnt error";
CM_ SG_ 2036 EPAS3P_a091_espWsCsError "Electric power steering (primary): a091 esp ws cs error";
CM_ SG_ 2036 EPAS3P_a092_espWrMia "Electric power steering (primary): a092 esp wr mia";
CM_ SG_ 2036 EPAS3P_a093_espWrCntError "Electric power steering (primary): a093 esp wr cnt error";
CM_ SG_ 2036 EPAS3P_a094_espWrCsError "Electric power steering (primary): a094 esp wr cs error";
CM_ SG_ 2036 EPAS3P_a095_espWsStatus "Electric power steering (primary): a095 esp ws status";
CM_ SG_ 2036 EPAS3P_a096_rcmMia "Electric power steering (primary): a096 rcm mia";
CM_ SG_ 2036 EPAS3P_a097_rcmCntError "Electric power steering (primary): a097 rcm cnt error";
CM_ SG_ 2036 EPAS3P_a098_rcmCsError "Electric power steering (primary): a098 rcm cs error";
CM_ SG_ 2036 EPAS3P_a099_yawRateStatus "Electric power steering (primary): a099 yaw rate status";
CM_ SG_ 2036 EPAS3P_a100_diMia "Electric power steering (primary): a100 di mia";
CM_ SG_ 2036 EPAS3P_a101_diCntError "Electric power steering (primary): a101 di cnt error";
CM_ SG_ 2036 EPAS3P_a102_diCsError "Electric power steering (primary): a102 di cs error";
CM_ SG_ 2036 EPAS3P_a103_vcFrontMia "Electric power steering (primary): a103 vc front mia";
CM_ SG_ 2036 EPAS3P_a104_vcFrontCntError "Electric power steering (primary): a104 vc front cnt error";
CM_ SG_ 2036 EPAS3P_a105_vcFrontCsError "Electric power steering (primary): a105 vc front cs error";
CM_ SG_ 2036 EPAS3P_a106_vcFrontTempMia "Electric power steering (primary): a106 vc front temp mia";
CM_ SG_ 2036 EPAS3P_a107_uiTuneReqMia "Electric power steering (primary): a107 ui tune req mia";
CM_ SG_ 2036 EPAS3P_a108_uiTuneReqCntError "Electric power steering (primary): a108 ui tune req cnt error";
CM_ SG_ 2036 EPAS3P_a109_uiTuneReqCsError "Electric power steering (primary): a109 ui tune req cs error";
CM_ SG_ 2036 EPAS3P_a110_sasMia "Electric power steering (primary): a110 sas mia";
CM_ SG_ 2036 EPAS3P_a111_sasCntError "Electric power steering (primary): a111 sas cnt error";
CM_ SG_ 2036 EPAS3P_a112_sasCsError "Electric power steering (primary): a112 sas cs error";
CM_ SG_ 2036 EPAS3P_a113_sasStatusError "Electric power steering (primary): a113 sas status error";
CM_ SG_ 2036 EPAS3P_a114_gtwConfigMia "Electric power steering (primary): a114 gtw config mia";
CM_ SG_ 2036 EPAS3P_a115_ecuStatMia "Electric power steering (primary): a115 ecu stat mia";
CM_ SG_ 2036 EPAS3P_a116_ecuStatCntError "Electric power steering (primary): a116 ecu stat cnt error";
CM_ SG_ 2036 EPAS3P_a117_ecuStatCrcError "Electric power steering (primary): a117 ecu stat crc error";
CM_ SG_ 2036 EPAS3P_a118_privateBusOff "Electric power steering (primary): a118 private bus off";
CM_ SG_ 2036 EPAS3P_a119_pvtEcuStatMia "Electric power steering (primary): a119 pvt ecu stat mia";
CM_ SG_ 2036 EPAS3P_a120_pvtEcuStatCntError "Electric power steering (primary): a120 pvt ecu stat cnt error";
CM_ SG_ 2036 EPAS3P_a121_pvtEcuStatCrcError "Electric power steering (primary): a121 pvt ecu stat crc error";
CM_ SG_ 2036 EPAS3P_a122_olpActive "Electric power steering (primary): a122 olp active";
CM_ SG_ 2036 EPAS3P_a123_combEcu2StatFail "Electric power steering (primary): a123 comb ecu2 stat fail";
CM_ SG_ 2036 EPAS3P_a124_tempSensStuckInRange "Electric power steering (primary): a124 temp sens stuck in range";
CM_ SG_ 2036 EPAS3P_a125_trqSensTrimOutRange "Electric power steering (primary): a125 trq sens trim out range";
CM_ SG_ 2036 EPAS3P_a126_apsMia "Electric power steering (primary): a126 aps mia";
CM_ SG_ 2036 EPAS3P_a127_apsCntError "Electric power steering (primary): a127 aps cnt error";
CM_ SG_ 2036 EPAS3P_a128_apsCsError "Electric power steering (primary): a128 aps cs error";
CM_ SG_ 2036 EPAS3P_a129_combEcu1StatFail "Electric power steering (primary): a129 comb ecu1 stat fail";
CM_ SG_ 2036 EPAS3P_a130_sasOffsetNotCal "Electric power steering (primary): a130 sas offset not cal";
CM_ SG_ 2036 EPAS3P_a131_phaseFeedbackError "Electric power steering (primary): a131 phase feedback error";
CM_ SG_ 2036 EPAS3P_a132_motFeedFwdCounter25 "Electric power steering (primary): a132 mot feed fwd counter25";
CM_ SG_ 2036 EPAS3P_a133_motFeedFwdCounter50 "Electric power steering (primary): a133 mot feed fwd counter50";
CM_ SG_ 2036 EPAS3P_a134_motFeedFwdCounter85 "Electric power steering (primary): a134 mot feed fwd counter85";
CM_ SG_ 2036 EPAS3P_a135_piCtrlCounter25 "Electric power steering (primary): a135 pi ctrl counter25";
CM_ SG_ 2036 EPAS3P_a136_piCtrlCounter50 "Electric power steering (primary): a136 pi ctrl counter50";
CM_ SG_ 2036 EPAS3P_a137_piCtrlCounter85 "Electric power steering (primary): a137 pi ctrl counter85";
CM_ SG_ 2036 EPAS3P_a144_diSpdMia "Electric power steering (primary): a144 di spd mia";
CM_ SG_ 2036 EPAS3P_a145_diSpdCntError "Electric power steering (primary): a145 di spd cnt error";
CM_ SG_ 2036 EPAS3P_a146_diSpdCsError "Electric power steering (primary): a146 di spd cs error";
CM_ SG_ 2036 EPAS3P_a147_backupVehSpeed "Electric power steering (primary): a147 backup veh speed";
CM_ SG_ 2036 EPAS3P_a148_vMaxAssist "Electric power steering (primary): a148 v max assist";
CM_ SG_ 2036 EPAS3P_a149_currentSensPathSwitc "Electric power steering (primary): a149 current sens path switch";
CM_ SG_ 2036 EPAS3P_a150_currentSensOffsetDet "Electric power steering (primary): a150 current sens offset detect";
CM_ SG_ 2036 EPAS3P_a151_dcsCboot "Electric power steering (primary): a151 dcs cboot";
CM_ SG_ 2036 EPAS3P_a152_dcsDiagReg "Electric power steering (primary): a152 dcs diag reg";
CM_ SG_ 2036 EPAS3P_a153_dcsInitOffset "Electric power steering (primary): a153 dcs init offset";
CM_ SG_ 2036 EPAS3P_a154_assistTorqueDisabled "Electric power steering (primary): a154 assist torque disabled";
CM_ SG_ 2036 EPAS3P_a155_backupEacActive "Electric power steering (primary): a155 backup eac active";
CM_ SG_ 2036 EPAS3P_a156_angleSensorDivergenc "Electric power steering (primary): a156 angle sensor divergence";
CM_ BO_ 883 "Electric power steering (primary) message: sys status";
CM_ SG_ 883 EPAS3P_steeringRackForce "The real time, estimated force applied by the steering rack to the tie rods; raw 1023 = signal not available (SNA)";
CM_ SG_ 883 EPAS3P_steeringFault "Electric power steering (primary): steering fault";
CM_ SG_ 883 EPAS3P_steeringReduced "Electric power steering (primary): steering reduced";
CM_ SG_ 883 EPAS3P_internalSASQF "This signal identifies the validity of the EPAS3P_internalSAS signal.";
CM_ SG_ 883 EPAS3P_currentTuneMode "Electric power steering (primary): current tune mode";
CM_ SG_ 883 EPAS3P_torsionBarTorque "The measurement of the steering wheel torque input. If the value is positive the steering wheel torque is applied in the clockwise direction; raw 4095 = signal not available (SNA)";
CM_ SG_ 883 EPAS3P_eacErrorCode "Electric power steering (primary): eac error code; raw 15 = signal not available (SNA)";
CM_ SG_ 883 EPAS3P_internalSAS "The measurement of the steering wheel angle that is calculated by electronic power steering assist steering. Clockwise positive.";
CM_ SG_ 883 EPAS3P_handsOnLevel "Electric power steering (primary): hands on level";
CM_ SG_ 883 EPAS3P_sysStatusCounter "Electric power steering (primary): sys status counter";
CM_ SG_ 883 EPAS3P_tireIDActive "Electric power steering (primary): tire ID active";
CM_ SG_ 883 EPAS3P_eacStatus "Electric power steering (primary): eac status";
CM_ SG_ 883 EPAS3P_sysStatusChecksum "Electric power steering (primary): sys status checksum";
CM_ BO_ 1592 "Electric power steering (primary) message: uds response CH";
CM_ SG_ 1592 EPAS3P_udsResponseDataCH "Electric power steering (primary): uds response data CH";
CM_ BO_ 1425 "Electric power steering (secondary) message: alert log";
CM_ SG_ 1425 EPAS3S_alertID "Electric power steering (secondary): alert ID";
CM_ SG_ 1425 EPAS3S_alertState "Electric power steering (secondary): alert state";
CM_ SG_ 1425 EPAS3S_a147_transitionReason "Electric power steering (secondary): a147 transition reason";
CM_ SG_ 1425 EPAS3S_a148_vehicleSpeed "Electric power steering (secondary): a148 vehicle speed";
CM_ SG_ 1425 EPAS3S_a149_pcbTemp "Electric power steering (secondary): a149 pcb temp";
CM_ SG_ 1425 EPAS3S_a150_pcbTemp "Electric power steering (secondary): a150 pcb temp";
CM_ SG_ 1425 EPAS3S_a150_phaUMainPathCalcDiff "Electric power steering (secondary): a150 pha u main path calc diff";
CM_ SG_ 1425 EPAS3S_a150_phaVMainPathCalcDiff "Electric power steering (secondary): a150 pha v main path calc diff";
CM_ SG_ 1425 EPAS3S_a150_otherECUAssistStatus "Electric power steering (secondary): a150 other ECU assist status flag";
CM_ SG_ 1425 EPAS3S_a151_dcsVBridge "Electric power steering (secondary): a151 dcs v bridge";
CM_ SG_ 1425 EPAS3S_a151_dcsMainChannelA "Electric power steering (secondary): a151 dcs main channel a";
CM_ SG_ 1425 EPAS3S_a151_dcsMainChannelB "Electric power steering (secondary): a151 dcs main channel b";
CM_ SG_ 1425 EPAS3S_a151_dcsOffsetA "Electric power steering (secondary): a151 dcs offset a";
CM_ SG_ 1425 EPAS3S_a151_dcsOffsetB "Electric power steering (secondary): a151 dcs offset b";
CM_ SG_ 1425 EPAS3S_a151_dcsCBootA "Electric power steering (secondary): a151 dcs c boot a";
CM_ SG_ 1425 EPAS3S_a151_dcsCBootB "Electric power steering (secondary): a151 dcs c boot b";
CM_ SG_ 1425 EPAS3S_a152_dcsVBridge "Electric power steering (secondary): a152 dcs v bridge";
CM_ SG_ 1425 EPAS3S_a152_dcsModIndex "Electric power steering (secondary): a152 dcs mod index";
CM_ SG_ 1425 EPAS3S_a152_dcsMainPathErrReg "Electric power steering (secondary): a152 dcs main path err reg";
CM_ SG_ 1425 EPAS3S_a152_dcsTubErrReg "Electric power steering (secondary): a152 dcs tub err reg";
CM_ SG_ 1425 EPAS3S_a152_dcsErrSumReg "Electric power steering (secondary): a152 dcs err sum reg";
CM_ SG_ 1425 EPAS3S_a152_dcsVbusDiagPathErrRe "Electric power steering (secondary): a152 dcs vbus diag path err reg";
CM_ SG_ 1425 EPAS3S_a154_vehicleSpeed "Electric power steering (secondary): a154 vehicle speed";
CM_ SG_ 1425 EPAS3S_a155_vehicleSpeed "Electric power steering (secondary): a155 vehicle speed";
CM_ SG_ 1425 EPAS3S_a156_vehicleSpeed "Electric power steering (secondary): a156 vehicle speed";
CM_ BO_ 913 "Electric power steering (secondary) message: alert matrix";
CM_ SG_ 913 EPAS3S_matrixIndex "Electric power steering (secondary): matrix index";
CM_ SG_ 913 EPAS3S_a001_sent1Mia "Electric power steering (secondary): a001 sent1 mia";
CM_ SG_ 913 EPAS3S_a002_sent1Error "Electric power steering (secondary): a002 sent1 error";
CM_ SG_ 913 EPAS3S_a003_trqSens1Supply "Electric power steering (secondary): a003 trq sens1 supply";
CM_ SG_ 913 EPAS3S_a004_trqSens1Eeprom "Electric power steering (secondary): a004 trq sens1 eeprom";
CM_ SG_ 913 EPAS3S_a005_sent2Mia "Electric power steering (secondary): a005 sent2 mia";
CM_ SG_ 913 EPAS3S_a006_sent2Error "Electric power steering (secondary): a006 sent2 error";
CM_ SG_ 913 EPAS3S_a007_trqSens2Supply "Electric power steering (secondary): a007 trq sens2 supply";
CM_ SG_ 913 EPAS3S_a008_trqSens2Eeprom "Electric power steering (secondary): a008 trq sens2 eeprom";
CM_ SG_ 913 EPAS3S_a009_sentDiff "Electric power steering (secondary): a009 sent diff";
CM_ SG_ 913 EPAS3S_a010_trqSensCalError "Electric power steering (secondary): a010 trq sens cal error";
CM_ SG_ 913 EPAS3S_a011_currentSensError "Electric power steering (secondary): a011 current sens error";
CM_ SG_ 913 EPAS3S_a012_currentSensCalError "Electric power steering (secondary): a012 current sens cal error";
CM_ SG_ 913 EPAS3S_a013_gateDriveError "Electric power steering (secondary): a013 gate drive error";
CM_ SG_ 913 EPAS3S_a014_gateDriveTxError "Electric power steering (secondary): a014 gate drive tx error";
CM_ SG_ 913 EPAS3S_a015_gateDriveEeprom "Electric power steering (secondary): a015 gate drive eeprom";
CM_ SG_ 913 EPAS3S_a016_phaseUhighUv "Electric power steering (secondary): a016 phase uhigh uv";
CM_ SG_ 913 EPAS3S_a017_phaseUlowUv "Electric power steering (secondary): a017 phase ulow uv";
CM_ SG_ 913 EPAS3S_a018_phaseVhighUv "Electric power steering (secondary): a018 phase vhigh uv";
CM_ SG_ 913 EPAS3S_a019_phaseVlowUv "Electric power steering (secondary): a019 phase vlow uv";
CM_ SG_ 913 EPAS3S_a020_phaseWhighUv "Electric power steering (secondary): a020 phase whigh uv";
CM_ SG_ 913 EPAS3S_a021_phaseWlowUv "Electric power steering (secondary): a021 phase wlow uv";
CM_ SG_ 913 EPAS3S_a022_phaseUhighOv "Electric power steering (secondary): a022 phase uhigh ov";
CM_ SG_ 913 EPAS3S_a023_phaseUlowOv "Electric power steering (secondary): a023 phase ulow ov";
CM_ SG_ 913 EPAS3S_a024_phaseVhighOv "Electric power steering (secondary): a024 phase vhigh ov";
CM_ SG_ 913 EPAS3S_a025_phaseVlowOv "Electric power steering (secondary): a025 phase vlow ov";
CM_ SG_ 913 EPAS3S_a026_phaseWhighOv "Electric power steering (secondary): a026 phase whigh ov";
CM_ SG_ 913 EPAS3S_a027_phaseWlowOv "Electric power steering (secondary): a027 phase wlow ov";
CM_ SG_ 913 EPAS3S_a028_phaseUbootUv "Electric power steering (secondary): a028 phase uboot uv";
CM_ SG_ 913 EPAS3S_a029_phaseVbootUv "Electric power steering (secondary): a029 phase vboot uv";
CM_ SG_ 913 EPAS3S_a030_phaseWbootUv "Electric power steering (secondary): a030 phase wboot uv";
CM_ SG_ 913 EPAS3S_a031_abnormalShutdown "Electric power steering (secondary): a031 abnormal shutdown";
CM_ SG_ 913 EPAS3S_a032_vRegOutputUv "Electric power steering (secondary): a032 v reg output uv";
CM_ SG_ 913 EPAS3S_a033_vRegOutputOv "Electric power steering (secondary): a033 v reg output ov";
CM_ SG_ 913 EPAS3S_a034_vRegError "Electric power steering (secondary): a034 v reg error";
CM_ SG_ 913 EPAS3S_a035_vbbSupplyUv "Electric power steering (secondary): a035 vbb supply uv";
CM_ SG_ 913 EPAS3S_a036_vbbSupplyOv "Electric power steering (secondary): a036 vbb supply ov";
CM_ SG_ 913 EPAS3S_a037_motPos1ParityError "Electric power steering (secondary): a037 mot pos1 parity error";
CM_ SG_ 913 EPAS3S_a038_motPos1Uv "Electric power steering (secondary): a038 mot pos1 uv";
CM_ SG_ 913 EPAS3S_a039_motPos1MagnetMia "Electric power steering (secondary): a039 mot pos1 magnet mia";
CM_ SG_ 913 EPAS3S_a040_motPos1LogicError "Electric power steering (secondary): a040 mot pos1 logic error";
CM_ SG_ 913 EPAS3S_a041_motPos1tempError "Electric power steering (secondary): a041 mot pos1temp error";
CM_ SG_ 913 EPAS3S_a042_motPos2ParityError "Electric power steering (secondary): a042 mot pos2 parity error";
CM_ SG_ 913 EPAS3S_a043_motPos2Uv "Electric power steering (secondary): a043 mot pos2 uv";
CM_ SG_ 913 EPAS3S_a044_motPos2MagnetMia "Electric power steering (secondary): a044 mot pos2 magnet mia";
CM_ SG_ 913 EPAS3S_a045_motPos2LogicError "Electric power steering (secondary): a045 mot pos2 logic error";
CM_ SG_ 913 EPAS3S_a046_motPos2tempError "Electric power steering (secondary): a046 mot pos2temp error";
CM_ SG_ 913 EPAS3S_a047_motPosCorrError "Electric power steering (secondary): a047 mot pos corr error";
CM_ SG_ 913 EPAS3S_a048_motPosCalError "Electric power steering (secondary): a048 mot pos cal error";
CM_ SG_ 913 EPAS3S_a049_piCtrlError "Electric power steering (secondary): a049 pi ctrl error";
CM_ SG_ 913 EPAS3S_a050_mcuSmuError "Electric power steering (secondary): a050 mcu smu error";
CM_ SG_ 913 EPAS3S_a051_mcuSupError "Electric power steering (secondary): a051 mcu sup error";
CM_ SG_ 913 EPAS3S_a052_intWatchdogError "Electric power steering (secondary): a052 int watchdog error";
CM_ SG_ 913 EPAS3S_a053_extWatchdogError "Electric power steering (secondary): a053 ext watchdog error";
CM_ SG_ 913 EPAS3S_a054_memoryProtectError "Electric power steering (secondary): a054 memory protect error";
CM_ SG_ 913 EPAS3S_a055_floatPointError "Electric power steering (secondary): a055 float point error";
CM_ SG_ 913 EPAS3S_a056_battUv "Electric power steering (secondary): a056 batt uv";
CM_ SG_ 913 EPAS3S_a057_battUvReduced "Electric power steering (secondary): a057 batt uv reduced";
CM_ SG_ 913 EPAS3S_a058_battOv "Electric power steering (secondary): a058 batt ov";
CM_ SG_ 913 EPAS3S_a059_battOvReduced "Electric power steering (secondary): a059 batt ov reduced";
CM_ SG_ 913 EPAS3S_a060_battBridgeDiff "Electric power steering (secondary): a060 batt bridge diff";
CM_ SG_ 913 EPAS3S_a061_bridgeUv "Electric power steering (secondary): a061 bridge uv";
CM_ SG_ 913 EPAS3S_a062_assistCorrError "Electric power steering (secondary): a062 assist corr error";
CM_ SG_ 913 EPAS3S_a063_dampCorrError "Electric power steering (secondary): a063 damp corr error";
CM_ SG_ 913 EPAS3S_a064_phaseCompCorrError "Electric power steering (secondary): a064 phase comp corr error";
CM_ SG_ 913 EPAS3S_a065_trqTarCorrError "Electric power steering (secondary): a065 trq tar corr error";
CM_ SG_ 913 EPAS3S_a066_returnCorrError "Electric power steering (secondary): a066 return corr error";
CM_ SG_ 913 EPAS3S_a067_yawDampCorrError "Electric power steering (secondary): a067 yaw damp corr error";
CM_ SG_ 913 EPAS3S_a068_hystCorrError "Electric power steering (secondary): a068 hyst corr error";
CM_ SG_ 913 EPAS3S_a069_eacCorrError "Electric power steering (secondary): a069 eac corr error";
CM_ SG_ 913 EPAS3S_a070_hodCorrError "Electric power steering (secondary): a070 hod corr error";
CM_ SG_ 913 EPAS3S_a071_vehSpdCorrError "Electric power steering (secondary): a071 veh spd corr error";
CM_ SG_ 913 EPAS3S_a072_motFeedFwdError "Electric power steering (secondary): a072 mot feed fwd error";
CM_ SG_ 913 EPAS3S_a073_motParEstError "Electric power steering (secondary): a073 mot par est error";
CM_ SG_ 913 EPAS3S_a074_overHeatProtect "Electric power steering (secondary): a074 over heat protect";
CM_ SG_ 913 EPAS3S_a075_fspPwrCut "Electric power steering (secondary): a075 fsp pwr cut";
CM_ SG_ 913 EPAS3S_a076_tempSensOutofRange "Electric power steering (secondary): a076 temp sens outof range";
CM_ SG_ 913 EPAS3S_a077_highSideFetError "Electric power steering (secondary): a077 high side fet error";
CM_ SG_ 913 EPAS3S_a078_phaseDisconnectError "Electric power steering (secondary): a078 phase disconnect error";
CM_ SG_ 913 EPAS3S_a079_backupCurrentPlaus "Electric power steering (secondary): a079 backup current plaus";
CM_ SG_ 913 EPAS3S_a080_ecuInitArbError "Electric power steering (secondary): a080 ecu init arb error";
CM_ SG_ 913 EPAS3S_a081_coggCompError "Electric power steering (secondary): a081 cogg comp error";
CM_ SG_ 913 EPAS3S_a082_polarityCalError "Electric power steering (secondary): a082 polarity cal error";
CM_ SG_ 913 EPAS3S_a083_crcMismatch "Electric power steering (secondary): a083 crc mismatch";
CM_ SG_ 913 EPAS3S_a084_eacCancelled "Electric power steering (secondary): a084 eac cancelled";
CM_ SG_ 913 EPAS3S_a085_canBusOff "Electric power steering (secondary): a085 can bus off";
CM_ SG_ 913 EPAS3S_a086_dasMia "Electric power steering (secondary): a086 das mia";
CM_ SG_ 913 EPAS3S_a087_dasCntError "Electric power steering (secondary): a087 das cnt error";
CM_ SG_ 913 EPAS3S_a088_dasCsError "Electric power steering (secondary): a088 das cs error";
CM_ SG_ 913 EPAS3S_a089_espWsMia "Electric power steering (secondary): a089 esp ws mia";
CM_ SG_ 913 EPAS3S_a090_espWsCntError "Electric power steering (secondary): a090 esp ws cnt error";
CM_ SG_ 913 EPAS3S_a091_espWsCsError "Electric power steering (secondary): a091 esp ws cs error";
CM_ SG_ 913 EPAS3S_a092_espWrMia "Electric power steering (secondary): a092 esp wr mia";
CM_ SG_ 913 EPAS3S_a093_espWrCntError "Electric power steering (secondary): a093 esp wr cnt error";
CM_ SG_ 913 EPAS3S_a094_espWrCsError "Electric power steering (secondary): a094 esp wr cs error";
CM_ SG_ 913 EPAS3S_a095_espWsStatus "Electric power steering (secondary): a095 esp ws status";
CM_ SG_ 913 EPAS3S_a096_rcmMia "Electric power steering (secondary): a096 rcm mia";
CM_ SG_ 913 EPAS3S_a097_rcmCntError "Electric power steering (secondary): a097 rcm cnt error";
CM_ SG_ 913 EPAS3S_a098_rcmCsError "Electric power steering (secondary): a098 rcm cs error";
CM_ SG_ 913 EPAS3S_a099_yawRateStatus "Electric power steering (secondary): a099 yaw rate status";
CM_ SG_ 913 EPAS3S_a100_diMia "Electric power steering (secondary): a100 di mia";
CM_ SG_ 913 EPAS3S_a101_diCntError "Electric power steering (secondary): a101 di cnt error";
CM_ SG_ 913 EPAS3S_a102_diCsError "Electric power steering (secondary): a102 di cs error";
CM_ SG_ 913 EPAS3S_a103_vcFrontMia "Electric power steering (secondary): a103 vc front mia";
CM_ SG_ 913 EPAS3S_a104_vcFrontCntError "Electric power steering (secondary): a104 vc front cnt error";
CM_ SG_ 913 EPAS3S_a105_vcFrontCsError "Electric power steering (secondary): a105 vc front cs error";
CM_ SG_ 913 EPAS3S_a106_vcFrontTempMia "Electric power steering (secondary): a106 vc front temp mia";
CM_ SG_ 913 EPAS3S_a107_uiTuneReqMia "Electric power steering (secondary): a107 ui tune req mia";
CM_ SG_ 913 EPAS3S_a108_uiTuneReqCntError "Electric power steering (secondary): a108 ui tune req cnt error";
CM_ SG_ 913 EPAS3S_a109_uiTuneReqCsError "Electric power steering (secondary): a109 ui tune req cs error";
CM_ SG_ 913 EPAS3S_a110_sasMia "Electric power steering (secondary): a110 sas mia";
CM_ SG_ 913 EPAS3S_a111_sasCntError "Electric power steering (secondary): a111 sas cnt error";
CM_ SG_ 913 EPAS3S_a112_sasCsError "Electric power steering (secondary): a112 sas cs error";
CM_ SG_ 913 EPAS3S_a113_sasStatusError "Electric power steering (secondary): a113 sas status error";
CM_ SG_ 913 EPAS3S_a114_gtwConfigMia "Electric power steering (secondary): a114 gtw config mia";
CM_ SG_ 913 EPAS3S_a115_ecuStatMia "Electric power steering (secondary): a115 ecu stat mia";
CM_ SG_ 913 EPAS3S_a116_ecuStatCntError "Electric power steering (secondary): a116 ecu stat cnt error";
CM_ SG_ 913 EPAS3S_a117_ecuStatCrcError "Electric power steering (secondary): a117 ecu stat crc error";
CM_ SG_ 913 EPAS3S_a118_privateBusOff "Electric power steering (secondary): a118 private bus off";
CM_ SG_ 913 EPAS3S_a119_pvtEcuStatMia "Electric power steering (secondary): a119 pvt ecu stat mia";
CM_ SG_ 913 EPAS3S_a120_pvtEcuStatCntError "Electric power steering (secondary): a120 pvt ecu stat cnt error";
CM_ SG_ 913 EPAS3S_a121_pvtEcuStatCrcError "Electric power steering (secondary): a121 pvt ecu stat crc error";
CM_ SG_ 913 EPAS3S_a122_olpActive "Electric power steering (secondary): a122 olp active";
CM_ SG_ 913 EPAS3S_a123_combEcu2StatFail "Electric power steering (secondary): a123 comb ecu2 stat fail";
CM_ SG_ 913 EPAS3S_a124_tempSensStuckInRange "Electric power steering (secondary): a124 temp sens stuck in range";
CM_ SG_ 913 EPAS3S_a125_trqSensTrimOutRange "Electric power steering (secondary): a125 trq sens trim out range";
CM_ SG_ 913 EPAS3S_a126_apsMia "Electric power steering (secondary): a126 aps mia";
CM_ SG_ 913 EPAS3S_a127_apsCntError "Electric power steering (secondary): a127 aps cnt error";
CM_ SG_ 913 EPAS3S_a128_apsCsError "Electric power steering (secondary): a128 aps cs error";
CM_ SG_ 913 EPAS3S_a129_combEcu1StatFail "Electric power steering (secondary): a129 comb ecu1 stat fail";
CM_ SG_ 913 EPAS3S_a130_sasOffsetNotCal "Electric power steering (secondary): a130 sas offset not cal";
CM_ SG_ 913 EPAS3S_a131_phaseFeedbackError "Electric power steering (secondary): a131 phase feedback error";
CM_ SG_ 913 EPAS3S_a132_motFeedFwdCounter25 "Electric power steering (secondary): a132 mot feed fwd counter25";
CM_ SG_ 913 EPAS3S_a133_motFeedFwdCounter50 "Electric power steering (secondary): a133 mot feed fwd counter50";
CM_ SG_ 913 EPAS3S_a134_motFeedFwdCounter85 "Electric power steering (secondary): a134 mot feed fwd counter85";
CM_ SG_ 913 EPAS3S_a135_piCtrlCounter25 "Electric power steering (secondary): a135 pi ctrl counter25";
CM_ SG_ 913 EPAS3S_a136_piCtrlCounter50 "Electric power steering (secondary): a136 pi ctrl counter50";
CM_ SG_ 913 EPAS3S_a137_piCtrlCounter85 "Electric power steering (secondary): a137 pi ctrl counter85";
CM_ SG_ 913 EPAS3S_a144_diSpdMia "Electric power steering (secondary): a144 di spd mia";
CM_ SG_ 913 EPAS3S_a145_diSpdCntError "Electric power steering (secondary): a145 di spd cnt error";
CM_ SG_ 913 EPAS3S_a146_diSpdCsError "Electric power steering (secondary): a146 di spd cs error";
CM_ SG_ 913 EPAS3S_a147_backupVehSpeed "Electric power steering (secondary): a147 backup veh speed";
CM_ SG_ 913 EPAS3S_a148_vMaxAssist "Electric power steering (secondary): a148 v max assist";
CM_ SG_ 913 EPAS3S_a149_currentSensPathSwitc "Electric power steering (secondary): a149 current sens path switch";
CM_ SG_ 913 EPAS3S_a150_currentSensOffsetDet "Electric power steering (secondary): a150 current sens offset detect";
CM_ SG_ 913 EPAS3S_a151_dcsCboot "Electric power steering (secondary): a151 dcs cboot";
CM_ SG_ 913 EPAS3S_a152_dcsDiagReg "Electric power steering (secondary): a152 dcs diag reg";
CM_ SG_ 913 EPAS3S_a153_dcsInitOffset "Electric power steering (secondary): a153 dcs init offset";
CM_ SG_ 913 EPAS3S_a154_assistTorqueDisabled "Electric power steering (secondary): a154 assist torque disabled";
CM_ SG_ 913 EPAS3S_a155_backupEacActive "Electric power steering (secondary): a155 backup eac active";
CM_ SG_ 913 EPAS3S_a156_angleSensorDivergenc "Electric power steering (secondary): a156 angle sensor divergence";
CM_ BO_ 882 "Electric power steering (secondary) message: sys status";
CM_ SG_ 882 EPAS3S_steeringRackForce "The real time, estimated force applied by the steering rack to the tie rods; raw 1023 = signal not available (SNA)";
CM_ SG_ 882 EPAS3S_steeringFault "Electric power steering (secondary): steering fault";
CM_ SG_ 882 EPAS3S_steeringReduced "Electric power steering (secondary): steering reduced";
CM_ SG_ 882 EPAS3S_internalSASQF "This signal identifies the validity of the EPAS3P_internalSAS signal.";
CM_ SG_ 882 EPAS3S_currentTuneMode "Electric power steering (secondary): current tune mode";
CM_ SG_ 882 EPAS3S_torsionBarTorque "The measurement of the steering wheel torque input. If the value is positive the steering wheel torque is applied in the clockwise direction; raw 4095 = signal not available (SNA)";
CM_ SG_ 882 EPAS3S_eacErrorCode "Electric power steering (secondary): eac error code; raw 15 = signal not available (SNA)";
CM_ SG_ 882 EPAS3S_internalSAS "The measurement of the steering wheel angle that is calculated by electronic power steering assist steering. Clockwise positive.";
CM_ SG_ 882 EPAS3S_handsOnLevel "Electric power steering (secondary): hands on level";
CM_ SG_ 882 EPAS3S_sysStatusCounter "Electric power steering (secondary): sys status counter";
CM_ SG_ 882 EPAS3S_tireIDActive "Electric power steering (secondary): tire ID active";
CM_ SG_ 882 EPAS3S_eacStatus "Electric power steering (secondary): eac status";
CM_ SG_ 882 EPAS3S_sysStatusChecksum "Electric power steering (secondary): sys status checksum";
CM_ BO_ 1848 "Electric power steering (secondary) message: uds response";
CM_ SG_ 1848 EPAS3S_udsResponseData "Electric power steering (secondary): uds response data";
CM_ BO_ 1427 "EPASTP ECU message: alert log";
CM_ SG_ 1427 EPASTP_alertID "EPASTP ECU: alert ID";
CM_ SG_ 1427 EPASTP_alertState "EPASTP ECU: alert state";
CM_ SG_ 1427 EPASTP_a001_debugInfo "EPASTP ECU: a001 debug info";
CM_ SG_ 1427 EPASTP_a002_debugInfo "EPASTP ECU: a002 debug info";
CM_ SG_ 1427 EPASTP_a003_debugInfo "EPASTP ECU: a003 debug info";
CM_ SG_ 1427 EPASTP_a004_debugInfo "EPASTP ECU: a004 debug info";
CM_ SG_ 1427 EPASTP_a005_debugInfo "EPASTP ECU: a005 debug info";
CM_ SG_ 1427 EPASTP_a006_debugInfo "EPASTP ECU: a006 debug info";
CM_ SG_ 1427 EPASTP_a007_debugInfo "EPASTP ECU: a007 debug info";
CM_ SG_ 1427 EPASTP_a009_debugInfo "EPASTP ECU: a009 debug info";
CM_ SG_ 1427 EPASTP_a010_debugInfo "EPASTP ECU: a010 debug info";
CM_ SG_ 1427 EPASTP_a011_debugInfo "EPASTP ECU: a011 debug info";
CM_ SG_ 1427 EPASTP_a012_debugInfo "EPASTP ECU: a012 debug info";
CM_ SG_ 1427 EPASTP_a013_debugInfo "EPASTP ECU: a013 debug info";
CM_ SG_ 1427 EPASTP_a014_debugInfo "EPASTP ECU: a014 debug info";
CM_ SG_ 1427 EPASTP_a015_debugInfo "EPASTP ECU: a015 debug info";
CM_ SG_ 1427 EPASTP_a016_debugInfo "EPASTP ECU: a016 debug info";
CM_ SG_ 1427 EPASTP_a017_debugInfo "EPASTP ECU: a017 debug info";
CM_ SG_ 1427 EPASTP_a018_debugInfo "EPASTP ECU: a018 debug info";
CM_ SG_ 1427 EPASTP_a019_debugInfo "EPASTP ECU: a019 debug info";
CM_ SG_ 1427 EPASTP_a020_debugInfo "EPASTP ECU: a020 debug info";
CM_ SG_ 1427 EPASTP_a021_debugInfo "EPASTP ECU: a021 debug info";
CM_ SG_ 1427 EPASTP_a022_debugInfo "EPASTP ECU: a022 debug info";
CM_ SG_ 1427 EPASTP_a023_debugInfo "EPASTP ECU: a023 debug info";
CM_ SG_ 1427 EPASTP_a024_debugInfo "EPASTP ECU: a024 debug info";
CM_ SG_ 1427 EPASTP_a025_debugInfo "EPASTP ECU: a025 debug info";
CM_ SG_ 1427 EPASTP_a026_debugInfo "EPASTP ECU: a026 debug info";
CM_ SG_ 1427 EPASTP_a027_debugInfo "EPASTP ECU: a027 debug info";
CM_ SG_ 1427 EPASTP_a028_debugInfo "EPASTP ECU: a028 debug info";
CM_ SG_ 1427 EPASTP_a029_debugInfo "EPASTP ECU: a029 debug info";
CM_ SG_ 1427 EPASTP_a030_debugInfo "EPASTP ECU: a030 debug info";
CM_ SG_ 1427 EPASTP_a031_debugInfo "EPASTP ECU: a031 debug info";
CM_ SG_ 1427 EPASTP_a032_debugInfo "EPASTP ECU: a032 debug info";
CM_ SG_ 1427 EPASTP_a033_debugInfo "EPASTP ECU: a033 debug info";
CM_ SG_ 1427 EPASTP_a034_debugInfo "EPASTP ECU: a034 debug info";
CM_ SG_ 1427 EPASTP_a035_debugInfo "EPASTP ECU: a035 debug info";
CM_ SG_ 1427 EPASTP_a036_debugInfo "EPASTP ECU: a036 debug info";
CM_ SG_ 1427 EPASTP_a037_debugInfo "EPASTP ECU: a037 debug info";
CM_ SG_ 1427 EPASTP_a038_debugInfo "EPASTP ECU: a038 debug info";
CM_ SG_ 1427 EPASTP_a039_debugInfo "EPASTP ECU: a039 debug info";
CM_ SG_ 1427 EPASTP_a040_debugInfo "EPASTP ECU: a040 debug info";
CM_ SG_ 1427 EPASTP_a041_debugInfo "EPASTP ECU: a041 debug info";
CM_ SG_ 1427 EPASTP_a042_debugInfo "EPASTP ECU: a042 debug info";
CM_ SG_ 1427 EPASTP_a043_debugInfo "EPASTP ECU: a043 debug info";
CM_ SG_ 1427 EPASTP_a044_debugInfo "EPASTP ECU: a044 debug info";
CM_ SG_ 1427 EPASTP_a045_debugInfo "EPASTP ECU: a045 debug info";
CM_ SG_ 1427 EPASTP_a046_debugInfo "EPASTP ECU: a046 debug info";
CM_ SG_ 1427 EPASTP_a047_debugInfo "EPASTP ECU: a047 debug info";
CM_ SG_ 1427 EPASTP_a048_debugInfo "EPASTP ECU: a048 debug info";
CM_ SG_ 1427 EPASTP_a049_debugInfo "EPASTP ECU: a049 debug info";
CM_ SG_ 1427 EPASTP_a050_debugInfo "EPASTP ECU: a050 debug info";
CM_ SG_ 1427 EPASTP_a051_debugInfo "EPASTP ECU: a051 debug info";
CM_ SG_ 1427 EPASTP_a052_debugInfo "EPASTP ECU: a052 debug info";
CM_ SG_ 1427 EPASTP_a053_debugInfo "EPASTP ECU: a053 debug info";
CM_ SG_ 1427 EPASTP_a054_debugInfo "EPASTP ECU: a054 debug info";
CM_ SG_ 1427 EPASTP_a055_debugInfo "EPASTP ECU: a055 debug info";
CM_ SG_ 1427 EPASTP_a056_debugInfo "EPASTP ECU: a056 debug info";
CM_ SG_ 1427 EPASTP_a057_debugInfo "EPASTP ECU: a057 debug info";
CM_ SG_ 1427 EPASTP_a058_debugInfo "EPASTP ECU: a058 debug info";
CM_ SG_ 1427 EPASTP_a059_debugInfo "EPASTP ECU: a059 debug info";
CM_ SG_ 1427 EPASTP_a060_debugInfo "EPASTP ECU: a060 debug info";
CM_ SG_ 1427 EPASTP_a061_debugInfo "EPASTP ECU: a061 debug info";
CM_ SG_ 1427 EPASTP_a062_debugInfo "EPASTP ECU: a062 debug info";
CM_ SG_ 1427 EPASTP_a063_debugInfo "EPASTP ECU: a063 debug info";
CM_ SG_ 1427 EPASTP_a064_debugInfo "EPASTP ECU: a064 debug info";
CM_ SG_ 1427 EPASTP_a065_debugInfo "EPASTP ECU: a065 debug info";
CM_ SG_ 1427 EPASTP_a066_debugInfo "EPASTP ECU: a066 debug info";
CM_ SG_ 1427 EPASTP_a067_debugInfo "EPASTP ECU: a067 debug info";
CM_ SG_ 1427 EPASTP_a068_debugInfo "EPASTP ECU: a068 debug info";
CM_ SG_ 1427 EPASTP_a069_debugInfo "EPASTP ECU: a069 debug info";
CM_ SG_ 1427 EPASTP_a070_debugInfo "EPASTP ECU: a070 debug info";
CM_ SG_ 1427 EPASTP_a071_debugInfo "EPASTP ECU: a071 debug info";
CM_ SG_ 1427 EPASTP_a072_debugInfo "EPASTP ECU: a072 debug info";
CM_ SG_ 1427 EPASTP_a073_debugInfo "EPASTP ECU: a073 debug info";
CM_ SG_ 1427 EPASTP_a074_debugInfo "EPASTP ECU: a074 debug info";
CM_ SG_ 1427 EPASTP_a075_debugInfo "EPASTP ECU: a075 debug info";
CM_ SG_ 1427 EPASTP_a076_debugInfo "EPASTP ECU: a076 debug info";
CM_ SG_ 1427 EPASTP_a077_debugInfo "EPASTP ECU: a077 debug info";
CM_ SG_ 1427 EPASTP_a078_debugInfo "EPASTP ECU: a078 debug info";
CM_ SG_ 1427 EPASTP_a079_debugInfo "EPASTP ECU: a079 debug info";
CM_ SG_ 1427 EPASTP_a080_debugInfo "EPASTP ECU: a080 debug info";
CM_ SG_ 1427 EPASTP_a081_debugInfo "EPASTP ECU: a081 debug info";
CM_ SG_ 1427 EPASTP_a082_debugInfo "EPASTP ECU: a082 debug info";
CM_ SG_ 1427 EPASTP_a083_debugInfo "EPASTP ECU: a083 debug info";
CM_ SG_ 1427 EPASTP_a084_debugInfo "EPASTP ECU: a084 debug info";
CM_ SG_ 1427 EPASTP_a085_debugInfo "EPASTP ECU: a085 debug info";
CM_ SG_ 1427 EPASTP_a086_debugInfo "EPASTP ECU: a086 debug info";
CM_ SG_ 1427 EPASTP_a087_debugInfo "EPASTP ECU: a087 debug info";
CM_ SG_ 1427 EPASTP_a088_debugInfo "EPASTP ECU: a088 debug info";
CM_ SG_ 1427 EPASTP_a089_debugInfo "EPASTP ECU: a089 debug info";
CM_ SG_ 1427 EPASTP_a090_debugInfo "EPASTP ECU: a090 debug info";
CM_ SG_ 1427 EPASTP_a091_debugInfo "EPASTP ECU: a091 debug info";
CM_ SG_ 1427 EPASTP_a092_debugInfo "EPASTP ECU: a092 debug info";
CM_ SG_ 1427 EPASTP_a093_debugInfo "EPASTP ECU: a093 debug info";
CM_ SG_ 1427 EPASTP_a094_debugInfo "EPASTP ECU: a094 debug info";
CM_ SG_ 1427 EPASTP_a095_debugInfo "EPASTP ECU: a095 debug info";
CM_ SG_ 1427 EPASTP_a096_debugInfo "EPASTP ECU: a096 debug info";
CM_ SG_ 1427 EPASTP_a097_debugInfo "EPASTP ECU: a097 debug info";
CM_ SG_ 1427 EPASTP_a098_debugInfo "EPASTP ECU: a098 debug info";
CM_ SG_ 1427 EPASTP_a099_debugInfo "EPASTP ECU: a099 debug info";
CM_ SG_ 1427 EPASTP_a100_debugInfo "EPASTP ECU: a100 debug info";
CM_ SG_ 1427 EPASTP_a101_debugInfo "EPASTP ECU: a101 debug info";
CM_ SG_ 1427 EPASTP_a102_debugInfo "EPASTP ECU: a102 debug info";
CM_ SG_ 1427 EPASTP_a103_debugInfo "EPASTP ECU: a103 debug info";
CM_ SG_ 1427 EPASTP_a104_debugInfo "EPASTP ECU: a104 debug info";
CM_ SG_ 1427 EPASTP_a105_debugInfo "EPASTP ECU: a105 debug info";
CM_ SG_ 1427 EPASTP_a106_debugInfo "EPASTP ECU: a106 debug info";
CM_ SG_ 1427 EPASTP_a107_debugInfo "EPASTP ECU: a107 debug info";
CM_ SG_ 1427 EPASTP_a108_debugInfo "EPASTP ECU: a108 debug info";
CM_ SG_ 1427 EPASTP_a109_debugInfo "EPASTP ECU: a109 debug info";
CM_ SG_ 1427 EPASTP_a110_debugInfo "EPASTP ECU: a110 debug info";
CM_ SG_ 1427 EPASTP_a111_debugInfo "EPASTP ECU: a111 debug info";
CM_ SG_ 1427 EPASTP_a112_debugInfo "EPASTP ECU: a112 debug info";
CM_ SG_ 1427 EPASTP_a113_debugInfo "EPASTP ECU: a113 debug info";
CM_ SG_ 1427 EPASTP_a114_debugInfo "EPASTP ECU: a114 debug info";
CM_ SG_ 1427 EPASTP_a115_debugInfo "EPASTP ECU: a115 debug info";
CM_ SG_ 1427 EPASTP_a116_debugInfo "EPASTP ECU: a116 debug info";
CM_ SG_ 1427 EPASTP_a117_debugInfo "EPASTP ECU: a117 debug info";
CM_ SG_ 1427 EPASTP_a118_debugInfo "EPASTP ECU: a118 debug info";
CM_ SG_ 1427 EPASTP_a119_debugInfo "EPASTP ECU: a119 debug info";
CM_ SG_ 1427 EPASTP_a120_debugInfo "EPASTP ECU: a120 debug info";
CM_ SG_ 1427 EPASTP_a121_debugInfo "EPASTP ECU: a121 debug info";
CM_ SG_ 1427 EPASTP_a122_debugInfo "EPASTP ECU: a122 debug info";
CM_ SG_ 1427 EPASTP_a123_debugInfo "EPASTP ECU: a123 debug info";
CM_ SG_ 1427 EPASTP_a124_debugInfo "EPASTP ECU: a124 debug info";
CM_ SG_ 1427 EPASTP_a125_debugInfo "EPASTP ECU: a125 debug info";
CM_ SG_ 1427 EPASTP_a126_debugInfo "EPASTP ECU: a126 debug info";
CM_ SG_ 1427 EPASTP_a127_debugInfo "EPASTP ECU: a127 debug info";
CM_ SG_ 1427 EPASTP_a128_debugInfo "EPASTP ECU: a128 debug info";
CM_ SG_ 1427 EPASTP_a129_debugInfo "EPASTP ECU: a129 debug info";
CM_ SG_ 1427 EPASTP_a130_debugInfo "EPASTP ECU: a130 debug info";
CM_ SG_ 1427 EPASTP_a131_debugInfo "EPASTP ECU: a131 debug info";
CM_ SG_ 1427 EPASTP_a132_debugInfo "EPASTP ECU: a132 debug info";
CM_ SG_ 1427 EPASTP_a133_debugInfo "EPASTP ECU: a133 debug info";
CM_ SG_ 1427 EPASTP_a134_debugInfo "EPASTP ECU: a134 debug info";
CM_ SG_ 1427 EPASTP_a135_debugInfo "EPASTP ECU: a135 debug info";
CM_ SG_ 1427 EPASTP_a136_debugInfo "EPASTP ECU: a136 debug info";
CM_ SG_ 1427 EPASTP_a137_debugInfo "EPASTP ECU: a137 debug info";
CM_ SG_ 1427 EPASTP_a138_debugInfo "EPASTP ECU: a138 debug info";
CM_ SG_ 1427 EPASTP_a139_debugInfo "EPASTP ECU: a139 debug info";
CM_ SG_ 1427 EPASTP_a140_debugInfo "EPASTP ECU: a140 debug info";
CM_ SG_ 1427 EPASTP_a141_debugInfo "EPASTP ECU: a141 debug info";
CM_ SG_ 1427 EPASTP_a142_debugInfo "EPASTP ECU: a142 debug info";
CM_ SG_ 1427 EPASTP_a143_debugInfo "EPASTP ECU: a143 debug info";
CM_ SG_ 1427 EPASTP_a144_debugInfo "EPASTP ECU: a144 debug info";
CM_ SG_ 1427 EPASTP_a145_debugInfo "EPASTP ECU: a145 debug info";
CM_ SG_ 1427 EPASTP_a146_debugInfo "EPASTP ECU: a146 debug info";
CM_ SG_ 1427 EPASTP_a147_debugInfo "EPASTP ECU: a147 debug info";
CM_ SG_ 1427 EPASTP_a148_debugInfo "EPASTP ECU: a148 debug info";
CM_ SG_ 1427 EPASTP_a149_debugInfo "EPASTP ECU: a149 debug info";
CM_ SG_ 1427 EPASTP_a150_debugInfo "EPASTP ECU: a150 debug info";
CM_ SG_ 1427 EPASTP_a152_debugInfo "EPASTP ECU: a152 debug info";
CM_ SG_ 1427 EPASTP_a153_debugInfo "EPASTP ECU: a153 debug info";
CM_ SG_ 1427 EPASTP_a154_debugInfo "EPASTP ECU: a154 debug info";
CM_ SG_ 1427 EPASTP_a155_debugInfo "EPASTP ECU: a155 debug info";
CM_ SG_ 1427 EPASTP_a156_debugInfo "EPASTP ECU: a156 debug info";
CM_ SG_ 1427 EPASTP_a157_debugInfo "EPASTP ECU: a157 debug info";
CM_ SG_ 1427 EPASTP_a158_debugInfo "EPASTP ECU: a158 debug info";
CM_ SG_ 1427 EPASTP_a159_debugInfo "EPASTP ECU: a159 debug info";
CM_ SG_ 1427 EPASTP_a160_debugInfo "EPASTP ECU: a160 debug info";
CM_ SG_ 1427 EPASTP_a161_debugInfo "EPASTP ECU: a161 debug info";
CM_ SG_ 1427 EPASTP_a162_debugInfo "EPASTP ECU: a162 debug info";
CM_ SG_ 1427 EPASTP_a163_debugInfo "EPASTP ECU: a163 debug info";
CM_ SG_ 1427 EPASTP_a164_debugInfo "EPASTP ECU: a164 debug info";
CM_ SG_ 1427 EPASTP_a165_debugInfo "EPASTP ECU: a165 debug info";
CM_ SG_ 1427 EPASTP_a166_debugInfo "EPASTP ECU: a166 debug info";
CM_ SG_ 1427 EPASTP_a167_debugInfo "EPASTP ECU: a167 debug info";
CM_ SG_ 1427 EPASTP_a168_debugInfo "EPASTP ECU: a168 debug info";
CM_ SG_ 1427 EPASTP_a169_debugInfo "EPASTP ECU: a169 debug info";
CM_ SG_ 1427 EPASTP_a170_debugInfo "EPASTP ECU: a170 debug info";
CM_ SG_ 1427 EPASTP_a171_debugInfo "EPASTP ECU: a171 debug info";
CM_ SG_ 1427 EPASTP_a172_debugInfo "EPASTP ECU: a172 debug info";
CM_ SG_ 1427 EPASTP_a173_debugInfo "EPASTP ECU: a173 debug info";
CM_ SG_ 1427 EPASTP_a174_debugInfo "EPASTP ECU: a174 debug info";
CM_ SG_ 1427 EPASTP_a175_debugInfo "EPASTP ECU: a175 debug info";
CM_ SG_ 1427 EPASTP_a176_debugInfo "EPASTP ECU: a176 debug info";
CM_ SG_ 1427 EPASTP_a177_debugInfo "EPASTP ECU: a177 debug info";
CM_ SG_ 1427 EPASTP_a178_debugInfo "EPASTP ECU: a178 debug info";
CM_ SG_ 1427 EPASTP_a179_debugInfo "EPASTP ECU: a179 debug info";
CM_ SG_ 1427 EPASTP_a180_debugInfo "EPASTP ECU: a180 debug info";
CM_ SG_ 1427 EPASTP_a181_debugInfo "EPASTP ECU: a181 debug info";
CM_ SG_ 1427 EPASTP_a182_debugInfo "EPASTP ECU: a182 debug info";
CM_ SG_ 1427 EPASTP_a183_debugInfo "EPASTP ECU: a183 debug info";
CM_ SG_ 1427 EPASTP_a184_debugInfo "EPASTP ECU: a184 debug info";
CM_ SG_ 1427 EPASTP_a185_debugInfo "EPASTP ECU: a185 debug info";
CM_ SG_ 1427 EPASTP_a186_debugInfo "EPASTP ECU: a186 debug info";
CM_ SG_ 1427 EPASTP_a188_debugInfo "EPASTP ECU: a188 debug info";
CM_ SG_ 1427 EPASTP_a189_debugInfo "EPASTP ECU: a189 debug info";
CM_ SG_ 1427 EPASTP_a190_debugInfo "EPASTP ECU: a190 debug info";
CM_ SG_ 1427 EPASTP_a191_debugInfo "EPASTP ECU: a191 debug info";
CM_ SG_ 1427 EPASTP_a192_debugInfo "EPASTP ECU: a192 debug info";
CM_ SG_ 1427 EPASTP_a193_debugInfo "EPASTP ECU: a193 debug info";
CM_ SG_ 1427 EPASTP_a194_debugInfo "EPASTP ECU: a194 debug info";
CM_ SG_ 1427 EPASTP_a195_debugInfo "EPASTP ECU: a195 debug info";
CM_ SG_ 1427 EPASTP_a196_debugInfo "EPASTP ECU: a196 debug info";
CM_ SG_ 1427 EPASTP_a197_debugInfo "EPASTP ECU: a197 debug info";
CM_ SG_ 1427 EPASTP_a198_debugInfo "EPASTP ECU: a198 debug info";
CM_ SG_ 1427 EPASTP_a199_debugInfo "EPASTP ECU: a199 debug info";
CM_ SG_ 1427 EPASTP_a200_debugInfo "EPASTP ECU: a200 debug info";
CM_ SG_ 1427 EPASTP_a201_debugInfo "EPASTP ECU: a201 debug info";
CM_ SG_ 1427 EPASTP_a202_debugInfo "EPASTP ECU: a202 debug info";
CM_ SG_ 1427 EPASTP_a203_debugInfo "EPASTP ECU: a203 debug info";
CM_ SG_ 1427 EPASTP_a204_debugInfo "EPASTP ECU: a204 debug info";
CM_ SG_ 1427 EPASTP_a205_debugInfo "EPASTP ECU: a205 debug info";
CM_ SG_ 1427 EPASTP_a206_debugInfo "EPASTP ECU: a206 debug info";
CM_ SG_ 1427 EPASTP_a207_debugInfo "EPASTP ECU: a207 debug info";
CM_ SG_ 1427 EPASTP_a208_debugInfo "EPASTP ECU: a208 debug info";
CM_ SG_ 1427 EPASTP_a209_debugInfo "EPASTP ECU: a209 debug info";
CM_ SG_ 1427 EPASTP_a210_debugInfo "EPASTP ECU: a210 debug info";
CM_ SG_ 1427 EPASTP_a211_debugInfo "EPASTP ECU: a211 debug info";
CM_ SG_ 1427 EPASTP_a212_debugInfo "EPASTP ECU: a212 debug info";
CM_ SG_ 1427 EPASTP_a213_debugInfo "EPASTP ECU: a213 debug info";
CM_ SG_ 1427 EPASTP_a214_debugInfo "EPASTP ECU: a214 debug info";
CM_ SG_ 1427 EPASTP_a215_debugInfo "EPASTP ECU: a215 debug info";
CM_ SG_ 1427 EPASTP_a216_debugInfo "EPASTP ECU: a216 debug info";
CM_ SG_ 1427 EPASTP_a217_debugInfo "EPASTP ECU: a217 debug info";
CM_ SG_ 1427 EPASTP_a218_debugInfo "EPASTP ECU: a218 debug info";
CM_ SG_ 1427 EPASTP_a219_debugInfo "EPASTP ECU: a219 debug info";
CM_ SG_ 1427 EPASTP_a221_debugInfo "EPASTP ECU: a221 debug info";
CM_ SG_ 1427 EPASTP_a222_debugInfo "EPASTP ECU: a222 debug info";
CM_ SG_ 1427 EPASTP_a223_debugInfo "EPASTP ECU: a223 debug info";
CM_ SG_ 1427 EPASTP_a224_debugInfo "EPASTP ECU: a224 debug info";
CM_ SG_ 1427 EPASTP_a225_debugInfo "EPASTP ECU: a225 debug info";
CM_ SG_ 1427 EPASTP_a226_debugInfo "EPASTP ECU: a226 debug info";
CM_ SG_ 1427 EPASTP_a227_debugInfo "EPASTP ECU: a227 debug info";
CM_ SG_ 1427 EPASTP_a228_debugInfo "EPASTP ECU: a228 debug info";
CM_ SG_ 1427 EPASTP_a229_debugInfo "EPASTP ECU: a229 debug info";
CM_ SG_ 1427 EPASTP_a230_debugInfo "EPASTP ECU: a230 debug info";
CM_ SG_ 1427 EPASTP_a231_debugInfo "EPASTP ECU: a231 debug info";
CM_ SG_ 1427 EPASTP_a232_debugInfo "EPASTP ECU: a232 debug info";
CM_ SG_ 1427 EPASTP_a233_debugInfo "EPASTP ECU: a233 debug info";
CM_ SG_ 1427 EPASTP_a234_debugInfo "EPASTP ECU: a234 debug info";
CM_ SG_ 1427 EPASTP_a235_debugInfo "EPASTP ECU: a235 debug info";
CM_ SG_ 1427 EPASTP_a236_debugInfo "EPASTP ECU: a236 debug info";
CM_ SG_ 1427 EPASTP_a237_debugInfo "EPASTP ECU: a237 debug info";
CM_ SG_ 1427 EPASTP_a238_debugInfo "EPASTP ECU: a238 debug info";
CM_ SG_ 1427 EPASTP_a239_debugInfo "EPASTP ECU: a239 debug info";
CM_ SG_ 1427 EPASTP_a240_debugInfo "EPASTP ECU: a240 debug info";
CM_ SG_ 1427 EPASTP_a241_debugInfo "EPASTP ECU: a241 debug info";
CM_ SG_ 1427 EPASTP_a242_debugInfo "EPASTP ECU: a242 debug info";
CM_ SG_ 1427 EPASTP_a243_debugInfo "EPASTP ECU: a243 debug info";
CM_ SG_ 1427 EPASTP_a244_debugInfo "EPASTP ECU: a244 debug info";
CM_ SG_ 1427 EPASTP_a245_debugInfo "EPASTP ECU: a245 debug info";
CM_ SG_ 1427 EPASTP_a246_debugInfo "EPASTP ECU: a246 debug info";
CM_ SG_ 1427 EPASTP_a247_debugInfo "EPASTP ECU: a247 debug info";
CM_ SG_ 1427 EPASTP_a248_debugInfo "EPASTP ECU: a248 debug info";
CM_ SG_ 1427 EPASTP_a249_debugInfo "EPASTP ECU: a249 debug info";
CM_ SG_ 1427 EPASTP_a250_debugInfo "EPASTP ECU: a250 debug info";
CM_ SG_ 1427 EPASTP_a251_debugInfo "EPASTP ECU: a251 debug info";
CM_ SG_ 1427 EPASTP_a252_debugInfo "EPASTP ECU: a252 debug info";
CM_ SG_ 1427 EPASTP_a253_debugInfo "EPASTP ECU: a253 debug info";
CM_ SG_ 1427 EPASTP_a254_debugInfo "EPASTP ECU: a254 debug info";
CM_ SG_ 1427 EPASTP_a255_debugInfo "EPASTP ECU: a255 debug info";
CM_ SG_ 1427 EPASTP_a256_debugInfo "EPASTP ECU: a256 debug info";
CM_ SG_ 1427 EPASTP_a257_debugInfo "EPASTP ECU: a257 debug info";
CM_ SG_ 1427 EPASTP_a258_debugInfo "EPASTP ECU: a258 debug info";
CM_ SG_ 1427 EPASTP_a259_debugInfo "EPASTP ECU: a259 debug info";
CM_ SG_ 1427 EPASTP_a260_debugInfo "EPASTP ECU: a260 debug info";
CM_ SG_ 1427 EPASTP_a261_debugInfo "EPASTP ECU: a261 debug info";
CM_ SG_ 1427 EPASTP_a262_debugInfo "EPASTP ECU: a262 debug info";
CM_ SG_ 1427 EPASTP_a263_debugInfo "EPASTP ECU: a263 debug info";
CM_ SG_ 1427 EPASTP_a264_degradedECU "EPASTP ECU: a264 degraded ECU";
CM_ SG_ 1427 EPASTP_a264_vehicleSpeed "EPASTP ECU: a264 vehicle speed";
CM_ SG_ 1427 EPASTP_a264_powerRatio "EPASTP ECU: a264 power ratio";
CM_ SG_ 1427 EPASTP_a264_ownSideDegradationRe "EPASTP ECU: a264 own side degradation reason";
CM_ SG_ 1427 EPASTP_a264_otherSideDegradation "EPASTP ECU: a264 other side degradation reason";
CM_ SG_ 1427 EPASTP_a265_degradedECU "EPASTP ECU: a265 degraded ECU";
CM_ SG_ 1427 EPASTP_a265_vehicleSpeed "EPASTP ECU: a265 vehicle speed";
CM_ SG_ 1427 EPASTP_a265_rawMcuTemperature "EPASTP ECU: a265 raw mcu temperature";
CM_ SG_ 1427 EPASTP_a265_degradedCurrentLimit "EPASTP ECU: a265 degraded current limit";
CM_ SG_ 1427 EPASTP_a266_cdpAssistFactor "EPASTP ECU: a266 cdp assist factor";
CM_ SG_ 1427 EPASTP_a266_vehicleSpeed "EPASTP ECU: a266 vehicle speed";
CM_ SG_ 1427 EPASTP_a267_vehicleSpeed "EPASTP ECU: a267 vehicle speed";
CM_ SG_ 1427 EPASTP_a267_velocityEstimatorSta "EPASTP ECU: a267 velocity estimator state";
CM_ SG_ 1427 EPASTP_a269_vehicleSpeed "EPASTP ECU: a269 vehicle speed";
CM_ SG_ 1427 EPASTP_a270_debugInfo "EPASTP ECU: a270 debug info";
BA_DEF_ BO_ "GenMsgCycleTime" INT 0 3600000;
BA_DEF_ BO_ "GenMsgSendType" ENUM "Cyclic","NotUsed","NotUsed","NotUsed","NotUsed","NotUsed","NotUsed","IfActive","NoMsgSendType","NotUsed";
BA_DEF_ BO_ "VFrameFormat" ENUM "StandardCAN","ExtendedCAN","reserved","J1939PG","reserved","reserved","reserved","reserved","reserved","reserved","reserved","reserved","reserved","reserved","StandardCAN_FD","ExtendedCAN_FD";
BA_DEF_ BO_ "CANFD_BRS" ENUM "0","1";
BA_DEF_ SG_ "GenSigSNA" STRING;
BA_DEF_ SG_ "SystemSignalLongSymbol" STRING;
BA_DEF_ SG_ "Confidence" ENUM "validated","plausible","layout-only","contradicted";
BA_DEF_DEF_ "GenMsgCycleTime" 0;
BA_DEF_DEF_ "GenMsgSendType" "NoMsgSendType";
BA_DEF_DEF_ "VFrameFormat" "StandardCAN";
BA_DEF_DEF_ "CANFD_BRS" "1";
BA_DEF_DEF_ "GenSigSNA" "";
BA_DEF_DEF_ "SystemSignalLongSymbol" "";
BA_DEF_DEF_ "Confidence" "layout-only";
BA_ "GenMsgCycleTime" BO_ 999 1000;
BA_ "GenMsgSendType" BO_ 999 0;
BA_ "GenMsgCycleTime" BO_ 2036 1000;
BA_ "GenMsgSendType" BO_ 2036 0;
BA_ "GenMsgCycleTime" BO_ 883 10;
BA_ "GenMsgSendType" BO_ 883 0;
BA_ "GenMsgCycleTime" BO_ 913 1000;
BA_ "GenMsgSendType" BO_ 913 0;
BA_ "GenMsgCycleTime" BO_ 882 10;
BA_ "GenMsgSendType" BO_ 882 0;
BA_ "Confidence" SG_ 999 DPB_matrixIndex 1;
BA_ "SystemSignalLongSymbol" SG_ 999 DPB_a001_pPlungerSensorOffsetHig "DPB_a001_pPlungerSensorOffsetHigh";
BA_ "SystemSignalLongSymbol" SG_ 999 DPB_a018_largeLeakageDetectedGoo "DPB_a018_largeLeakageDetectedGoodCheck";
BA_ "SystemSignalLongSymbol" SG_ 999 DPB_a023_initialPlungerCheckFail "DPB_a023_initialPlungerCheckFailed";
BA_ "SystemSignalLongSymbol" SG_ 999 DPB_a035_PDURouterinitialization "DPB_a035_PDURouterinitializationFailed";
BA_ "SystemSignalLongSymbol" SG_ 999 DPB_a036_lossOfPDUInstanceDetect "DPB_a036_lossOfPDUInstanceDetected";
BA_ "SystemSignalLongSymbol" SG_ 999 DPB_a038_plungerCircuitPressHigh "DPB_a038_plungerCircuitPressHighGoodCheck";
BA_ "SystemSignalLongSymbol" SG_ 999 DPB_a040_plungerCircuitPressLowG "DPB_a040_plungerCircuitPressLowGoodCheck";
BA_ "SystemSignalLongSymbol" SG_ 999 DPB_a042_motorLoadPressImplausib "DPB_a042_motorLoadPressImplausible";
BA_ "SystemSignalLongSymbol" SG_ 999 DPB_a047_pPlungerPlausCheckFailu "DPB_a047_pPlungerPlausCheckFailure";
BA_ "SystemSignalLongSymbol" SG_ 999 DPB_a053_hydraulicAssemblyModeAc "DPB_a053_hydraulicAssemblyModeActive";
BA_ "SystemSignalLongSymbol" SG_ 999 DPB_a055_unsupportedSeriesHWDete "DPB_a055_unsupportedSeriesHWDetected";
BA_ "SystemSignalLongSymbol" SG_ 999 DPB_a085_infoFailureWrongCUBASHa "DPB_a085_infoFailureWrongCUBASHandlingDetected";
BA_ "SystemSignalLongSymbol" SG_ 999 DPB_a086_diagHydProtectionPressF "DPB_a086_diagHydProtectionPressFault";
BA_ "SystemSignalLongSymbol" SG_ 999 DPB_a087_diagHydProtectionVlvFau "DPB_a087_diagHydProtectionVlvFault";
BA_ "SystemSignalLongSymbol" SG_ 999 DPB_a111_hydraulicHardUndervolta "DPB_a111_hydraulicHardUndervoltage";
BA_ "SystemSignalLongSymbol" SG_ 999 DPB_a127_hydraulicAsicShortCircu "DPB_a127_hydraulicAsicShortCircuit";
BA_ "SystemSignalLongSymbol" SG_ 999 DPB_a129_AsicTrimmingNotComplete "DPB_a129_AsicTrimmingNotCompleted";
BA_ "SystemSignalLongSymbol" SG_ 999 DPB_a131_ASICOvercurrentOnGPIO25 "DPB_a131_ASICOvercurrentOnGPIO250_1";
BA_ "SystemSignalLongSymbol" SG_ 999 DPB_a132_ASICOvercurrentOnGPIO25 "DPB_a132_ASICOvercurrentOnGPIO250_2";
BA_ "SystemSignalLongSymbol" SG_ 999 DPB_a133_ASICOvercurrentOnGPIO50 "DPB_a133_ASICOvercurrentOnGPIO50_1";
BA_ "SystemSignalLongSymbol" SG_ 999 DPB_a134_ASICOvercurrentOnGPIO50 "DPB_a134_ASICOvercurrentOnGPIO50_2";
BA_ "SystemSignalLongSymbol" SG_ 999 DPB_a135_ASICOvercurrentOnGPIO50 "DPB_a135_ASICOvercurrentOnGPIO50_3";
BA_ "SystemSignalLongSymbol" SG_ 999 DPB_a136_ASICOvercurrentOnGPIO50 "DPB_a136_ASICOvercurrentOnGPIO50_4";
BA_ "SystemSignalLongSymbol" SG_ 999 DPB_a139_DIchassisControlChecksu "DPB_a139_DIchassisControlChecksum";
BA_ "SystemSignalLongSymbol" SG_ 999 DPB_a191_VCLEFTepbmStatusChecksu "DPB_a191_VCLEFTepbmStatusChecksum";
BA_ "SystemSignalLongSymbol" SG_ 999 DPB_a194_VCRIGHTepbmStatusCounte "DPB_a194_VCRIGHTepbmStatusCounter";
BA_ "SystemSignalLongSymbol" SG_ 999 DPB_a195_VCRIGHTepbmStatusChecks "DPB_a195_VCRIGHTepbmStatusChecksum";
BA_ "SystemSignalLongSymbol" SG_ 999 DPB_a197_VCRIGHTepbmStatusTimeou "DPB_a197_VCRIGHTepbmStatusTimeout";
BA_ "SystemSignalLongSymbol" SG_ 999 DPB_a200_ESPRunoutSupportNotAvai "DPB_a200_ESPRunoutSupportNotAvailable";
BA_ "SystemSignalLongSymbol" SG_ 999 DPB_a202_vehicleStandstillQFault "DPB_a202_vehicleStandstillQFaulty";
BA_ "SystemSignalLongSymbol" SG_ 999 DPB_a220_excessiveBoostWakeupsDe "DPB_a220_excessiveBoostWakeupsDetected";
BA_ "SystemSignalLongSymbol" SG_ 999 DPB_a222_excessiveEcuResetsDetec "DPB_a222_excessiveEcuResetsDetected";
BA_ "SystemSignalLongSymbol" SG_ 999 DPB_a242_uCSafetyNotificationGRA "DPB_a242_uCSafetyNotificationGRAM";
BA_ "SystemSignalLongSymbol" SG_ 999 DPB_a256_valveRelayActuationFaul "DPB_a256_valveRelayActuationFault";
BA_ "SystemSignalLongSymbol" SG_ 999 DPB_a259_valveRelayTestUndervolt "DPB_a259_valveRelayTestUndervoltage";
BA_ "SystemSignalLongSymbol" SG_ 999 DPB_a260_valveRelaySafetySwitchF "DPB_a260_valveRelaySafetySwitchFault";
BA_ "SystemSignalLongSymbol" SG_ 999 DPB_a292_CBDS_fillBufferThreshol "DPB_a292_CBDS_fillBufferThreshold";
BA_ "SystemSignalLongSymbol" SG_ 999 DPB_a298_RunningActiveSystemTest "DPB_a298_RunningActiveSystemTests";
BA_ "SystemSignalLongSymbol" SG_ 999 DPB_a303_actuatingDIFullTorqueCm "DPB_a303_actuatingDIFullTorqueCmd";
BA_ "SystemSignalLongSymbol" SG_ 999 DPB_a305_DIbrakeTorqueCommandAnd "DPB_a305_DIbrakeTorqueCommandAndFlagMismatch";
BA_ "SystemSignalLongSymbol" SG_ 999 DPB_a306_actuatorFallbackBasicMa "DPB_a306_actuatorFallbackBasicMap";
BA_ "SystemSignalLongSymbol" SG_ 999 DPB_a308_hydraulicPushthroughAct "DPB_a308_hydraulicPushthroughActive";
BA_ "SystemSignalLongSymbol" SG_ 999 DPB_a312_cyclicVolumeCheckDisabl "DPB_a312_cyclicVolumeCheckDisabled";
BA_ "SystemSignalLongSymbol" SG_ 999 DPB_a313_qualifiedBrakeEventDete "DPB_a313_qualifiedBrakeEventDetected";
BA_ "Confidence" SG_ 1426 EPAS3P_alertID 1;
BA_ "Confidence" SG_ 1426 EPAS3P_alertState 1;
BA_ "Confidence" SG_ 1426 EPAS3P_a147_transitionReason 1;
BA_ "Confidence" SG_ 1426 EPAS3P_a148_vehicleSpeed 1;
BA_ "Confidence" SG_ 1426 EPAS3P_a149_pcbTemp 1;
BA_ "Confidence" SG_ 1426 EPAS3P_a150_pcbTemp 1;
BA_ "Confidence" SG_ 1426 EPAS3P_a150_phaUMainPathCalcDiff 1;
BA_ "Confidence" SG_ 1426 EPAS3P_a150_phaVMainPathCalcDiff 1;
BA_ "SystemSignalLongSymbol" SG_ 1426 EPAS3P_a150_otherECUAssistStatus "EPAS3P_a150_otherECUAssistStatusFlag";
BA_ "Confidence" SG_ 1426 EPAS3P_a151_dcsVBridge 1;
BA_ "Confidence" SG_ 1426 EPAS3P_a151_dcsMainChannelA 1;
BA_ "Confidence" SG_ 1426 EPAS3P_a151_dcsMainChannelB 1;
BA_ "Confidence" SG_ 1426 EPAS3P_a151_dcsOffsetA 1;
BA_ "Confidence" SG_ 1426 EPAS3P_a151_dcsOffsetB 1;
BA_ "Confidence" SG_ 1426 EPAS3P_a152_dcsVBridge 1;
BA_ "Confidence" SG_ 1426 EPAS3P_a152_dcsModIndex 1;
BA_ "Confidence" SG_ 1426 EPAS3P_a152_dcsMainPathErrReg 1;
BA_ "Confidence" SG_ 1426 EPAS3P_a152_dcsTubErrReg 1;
BA_ "Confidence" SG_ 1426 EPAS3P_a152_dcsErrSumReg 1;
BA_ "Confidence" SG_ 1426 EPAS3P_a152_dcsVbusDiagPathErrRe 1;
BA_ "SystemSignalLongSymbol" SG_ 1426 EPAS3P_a152_dcsVbusDiagPathErrRe "EPAS3P_a152_dcsVbusDiagPathErrReg";
BA_ "Confidence" SG_ 1426 EPAS3P_a154_vehicleSpeed 1;
BA_ "Confidence" SG_ 1426 EPAS3P_a155_vehicleSpeed 1;
BA_ "Confidence" SG_ 1426 EPAS3P_a156_vehicleSpeed 1;
BA_ "Confidence" SG_ 2036 EPAS3P_matrixIndex 1;
BA_ "SystemSignalLongSymbol" SG_ 2036 EPAS3P_a149_currentSensPathSwitc "EPAS3P_a149_currentSensPathSwitch";
BA_ "SystemSignalLongSymbol" SG_ 2036 EPAS3P_a150_currentSensOffsetDet "EPAS3P_a150_currentSensOffsetDetect";
BA_ "SystemSignalLongSymbol" SG_ 2036 EPAS3P_a156_angleSensorDivergenc "EPAS3P_a156_angleSensorDivergence";
BA_ "Confidence" SG_ 883 EPAS3P_steeringRackForce 1;
BA_ "GenSigSNA" SG_ 883 EPAS3P_steeringRackForce "1023";
BA_ "Confidence" SG_ 883 EPAS3P_steeringFault 1;
BA_ "Confidence" SG_ 883 EPAS3P_steeringReduced 1;
BA_ "Confidence" SG_ 883 EPAS3P_internalSASQF 1;
BA_ "Confidence" SG_ 883 EPAS3P_currentTuneMode 1;
BA_ "Confidence" SG_ 883 EPAS3P_torsionBarTorque 1;
BA_ "GenSigSNA" SG_ 883 EPAS3P_torsionBarTorque "4095";
BA_ "Confidence" SG_ 883 EPAS3P_eacErrorCode 1;
BA_ "GenSigSNA" SG_ 883 EPAS3P_eacErrorCode "15";
BA_ "Confidence" SG_ 883 EPAS3P_internalSAS 1;
BA_ "Confidence" SG_ 883 EPAS3P_handsOnLevel 1;
BA_ "Confidence" SG_ 883 EPAS3P_eacStatus 1;
BA_ "Confidence" SG_ 1592 EPAS3P_udsResponseDataCH 1;
BA_ "Confidence" SG_ 1425 EPAS3S_alertID 1;
BA_ "Confidence" SG_ 1425 EPAS3S_alertState 1;
BA_ "Confidence" SG_ 1425 EPAS3S_a147_transitionReason 1;
BA_ "Confidence" SG_ 1425 EPAS3S_a148_vehicleSpeed 1;
BA_ "Confidence" SG_ 1425 EPAS3S_a149_pcbTemp 1;
BA_ "Confidence" SG_ 1425 EPAS3S_a150_pcbTemp 1;
BA_ "Confidence" SG_ 1425 EPAS3S_a150_phaUMainPathCalcDiff 1;
BA_ "Confidence" SG_ 1425 EPAS3S_a150_phaVMainPathCalcDiff 1;
BA_ "SystemSignalLongSymbol" SG_ 1425 EPAS3S_a150_otherECUAssistStatus "EPAS3S_a150_otherECUAssistStatusFlag";
BA_ "Confidence" SG_ 1425 EPAS3S_a151_dcsVBridge 1;
BA_ "Confidence" SG_ 1425 EPAS3S_a151_dcsMainChannelA 1;
BA_ "Confidence" SG_ 1425 EPAS3S_a151_dcsMainChannelB 1;
BA_ "Confidence" SG_ 1425 EPAS3S_a151_dcsOffsetA 1;
BA_ "Confidence" SG_ 1425 EPAS3S_a151_dcsOffsetB 1;
BA_ "Confidence" SG_ 1425 EPAS3S_a152_dcsVBridge 1;
BA_ "Confidence" SG_ 1425 EPAS3S_a152_dcsModIndex 1;
BA_ "Confidence" SG_ 1425 EPAS3S_a152_dcsMainPathErrReg 1;
BA_ "Confidence" SG_ 1425 EPAS3S_a152_dcsTubErrReg 1;
BA_ "Confidence" SG_ 1425 EPAS3S_a152_dcsErrSumReg 1;
BA_ "Confidence" SG_ 1425 EPAS3S_a152_dcsVbusDiagPathErrRe 1;
BA_ "SystemSignalLongSymbol" SG_ 1425 EPAS3S_a152_dcsVbusDiagPathErrRe "EPAS3S_a152_dcsVbusDiagPathErrReg";
BA_ "Confidence" SG_ 1425 EPAS3S_a154_vehicleSpeed 1;
BA_ "Confidence" SG_ 1425 EPAS3S_a155_vehicleSpeed 1;
BA_ "Confidence" SG_ 1425 EPAS3S_a156_vehicleSpeed 1;
BA_ "Confidence" SG_ 913 EPAS3S_matrixIndex 1;
BA_ "SystemSignalLongSymbol" SG_ 913 EPAS3S_a149_currentSensPathSwitc "EPAS3S_a149_currentSensPathSwitch";
BA_ "SystemSignalLongSymbol" SG_ 913 EPAS3S_a150_currentSensOffsetDet "EPAS3S_a150_currentSensOffsetDetect";
BA_ "SystemSignalLongSymbol" SG_ 913 EPAS3S_a156_angleSensorDivergenc "EPAS3S_a156_angleSensorDivergence";
BA_ "Confidence" SG_ 882 EPAS3S_steeringRackForce 1;
BA_ "GenSigSNA" SG_ 882 EPAS3S_steeringRackForce "1023";
BA_ "Confidence" SG_ 882 EPAS3S_steeringFault 1;
BA_ "Confidence" SG_ 882 EPAS3S_steeringReduced 1;
BA_ "Confidence" SG_ 882 EPAS3S_internalSASQF 1;
BA_ "Confidence" SG_ 882 EPAS3S_currentTuneMode 1;
BA_ "Confidence" SG_ 882 EPAS3S_torsionBarTorque 1;
BA_ "GenSigSNA" SG_ 882 EPAS3S_torsionBarTorque "4095";
BA_ "Confidence" SG_ 882 EPAS3S_eacErrorCode 1;
BA_ "GenSigSNA" SG_ 882 EPAS3S_eacErrorCode "15";
BA_ "Confidence" SG_ 882 EPAS3S_internalSAS 1;
BA_ "Confidence" SG_ 882 EPAS3S_handsOnLevel 1;
BA_ "Confidence" SG_ 882 EPAS3S_eacStatus 1;
BA_ "Confidence" SG_ 1848 EPAS3S_udsResponseData 1;
BA_ "Confidence" SG_ 1427 EPASTP_alertID 1;
BA_ "Confidence" SG_ 1427 EPASTP_alertState 1;
BA_ "Confidence" SG_ 1427 EPASTP_a264_degradedECU 1;
BA_ "Confidence" SG_ 1427 EPASTP_a264_vehicleSpeed 1;
BA_ "Confidence" SG_ 1427 EPASTP_a264_powerRatio 1;
BA_ "Confidence" SG_ 1427 EPASTP_a264_ownSideDegradationRe 1;
BA_ "SystemSignalLongSymbol" SG_ 1427 EPASTP_a264_ownSideDegradationRe "EPASTP_a264_ownSideDegradationReason";
BA_ "Confidence" SG_ 1427 EPASTP_a264_otherSideDegradation 1;
BA_ "SystemSignalLongSymbol" SG_ 1427 EPASTP_a264_otherSideDegradation "EPASTP_a264_otherSideDegradationReason";
BA_ "Confidence" SG_ 1427 EPASTP_a265_degradedECU 1;
BA_ "Confidence" SG_ 1427 EPASTP_a265_vehicleSpeed 1;
BA_ "Confidence" SG_ 1427 EPASTP_a265_rawMcuTemperature 1;
BA_ "Confidence" SG_ 1427 EPASTP_a265_degradedCurrentLimit 1;
BA_ "Confidence" SG_ 1427 EPASTP_a266_cdpAssistFactor 1;
BA_ "Confidence" SG_ 1427 EPASTP_a266_vehicleSpeed 1;
BA_ "Confidence" SG_ 1427 EPASTP_a267_vehicleSpeed 1;
BA_ "Confidence" SG_ 1427 EPASTP_a267_velocityEstimatorSta 1;
BA_ "SystemSignalLongSymbol" SG_ 1427 EPASTP_a267_velocityEstimatorSta "EPASTP_a267_velocityEstimatorState";
BA_ "Confidence" SG_ 1427 EPASTP_a269_vehicleSpeed 1;
VAL_ 999 DPB_matrixIndex 5 "AlertMatrix5" 4 "AlertMatrix4" 3 "AlertMatrix3" 2 "AlertMatrix2" 1 "AlertMatrix1" 0 "AlertMatrix0" ;
VAL_ 1426 EPAS3P_alertID 156 "a156_angleSensorDivergence" 155 "a155_backupEacActive" 154 "a154_assistTorqueDisabled" 153 "a153_dcsInitOffset" 152 "a152_dcsDiagReg" 151 "a151_dcsCboot" 150 "a150_currentSensOffsetDetect" 149 "a149_currentSensPathSwitch" 148 "a148_vMaxAssist" 147 "a147_backupVehSpeed" 146 "a146_diSpdCsError" 145 "a145_diSpdCntError" 144 "a144_diSpdMia" 137 "a137_piCtrlCounter85" 136 "a136_piCtrlCounter50" 135 "a135_piCtrlCounter25" 134 "a134_motFeedFwdCounter85" 133 "a133_motFeedFwdCounter50" 132 "a132_motFeedFwdCounter25" 131 "a131_phaseFeedbackError" 130 "a130_sasOffsetNotCal" 129 "a129_combEcu1StatFail" 128 "a128_apsCsError" 127 "a127_apsCntError" 126 "a126_apsMia" 125 "a125_trqSensTrimOutRange" 124 "a124_tempSensStuckInRange" 123 "a123_combEcu2StatFail" 122 "a122_olpActive" 121 "a121_pvtEcuStatCrcError" 120 "a120_pvtEcuStatCntError" 119 "a119_pvtEcuStatMia" 118 "a118_privateBusOff" 117 "a117_ecuStatCrcError" 116 "a116_ecuStatCntError" 115 "a115_ecuStatMia" 114 "a114_gtwConfigMia" 113 "a113_sasStatusError" 112 "a112_sasCsError" 111 "a111_sasCntError" 110 "a110_sasMia" 109 "a109_uiTuneReqCsError" 108 "a108_uiTuneReqCntError" 107 "a107_uiTuneReqMia" 106 "a106_vcFrontTempMia" 105 "a105_vcFrontCsError" 104 "a104_vcFrontCntError" 103 "a103_vcFrontMia" 102 "a102_diCsError" 101 "a101_diCntError" 100 "a100_diMia" 99 "a099_yawRateStatus" 98 "a098_rcmCsError" 97 "a097_rcmCntError" 96 "a096_rcmMia" 95 "a095_espWsStatus" 94 "a094_espWrCsError" 93 "a093_espWrCntError" 92 "a092_espWrMia" 91 "a091_espWsCsError" 90 "a090_espWsCntError" 89 "a089_espWsMia" 88 "a088_dasCsError" 87 "a087_dasCntError" 86 "a086_dasMia" 85 "a085_canBusOff" 84 "a084_eacCancelled" 83 "a083_crcMismatch" 82 "a082_polarityCalError" 81 "a081_coggCompError" 80 "a080_ecuInitArbError" 79 "a079_backupCurrentPlaus" 78 "a078_phaseDisconnectError" 77 "a077_highSideFetError" 76 "a076_tempSensOutofRange" 75 "a075_fspPwrCut" 74 "a074_overHeatProtect" 73 "a073_motParEstError" 72 "a072_motFeedFwdError" 71 "a071_vehSpdCorrError" 70 "a070_hodCorrError" 69 "a069_eacCorrError" 68 "a068_hystCorrError" 67 "a067_yawDampCorrError" 66 "a066_returnCorrError" 65 "a065_trqTarCorrError" 64 "a064_phaseCompCorrError" 63 "a063_dampCorrError" 62 "a062_assistCorrError" 61 "a061_bridgeUv" 60 "a060_battBridgeDiff" 59 "a059_battOvReduced" 58 "a058_battOv" 57 "a057_battUvReduced" 56 "a056_battUv" 55 "a055_floatPointError" 54 "a054_memoryProtectError" 53 "a053_extWatchdogError" 52 "a052_intWatchdogError" 51 "a051_mcuSupError" 50 "a050_mcuSmuError" 49 "a049_piCtrlError" 48 "a048_motPosCalError" 47 "a047_motPosCorrError" 46 "a046_motPos2tempError" 45 "a045_motPos2LogicError" 44 "a044_motPos2MagnetMia" 43 "a043_motPos2Uv" 42 "a042_motPos2ParityError" 41 "a041_motPos1tempError" 40 "a040_motPos1LogicError" 39 "a039_motPos1MagnetMia" 38 "a038_motPos1Uv" 37 "a037_motPos1ParityError" 36 "a036_vbbSupplyOv" 35 "a035_vbbSupplyUv" 34 "a034_vRegError" 33 "a033_vRegOutputOv" 32 "a032_vRegOutputUv" 31 "a031_abnormalShutdown" 30 "a030_phaseWbootUv" 29 "a029_phaseVbootUv" 28 "a028_phaseUbootUv" 27 "a027_phaseWlowOv" 26 "a026_phaseWhighOv" 25 "a025_phaseVlowOv" 24 "a024_phaseVhighOv" 23 "a023_phaseUlowOv" 22 "a022_phaseUhighOv" 21 "a021_phaseWlowUv" 20 "a020_phaseWhighUv" 19 "a019_phaseVlowUv" 18 "a018_phaseVhighUv" 17 "a017_phaseUlowUv" 16 "a016_phaseUhighUv" 15 "a015_gateDriveEeprom" 14 "a014_gateDriveTxError" 13 "a013_gateDriveError" 12 "a012_currentSensCalError" 11 "a011_currentSensError" 10 "a010_trqSensCalError" 9 "a009_sentDiff" 8 "a008_trqSens2Eeprom" 7 "a007_trqSens2Supply" 6 "a006_sent2Error" 5 "a005_sent2Mia" 4 "a004_trqSens1Eeprom" 3 "a003_trqSens1Supply" 2 "a002_sent1Error" 1 "a001_sent1Mia" 0 "ALERT_DO_NOT_USE_ZERO" ;
VAL_ 1426 EPAS3P_alertState 1 "SET" 0 "CLEARED" ;
VAL_ 1426 EPAS3P_a147_transitionReason 2 "MIA" 1 "WSS_FAILURE" 0 "DATA_INTEGRITY" ;
VAL_ 2036 EPAS3P_matrixIndex 2 "AlertMatrix2" 1 "AlertMatrix1" 0 "AlertMatrix0" ;
VAL_ 883 EPAS3P_steeringRackForce 1023 "SNA" 1022 "NOT_IN_SPEC" ;
VAL_ 883 EPAS3P_steeringFault 1 "FAULT" 0 "NO_FAULT" ;
VAL_ 883 EPAS3P_steeringReduced 1 "REDUCED_ASSIST" 0 "NORMAL_ASSIST" ;
VAL_ 883 EPAS3P_internalSASQF 1 "IN_SPEC" 0 "UNDEFINABLE_ACCURACY" ;
VAL_ 883 EPAS3P_currentTuneMode 5 "STEERING_TUNE_RWD_SPORT" 4 "STEERING_TUNE_RWD_STANDARD" 3 "STEERING_TUNE_RWD_COMFORT" 2 "STEERING_TUNE_DM_SPORT" 1 "STEERING_TUNE_DM_STANDARD" 0 "STEERING_TUNE_DM_COMFORT" ;
VAL_ 883 EPAS3P_torsionBarTorque 4095 "SNA" 4094 "UNDEFINABLE_DATA" ;
VAL_ 883 EPAS3P_eacErrorCode 15 "SNA" 14 "EAC_EXTERNAL_MONITOR_INHIBIT" 13 "EAC_ERROR_PINION_VEL_DIFF" 12 "EAC_ERROR_LOW_ASSIST" 11 "EAC_ERROR_HIGH_TORSION_SAFETY" 10 "EAC_ERROR_HIGH_MMOT_SAFETY" 9 "EAC_ERROR_HIGH_ANGLE_RATE_SAFETY" 8 "EAC_ERROR_HIGH_ANGLE_SAFETY" 7 "EAC_ERROR_HIGH_ANGLE_RATE_REQ" 6 "EAC_ERROR_HIGH_ANGLE_REQ" 5 "EAR_ERROR_MAX_STEER_DELTA" 4 "EAC_ERROR_TMP_FAULT" 3 "EAC_ERROR_HANDS_ON" 2 "EAC_ERROR_MAX_SPEED" 1 "EAC_ERROR_MIN_SPEED" 0 "EAC_ERROR_IDLE" ;
VAL_ 883 EPAS3P_handsOnLevel 3 "LEVEL_3" 2 "LEVEL_2" 1 "LEVEL_1" 0 "LEVEL_0" ;
VAL_ 883 EPAS3P_eacStatus 7 "EAC_ELK_ACTIVE" 6 "EAC_ELK_AVAILABLE" 5 "EAC_LKA_ACTIVE" 4 "EAC_LKA_ELK_AVAILABLE" 3 "EAC_FAULT" 2 "EAC_ACTIVE" 1 "EAC_AVAILABLE" 0 "EAC_INHIBITED" ;
VAL_ 1425 EPAS3S_alertID 156 "a156_angleSensorDivergence" 155 "a155_backupEacActive" 154 "a154_assistTorqueDisabled" 153 "a153_dcsInitOffset" 152 "a152_dcsDiagReg" 151 "a151_dcsCboot" 150 "a150_currentSensOffsetDetect" 149 "a149_currentSensPathSwitch" 148 "a148_vMaxAssist" 147 "a147_backupVehSpeed" 146 "a146_diSpdCsError" 145 "a145_diSpdCntError" 144 "a144_diSpdMia" 137 "a137_piCtrlCounter85" 136 "a136_piCtrlCounter50" 135 "a135_piCtrlCounter25" 134 "a134_motFeedFwdCounter85" 133 "a133_motFeedFwdCounter50" 132 "a132_motFeedFwdCounter25" 131 "a131_phaseFeedbackError" 130 "a130_sasOffsetNotCal" 129 "a129_combEcu1StatFail" 128 "a128_apsCsError" 127 "a127_apsCntError" 126 "a126_apsMia" 125 "a125_trqSensTrimOutRange" 124 "a124_tempSensStuckInRange" 123 "a123_combEcu2StatFail" 122 "a122_olpActive" 121 "a121_pvtEcuStatCrcError" 120 "a120_pvtEcuStatCntError" 119 "a119_pvtEcuStatMia" 118 "a118_privateBusOff" 117 "a117_ecuStatCrcError" 116 "a116_ecuStatCntError" 115 "a115_ecuStatMia" 114 "a114_gtwConfigMia" 113 "a113_sasStatusError" 112 "a112_sasCsError" 111 "a111_sasCntError" 110 "a110_sasMia" 109 "a109_uiTuneReqCsError" 108 "a108_uiTuneReqCntError" 107 "a107_uiTuneReqMia" 106 "a106_vcFrontTempMia" 105 "a105_vcFrontCsError" 104 "a104_vcFrontCntError" 103 "a103_vcFrontMia" 102 "a102_diCsError" 101 "a101_diCntError" 100 "a100_diMia" 99 "a099_yawRateStatus" 98 "a098_rcmCsError" 97 "a097_rcmCntError" 96 "a096_rcmMia" 95 "a095_espWsStatus" 94 "a094_espWrCsError" 93 "a093_espWrCntError" 92 "a092_espWrMia" 91 "a091_espWsCsError" 90 "a090_espWsCntError" 89 "a089_espWsMia" 88 "a088_dasCsError" 87 "a087_dasCntError" 86 "a086_dasMia" 85 "a085_canBusOff" 84 "a084_eacCancelled" 83 "a083_crcMismatch" 82 "a082_polarityCalError" 81 "a081_coggCompError" 80 "a080_ecuInitArbError" 79 "a079_backupCurrentPlaus" 78 "a078_phaseDisconnectError" 77 "a077_highSideFetError" 76 "a076_tempSensOutofRange" 75 "a075_fspPwrCut" 74 "a074_overHeatProtect" 73 "a073_motParEstError" 72 "a072_motFeedFwdError" 71 "a071_vehSpdCorrError" 70 "a070_hodCorrError" 69 "a069_eacCorrError" 68 "a068_hystCorrError" 67 "a067_yawDampCorrError" 66 "a066_returnCorrError" 65 "a065_trqTarCorrError" 64 "a064_phaseCompCorrError" 63 "a063_dampCorrError" 62 "a062_assistCorrError" 61 "a061_bridgeUv" 60 "a060_battBridgeDiff" 59 "a059_battOvReduced" 58 "a058_battOv" 57 "a057_battUvReduced" 56 "a056_battUv" 55 "a055_floatPointError" 54 "a054_memoryProtectError" 53 "a053_extWatchdogError" 52 "a052_intWatchdogError" 51 "a051_mcuSupError" 50 "a050_mcuSmuError" 49 "a049_piCtrlError" 48 "a048_motPosCalError" 47 "a047_motPosCorrError" 46 "a046_motPos2tempError" 45 "a045_motPos2LogicError" 44 "a044_motPos2MagnetMia" 43 "a043_motPos2Uv" 42 "a042_motPos2ParityError" 41 "a041_motPos1tempError" 40 "a040_motPos1LogicError" 39 "a039_motPos1MagnetMia" 38 "a038_motPos1Uv" 37 "a037_motPos1ParityError" 36 "a036_vbbSupplyOv" 35 "a035_vbbSupplyUv" 34 "a034_vRegError" 33 "a033_vRegOutputOv" 32 "a032_vRegOutputUv" 31 "a031_abnormalShutdown" 30 "a030_phaseWbootUv" 29 "a029_phaseVbootUv" 28 "a028_phaseUbootUv" 27 "a027_phaseWlowOv" 26 "a026_phaseWhighOv" 25 "a025_phaseVlowOv" 24 "a024_phaseVhighOv" 23 "a023_phaseUlowOv" 22 "a022_phaseUhighOv" 21 "a021_phaseWlowUv" 20 "a020_phaseWhighUv" 19 "a019_phaseVlowUv" 18 "a018_phaseVhighUv" 17 "a017_phaseUlowUv" 16 "a016_phaseUhighUv" 15 "a015_gateDriveEeprom" 14 "a014_gateDriveTxError" 13 "a013_gateDriveError" 12 "a012_currentSensCalError" 11 "a011_currentSensError" 10 "a010_trqSensCalError" 9 "a009_sentDiff" 8 "a008_trqSens2Eeprom" 7 "a007_trqSens2Supply" 6 "a006_sent2Error" 5 "a005_sent2Mia" 4 "a004_trqSens1Eeprom" 3 "a003_trqSens1Supply" 2 "a002_sent1Error" 1 "a001_sent1Mia" 0 "ALERT_DO_NOT_USE_ZERO" ;
VAL_ 1425 EPAS3S_alertState 1 "SET" 0 "CLEARED" ;
VAL_ 1425 EPAS3S_a147_transitionReason 2 "MIA" 1 "WSS_FAILURE" 0 "DATA_INTEGRITY" ;
VAL_ 913 EPAS3S_matrixIndex 2 "AlertMatrix2" 1 "AlertMatrix1" 0 "AlertMatrix0" ;
VAL_ 882 EPAS3S_steeringRackForce 1023 "SNA" 1022 "NOT_IN_SPEC" ;
VAL_ 882 EPAS3S_steeringFault 1 "FAULT" 0 "NO_FAULT" ;
VAL_ 882 EPAS3S_steeringReduced 1 "REDUCED_ASSIST" 0 "NORMAL_ASSIST" ;
VAL_ 882 EPAS3S_internalSASQF 1 "IN_SPEC" 0 "UNDEFINABLE_ACCURACY" ;
VAL_ 882 EPAS3S_currentTuneMode 5 "STEERING_TUNE_RWD_SPORT" 4 "STEERING_TUNE_RWD_STANDARD" 3 "STEERING_TUNE_RWD_COMFORT" 2 "STEERING_TUNE_DM_SPORT" 1 "STEERING_TUNE_DM_STANDARD" 0 "STEERING_TUNE_DM_COMFORT" ;
VAL_ 882 EPAS3S_torsionBarTorque 4095 "SNA" 4094 "UNDEFINABLE_DATA" ;
VAL_ 882 EPAS3S_eacErrorCode 15 "SNA" 14 "EAC_EXTERNAL_MONITOR_INHIBIT" 13 "EAC_ERROR_PINION_VEL_DIFF" 12 "EAC_ERROR_LOW_ASSIST" 11 "EAC_ERROR_HIGH_TORSION_SAFETY" 10 "EAC_ERROR_HIGH_MMOT_SAFETY" 9 "EAC_ERROR_HIGH_ANGLE_RATE_SAFETY" 8 "EAC_ERROR_HIGH_ANGLE_SAFETY" 7 "EAC_ERROR_HIGH_ANGLE_RATE_REQ" 6 "EAC_ERROR_HIGH_ANGLE_REQ" 5 "EAR_ERROR_MAX_STEER_DELTA" 4 "EAC_ERROR_TMP_FAULT" 3 "EAC_ERROR_HANDS_ON" 2 "EAC_ERROR_MAX_SPEED" 1 "EAC_ERROR_MIN_SPEED" 0 "EAC_ERROR_IDLE" ;
VAL_ 882 EPAS3S_handsOnLevel 3 "LEVEL_3" 2 "LEVEL_2" 1 "LEVEL_1" 0 "LEVEL_0" ;
VAL_ 882 EPAS3S_eacStatus 7 "EAC_ELK_ACTIVE" 6 "EAC_ELK_AVAILABLE" 5 "EAC_LKA_ACTIVE" 4 "EAC_LKA_ELK_AVAILABLE" 3 "EAC_FAULT" 2 "EAC_ACTIVE" 1 "EAC_AVAILABLE" 0 "EAC_INHIBITED" ;
VAL_ 1427 EPASTP_alertID 270 "a270_oscillationCompTrqLimReached" 269 "a269_assistTorqueDisabled" 268 "a268_eacCancelled" 267 "a267_safeSpeedAssist" 266 "a266_overloadProtect" 265 "a265_overheatProtect" 264 "a264_assistTorqueLimited" 263 "a263_espWsStatus" 262 "a262_yawRateStatus" 261 "a261_sccmStatusError" 260 "a260_scoPrivateBusOff" 259 "a259_scoCanBusOff" 258 "a258_pspInvalidProjectParamset" 257 "a257_dcvmUnderVolt" 256 "a256_dcvmOverVolt" 255 "a255_pmState2Mia" 254 "a254_vcFrontMia" 253 "a253_vcFrontCsError" 252 "a252_vcFrontCntError" 251 "a251_uiTuneReqMia" 250 "a250_uiTuneReqCsError" 249 "a249_uiTuneReqCntError" 248 "a248_sccmMia" 247 "a247_sccmCsError" 246 "a246_sccmCntError" 245 "a245_rcmMia" 244 "a244_rcmCsError" 243 "a243_rcmCntError" 242 "a242_gtwConfigMia" 241 "a241_espWsMia" 240 "a240_espWsCsError" 239 "a239_espWsCntError" 238 "a238_espWrMia" 237 "a237_espWrCsError" 236 "a236_espWrCntError" 235 "a235_ecu2StatMia" 234 "a234_ecu2StatCsError" 233 "a233_ecu2StatCntError" 232 "a232_diSpdMia" 231 "a231_diSpdCsError" 230 "a230_diSpdCntError" 229 "a229_dirTorqueMia" 228 "a228_dirTorqueCsError" 227 "a227_dirTorqueCntError" 226 "a226_dasMia" 225 "a225_dasCsError" 224 "a224_dasCntError" 223 "a223_apsMia" 222 "a222_apsCsError" 221 "a221_apsCntError" 219 "a219_frhFastRestartFailed" 218 "a218_aadApplicationStateErr" 217 "a217_msdMasterSilentErr" 216 "a216_isdgImproperShutdown" 215 "a215_vsgSafeViolErr" 214 "a214_velInterfaceErr" 213 "a213_frmHighFrictionDetected" 212 "a212_frmDataLost" 211 "a211_frmInternalErr" 210 "a210_fdrTotalBlocking" 209 "a209_fdrLowSeverityFreezing" 208 "a208_fdrLowSeverityBlocking" 207 "a207_fdrOclFreezing" 206 "a206_fdrOclPartialBlocking" 205 "a205_fdrOclFail" 204 "a204_fdpPrevTrqErr" 203 "a203_ctcInterfaceErr" 202 "a202_ohnvmpStoredOffsetLost" 201 "a201_ammOutputBufferOverflow" 200 "a200_ammInputBufferOverflow" 199 "a199_osumC1StackNearFull" 198 "a198_osumC1CsaNearFull" 197 "a197_difpDifactorInvalid" 196 "a196_topEolTasOffsetInvalid" 195 "a195_imcmCommErrC1" 194 "a194_amNvdataLoss" 193 "a193_osumC0StackNearFull" 192 "a192_osumC0CsaNearFull" 191 "a191_sbcscpVcp2VucVoltFail" 190 "a190_sbchCommBufferOverflow" 189 "a189_sbchCommErrMcuToSbc" 188 "a188_epmCommBufferOverflow" 187 "a187_epmVoltFail" 186 "a186_wdhCommBufferOverflow" 185 "a185_sbcscpQAWatchdogReset" 184 "a184_sbcmCommBufferOverflow" 183 "a183_sbchCommErrSbcToMcu" 182 "a182_mcdInputMia" 181 "a181_dmDeadlineViolationC1" 180 "a180_dmDeadlineViolationC1" 179 "a179_tedMotorcoilTempChecker" 178 "a178_exchWdtException" 177 "a177_etsrInvalidated" 176 "a176_exchCpu1ExceptionReset" 175 "a175_exchFlashStoredConfigErr" 174 "a174_pmpPhasecurrentAge" 173 "a173_pmpRotorspeedAge" 172 "a172_pmpElangMotorcurrentAge" 171 "a171_pmpKgvalueAge" 170 "a170_pmpDcvoltAge" 169 "a169_scpSafetyReset" 168 "a168_c1csInvalidC1App" 167 "a167_iccd1ErrQueueOverflow" 166 "a166_tdaPhasecurrentshuntTempChecker" 165 "a165_tdaDcbusshuntTempChecker" 164 "a164_tdaBattfetjunctionTempChecker" 163 "a163_tdaPowermoduleTempChecker" 162 "a162_tdaBridgefetjunctionTempChecker" 161 "a161_tdaRelayfetjunctionTempChecker" 160 "a160_rsthCpu1UnexpectedAlarm" 159 "a159_exchFlashWordlineTransientErr" 158 "a158_amGduFailDuringRecovery" 157 "a157_mcudcpInvalidEcuId" 156 "a156_amIntSerialErrSafetyReset" 155 "a155_sdsmDataInvalidAll" 154 "a154_sdsmCsErrorInvalidPrimary" 153 "a153_sdsmBlockSelectorInvalid" 152 "a152_exchFlashEccException" 151 "a151_amPermanentEmergencyOffRequested" 150 "a150_amExternalEmergencyOffRequested" 149 "a149_amReversibleEmergencyOffRequested" 148 "a148_mrccExitFromStandbyDetected" 147 "a147_amDcLinkShortedFail" 146 "a146_btarcRcCircuitCheck" 145 "a145_mriPeripheralRaminitFailed" 144 "a144_mriCoreRaminitFailed" 143 "a143_tedEmifilterCmcTempChecker" 142 "a142_tedEmifilterDmcTempChecker" 141 "a141_amFetShortTest" 140 "a140_imcmConfigurationErr" 139 "a139_osehAdditionalOsErr" 138 "a138_osehAdditionalErrWithoutImmReset" 137 "a137_osehErrWithoutImmediateReset" 136 "a136_ftElectricalAngleQf" 135 "a135_tmpsfetjCalculationOverflowErr" 134 "a134_osehGuardedResetAfterErrWithoutReset" 133 "a133_mcusscLbistEcuIdIsNotSupported" 132 "a132_mcusscNotSupportedMcu" 131 "a131_exchGuardedResetAfterPartitionStop" 130 "a130_mrccConfigCsErrorErr" 129 "a129_exchAdditionalExceptionStopRestart" 128 "a128_exchExceptionStopRestart" 127 "a127_exchAdditionalExceptionAfterRst" 126 "a126_mcusscMonbistMiaErr" 125 "a125_mcusscMbistMiaErr" 124 "a124_mcusscMbistEccTransientErr" 123 "a123_imcmCommErr" 122 "a122_pcpBridgeFetShort" 121 "a121_mcusscMbistEccErr" 120 "a120_mcusscFlashEccLatentErr" 119 "a119_mcusscFlashEccCriticalErr" 118 "a118_mcusscFlashCsErrorErr" 117 "a117_mrccStartupRegCsErrorTransientErr" 116 "a116_mrccStartupRegCsErrorStaticErr" 115 "a115_mcusscLbistSingleFail" 114 "a114_osehOsErr" 113 "a113_rsthUncorrectableEndToEndBusErr" 112 "a112_rsthSafetyFlipflopErr" 111 "a111_amCurrentSensingDisconnection" 110 "a110_amPhaseRelaySwitchOffTest" 109 "a109_exhaSysBusOrPeriphErrException" 108 "a108_exhaInternalProtectionException" 107 "a107_exhaOtherNmiException" 106 "a106_exhaSpbBusErrException" 105 "a105_exhaSriBusErrException" 104 "a104_exhaBusMpuException" 103 "a103_exhaUnusedInterruptCallException" 102 "a102_amPhasecurrentQosErr" 101 "a101_sdrvSpcIdMismatch" 100 "a100_amVbrgLssFault" 99 "a099_mcdTorqueMismatchFault" 98 "a098_invErr" 97 "a097_rppRpsMultipleStaticFail" 96 "a096_rppRpsSingleStaticFail" 95 "a095_mdModelBasedMotorIntegrityCheck" 94 "a094_sctpTsuMultipleStaticFail" 93 "a093_sctpTsuSingleStaticFail" 92 "a092_amGduSwitchOffTestBySbc" 91 "a091_bvpBattVoltCrossChkFailed" 90 "a090_etsmWarning" 89 "a089_tedRevercebattfetjunctionTempChecker" 88 "a088_tedMainboardTempChecker" 87 "a087_rsthFlashConfigErr" 86 "a086_rsthRamUncorrEcc" 85 "a085_amGduSwitchOffTestByMcu" 84 "a084_adcTriggerCheck" 83 "a083_tdaDclinkcapacitorTempChecker" 82 "a082_adcTriggerTimeChk" 81 "a081_exchFloatingPointException" 80 "a080_pwmTimerSyncCheck" 79 "a079_gduhComErr" 78 "a078_dmDeadlineViolation" 77 "a077_dmDeadlineViolation" 76 "a076_exchGeneralException" 75 "a075_rsthUnusedOtherModuleAlarm" 74 "a074_rsthUnexpectedAlarm" 73 "a073_rsthOtherEdcEcc" 72 "a072_rsthFlashUncorrEccOrOvfl" 71 "a071_rsthInternalHighVolt" 70 "a070_rsthInternalLowVolt" 69 "a069_rsthCoreTempOutOfRangeHwCheck" 68 "a068_rsthCoreRedundancyErr" 67 "a067_tspmPowermoduleTempImplausible" 66 "a066_amVoltQfErr" 65 "a065_amGduJuncTemp" 64 "a064_amBridgeShort" 63 "a063_amIntRegulatorErr" 62 "a062_amPhaseBridgeCheck" 61 "a061_amIntSerialErr" 60 "a060_amGduFail" 59 "a059_amStartupTestFailed" 58 "a058_amIntVgsUndervtgErr" 57 "a057_amGduVds" 56 "a056_amGduConfigCsErrorCheck" 55 "a055_amExtendedGduTest" 54 "a054_adcUnexpectedData" 53 "a053_adcUnexpectedNumOfData" 52 "a052_ermSdcInputBufferOverflow" 51 "a051_ermMessageErr" 50 "a050_erlErr" 49 "a049_epmLgFail" 48 "a048_epmVcpVoltFail" 47 "a047_epmVregVoltFail" 46 "a046_mcusscOscillatorNotReliable" 45 "a045_psumSbcBandgapVoltErr" 44 "a044_sbcmSbcEepromFail" 43 "a043_sbcmWdStateDisabled" 42 "a042_wdhWdTestFail" 41 "a041_imcmCoreConfigurationMismatch" 40 "a040_swrhLimitedResetRetriesExpired" 39 "a039_csohCh2CsErrorErrAtReset" 38 "a038_csohCh1CsErrorErrAtReset" 37 "a037_epmV5P2Fail" 36 "a036_sbcmSbcBistFailed" 35 "a035_sbchChipIdFail" 34 "a034_sbchReadbackRegFail" 33 "a033_icsvcPswVersionMismatch" 32 "a032_eolpEolCheckFailed" 31 "a031_pmsProductionModeFailed" 30 "a030_rsthClockReset" 29 "a029_smuhSmuCoreCntErrorTestFail" 28 "a028_smuhNonInitDataCorruption" 27 "a027_mcusscDmuHfErr" 26 "a026_mrccCsErrorCheckFail" 25 "a025_btarcCorruptionCheck" 24 "a024_srhCsErrorCheckFail" 23 "a023_btarcCorruptionCheck" 22 "a022_swrhSwResetInfoCorruptionCheck" 21 "a021_osehCsErrorCheck" 20 "a020_mcusscEolEcuIdIntegritiyFail" 19 "a019_rsthHwResetInfoCorruptionCheck" 18 "a018_exchCsErrorCheck" 17 "a017_stmdStmPlausibilityCheckErr" 16 "a016_mcufcCsErrorCheckFail" 15 "a015_mcusscCsErrorCheckFail" 14 "a014_mcusscSffMonitoringMia" 13 "a013_mcusscSffMonitoringFailed" 12 "a012_mcusscMbistEccErr" 11 "a011_mcusscMonbistErr" 10 "a010_svcIncompatibleSwVersions" 9 "a009_mcusscLbistPermanentFail" 8 "a008_psdcPlatformShutdown" 7 "a007_tsmcCoreTempDiff" 6 "a006_swrhResetByInvalidErrid" 5 "a005_scpUnknownResetSource" 4 "a004_scpInputMia" 3 "a003_pspInvalidParamset" 2 "a002_adcMuxErr" 1 "a001_adcCalibrationOrInitFail" 0 "ALERT_DO_NOT_USE_ZERO" ;
VAL_ 1427 EPASTP_alertState 1 "SET" 0 "CLEARED" ;
VAL_ 1427 EPASTP_a264_degradedECU 3 "BOTH_ECU_SIDES" 2 "OTHER_ECU_SIDE" 1 "OWN_ECU_SIDE" 0 "NONE" ;
VAL_ 1427 EPASTP_a264_ownSideDegradationRe 92 "DC_LINK_CAPACITOR_HOTSPOTCASEDIFF_TEMPERATURE" 84 "PHASECURRENT_SHUNT_TEMPERATURE_MOMENTARY" 80 "DC_LINK_CAPACITOR_TEMPERATURE" 52 "EMIFILTER_DMC_TEMPERATURE" 48 "EMIFILTER_CMC_TEMPERATURE" 44 "DCLINK_SHUNT_TEMPERATURE" 40 "PHASECURRENT_SHUNT_TEMPERATURE" 36 "POWER_MODULE_TEMPERATURE" 32 "MOTOR_COIL_TEMPERATURE" 28 "BATTERY_FET_JUNCTION_TEMPERATURE" 24 "MAIN_BOARD_TEMPERATURE" 20 "REVERSE_BATTERY_FET_JUNCTION_TEMPERATURE" 12 "RELAY_FET_JUNCTION_TEMPERATURE" 8 "BRIDGE_FET_JUNCTION_TEMPERATURE" 4 "CORE1_DEGRADATION" 0 "NO_DEGRADATION_ON_THIS_ECU_SIDE" ;
VAL_ 1427 EPASTP_a264_otherSideDegradation 92 "DC_LINK_CAPACITOR_HOTSPOTCASEDIFF_TEMPERATURE" 84 "PHASECURRENT_SHUNT_TEMPERATURE_MOMENTARY" 80 "DC_LINK_CAPACITOR_TEMPERATURE" 52 "EMIFILTER_DMC_TEMPERATURE" 48 "EMIFILTER_CMC_TEMPERATURE" 44 "DCLINK_SHUNT_TEMPERATURE" 40 "PHASECURRENT_SHUNT_TEMPERATURE" 36 "POWER_MODULE_TEMPERATURE" 32 "MOTOR_COIL_TEMPERATURE" 28 "BATTERY_FET_JUNCTION_TEMPERATURE" 24 "MAIN_BOARD_TEMPERATURE" 20 "REVERSE_BATTERY_FET_JUNCTION_TEMPERATURE" 12 "RELAY_FET_JUNCTION_TEMPERATURE" 8 "BRIDGE_FET_JUNCTION_TEMPERATURE" 4 "CORE1_DEGRADATION" 0 "NO_DEGRADATION_ON_THIS_ECU_SIDE" ;
VAL_ 1427 EPASTP_a265_degradedECU 3 "BOTH_ECU_SIDES" 2 "OTHER_ECU_SIDE" 1 "OWN_ECU_SIDE" 0 "NONE" ;
VAL_ 1427 EPASTP_a267_velocityEstimatorSta 5 "BACKUP_MOTOR" 4 "BACKUP_WHEELS_B" 3 "BACKUP_WHEELS_A" 2 "WHEELS_REDUCED" 1 "WHEELS_NORMAL" 0 "NOT_INITIALIZED" ;
